VERSION "2021.24.4"

NS_ :

BS_:

BU_: VEH CH Receiver X

BA_DEF_ BO_ "GenMsgSendType" ENUM "Cyclic";
BA_DEF_ BO_ "GenMsgCycleTime" INT 0 10000;

BO_ 1373 VCLEFT_alertLog: 8 Vector__XXX
 SG_ VCLEFT_a058_faultReason m58 : 63|1@1+ (1,0) [0|0] "" Vector__XXX
 SG_ VCLEFT_a150_treatedInGear m150 : 63|1@1+ (1,0) [0|0] "" Vector__XXX
 SG_ VCLEFT_a151_treatedInGear m151 : 63|1@1+ (1,0) [0|0] "" Vector__XXX
 SG_ VCLEFT_a381_earlyReport m381 : 63|1@1+ (1,0) [0|0] "" Vector__XXX
 SG_ VCLEFT_a173_btnTimeMsAutoDownRR m173 : 60|4@1+ (50,0) [0|0] "" Vector__XXX
 SG_ VCLEFT_a351_shadowAlert m351 : 60|1@1+ (1,0) [0|0] "" Vector__XXX
 SG_ VCLEFT_a381_alertVersion m381 : 60|3@1+ (1,0) [0|0] "" Vector__XXX
 SG_ VCLEFT_a383_motorType m383 : 60|2@1+ (1,0) [0|0] "" Vector__XXX
 SG_ VCLEFT_a384_motorType m384 : 60|2@1+ (1,0) [0|0] "" Vector__XXX
 SG_ VCLEFT_a385_motorType m385 : 60|2@1+ (1,0) [0|0] "" Vector__XXX
 SG_ VCLEFT_a386_motorType m386 : 60|2@1+ (1,0) [0|0] "" Vector__XXX
 SG_ VCLEFT_a387_motorType m387 : 60|2@1+ (1,0) [0|0] "" Vector__XXX
 SG_ VCLEFT_a388_motorType m388 : 60|2@1+ (1,0) [0|0] "" Vector__XXX
 SG_ VCLEFT_a389_motorType m389 : 60|2@1+ (1,0) [0|0] "" Vector__XXX
 SG_ VCLEFT_a390_motorType m390 : 60|2@1+ (1,0) [0|0] "" Vector__XXX
 SG_ VCLEFT_a166_SHORT_RISE_FAILED_EN m166 : 59|1@1+ (1,0) [0|0] "" Vector__XXX
 SG_ VCLEFT_a481_currentSenseFailure m481 : 59|1@1+ (1,0) [0|0] "" Vector__XXX
 SG_ VCLEFT_a166_ENC_LOSS_SHORT_DROP m166 : 58|1@1+ (1,0) [0|0] "" Vector__XXX
 SG_ VCLEFT_a192_motorType m192 : 58|2@1+ (1,0) [0|0] "" Vector__XXX
 SG_ VCLEFT_a381_tireFitment m381 : 58|2@1+ (1,0) [0|0] "" Vector__XXX
 SG_ VCLEFT_a382_massEstimate m382 : 58|6@1+ (25,1900) [0|0] "" Vector__XXX
 SG_ VCLEFT_a481_currentSenseFinished m481 : 58|1@1+ (1,0) [0|0] "" Vector__XXX
 SG_ VCLEFT_a499_cdpUncommanedActuati m499 : 58|1@1+ (1,0) [0|0] "" Vector__XXX
 SG_ VCLEFT_a066_shortPeriodLength3 m66 : 57|7@1+ (10,0) [0|0] "" Vector__XXX
 SG_ VCLEFT_a150_speedExpScore m150 : 57|6@1- (0.0006451612903225806,-0.009677419354838708) [0|0] "" Vector__XXX
 SG_ VCLEFT_a151_speedExpScore m151 : 57|6@1- (0.0006451612903225806,-0.009677419354838708) [0|0] "" Vector__XXX
 SG_ VCLEFT_a166_AUTO_DOWN_HELD m166 : 57|1@1+ (1,0) [0|0] "" Vector__XXX
 SG_ VCLEFT_a192_motorNotIdentified m192 : 57|1@1+ (1,0) [0|0] "" Vector__XXX
 SG_ VCLEFT_a499_cdpEpbDynamicFault m499 : 57|1@1+ (1,0) [0|0] "" Vector__XXX
 SG_ VCLEFT_a022_TaskInitError4 m22 : 56|8@1+ (1,0) [0|0] "" Vector__XXX
 SG_ VCLEFT_a031_uds_bytes_5 m31 : 56|8@1+ (1,0) [0|0] "" Vector__XXX
 SG_ VCLEFT_a041_CPULoadNVMMTask m41 : 56|8@1+ (1,0) [0|0] "" Vector__XXX
 SG_ VCLEFT_a042_UsageNVMMTask m42 : 56|8@1+ (1,0) [0|0] "" Vector__XXX
 SG_ VCLEFT_a166_SOFT_STOP_OVERRIDE m166 : 56|1@1+ (1,0) [0|0] "" Vector__XXX
 SG_ VCLEFT_a173_btnTimeMsDownRR m173 : 56|4@1+ (50,0) [0|0] "" Vector__XXX
 SG_ VCLEFT_a192_payloadBitsNotSet m192 : 56|1@1+ (1,0) [0|0] "" Vector__XXX
 SG_ VCLEFT_a316_ambientTemperatureDe m316 : 56|8@1+ (0.5,-40) [0|0] "" Vector__XXX
 SG_ VCLEFT_a362_alertWhileMoving m362 : 56|1@1+ (1,0) [0|0] "" Vector__XXX
 SG_ VCLEFT_a393_anyClosureOpen m393 : 56|1@1+ (1,0) [0|0] "" Vector__XXX
 SG_ VCLEFT_a499_cdpNoParkButtonTimeo m499 : 56|1@1+ (1,0) [0|0] "" Vector__XXX
 SG_ VCLEFT_a523_control3Byte3 m523 : 56|8@1+ (1,0) [0|0] "" Vector__XXX
 SG_ VCLEFT_a546_ambientTemperature m546 : 56|8@1+ (0.5,-40) [0|0] "" Vector__XXX
 SG_ VCLEFT_a166_CAL_CLEAR_ENC_LOSS m166 : 55|1@1+ (1,0) [0|0] "" Vector__XXX
 SG_ VCLEFT_a393_deltaTrackingValidit m393 : 55|1@1+ (1,0) [0|0] "" Vector__XXX
 SG_ VCLEFT_a499_cdpValidActivationFa m499 : 55|1@1+ (1,0) [0|0] "" Vector__XXX
 SG_ VCLEFT_a166_SHORT_DROP_FAILED m166 : 54|1@1+ (1,0) [0|0] "" Vector__XXX
 SG_ VCLEFT_a360_instantAngle m360 : 54|10@1+ (1e-05,0) [0|0] "" Vector__XXX
 SG_ VCLEFT_a393_fusionValidityOK m393 : 54|1@1+ (1,0) [0|0] "" Vector__XXX
 SG_ VCLEFT_a499_parkButtonPressed m499 : 54|1@1+ (1,0) [0|0] "" Vector__XXX
 SG_ VCLEFT_a113_VEH_hvacDebugControl m113 : 53|1@1+ (1,0) [0|0] "" Vector__XXX
 SG_ VCLEFT_a166_PINCH_TABLE_REJECTED m166 : 53|1@1+ (1,0) [0|0] "" Vector__XXX
 SG_ VCLEFT_a192_lsVdsOvervoltageMask m192 : 53|3@1+ (1,0) [0|0] "" Vector__XXX
 SG_ VCLEFT_a200_phantomTicks m200 : 53|11@1- (1,0) [0|0] "" Vector__XXX
 SG_ VCLEFT_a499_remoteEpbmEpbDynamic m499 : 53|1@1+ (1,0) [0|0] "" Vector__XXX
 SG_ VCLEFT_a113_VEH_weatherDataServi m113 : 52|1@1+ (1,0) [0|0] "" Vector__XXX
 SG_ VCLEFT_a166_INT_SWITCH_IGNORED m166 : 52|1@1+ (1,0) [0|0] "" Vector__XXX
 SG_ VCLEFT_a173_btnTimeMsAutoDownRF m173 : 52|4@1+ (50,0) [0|0] "" Vector__XXX
 SG_ VCLEFT_a180_latchClawStatus m180 : 52|1@1+ (1,0) [0|0] "" Vector__XXX
 SG_ VCLEFT_a181_latchClawStatus m181 : 52|1@1+ (1,0) [0|0] "" Vector__XXX
 SG_ VCLEFT_a192_lsVdsOvervoltage m192 : 52|1@1+ (1,0) [0|0] "" Vector__XXX
 SG_ VCLEFT_a218_motorDutyCycle m218 : 52|10@1+ (0.1,0) [0|0] "" Vector__XXX
 SG_ VCLEFT_a236_lumbarBState m236 : 52|3@1+ (1,0) [0|0] "" Vector__XXX
 SG_ VCLEFT_a237_lumbarBState m237 : 52|3@1+ (1,0) [0|0] "" Vector__XXX
 SG_ VCLEFT_a238_lumbarBState m238 : 52|3@1+ (1,0) [0|0] "" Vector__XXX
 SG_ VCLEFT_a263_seatMotorState m263 : 52|3@1+ (1,0) [0|0] "" Vector__XXX
 SG_ VCLEFT_a264_seatMotorState m264 : 52|3@1+ (1,0) [0|0] "" Vector__XXX
 SG_ VCLEFT_a265_seatMotorState m265 : 52|3@1+ (1,0) [0|0] "" Vector__XXX
 SG_ VCLEFT_a266_seatMotorState m266 : 52|3@1+ (1,0) [0|0] "" Vector__XXX
 SG_ VCLEFT_a267_seatMotorState m267 : 52|3@1+ (1,0) [0|0] "" Vector__XXX
 SG_ VCLEFT_a268_seatMotorState m268 : 52|3@1+ (1,0) [0|0] "" Vector__XXX
 SG_ VCLEFT_a269_seatMotorState m269 : 52|3@1+ (1,0) [0|0] "" Vector__XXX
 SG_ VCLEFT_a270_seatMotorState m270 : 52|3@1+ (1,0) [0|0] "" Vector__XXX
 SG_ VCLEFT_a323_calibrationDown m323 : 52|12@1+ (0.002,0) [0|0] "" Vector__XXX
 SG_ VCLEFT_a351_ambientTemperature m351 : 52|8@1+ (0.5,-40) [0|0] "" Vector__XXX
 SG_ VCLEFT_a426_cabinTmp m426 : 52|12@1- (0.1,0) [0|0] "" Vector__XXX
 SG_ VCLEFT_a427_cabinTmp m427 : 52|12@1- (0.1,0) [0|0] "" Vector__XXX
 SG_ VCLEFT_a428_cabinTmp m428 : 52|12@1- (0.1,0) [0|0] "" Vector__XXX
 SG_ VCLEFT_a429_cabinTmp m429 : 52|12@1- (0.1,0) [0|0] "" Vector__XXX
 SG_ VCLEFT_a499_localEpbmEpbDynamic m499 : 52|1@1+ (1,0) [0|0] "" Vector__XXX
 SG_ VCLEFT_a058_newREstimate m58 : 51|12@1+ (0.00061,0) [0|0] "" Vector__XXX
 SG_ VCLEFT_a113_VEH_frontSeatRequest m113 : 51|1@1+ (1,0) [0|0] "" Vector__XXX
 SG_ VCLEFT_a166_REAR_SWITCH_IGNORED m166 : 51|1@1+ (1,0) [0|0] "" Vector__XXX
 SG_ VCLEFT_a444_enableLow m444 : 51|1@1+ (1,0) [0|0] "" Vector__XXX
 SG_ VCLEFT_a499_espCdpActuating m499 : 51|1@1+ (1,0) [0|0] "" Vector__XXX
 SG_ VCLEFT_a066_shortPeriodLength2 m66 : 50|7@1+ (10,0) [0|0] "" Vector__XXX
 SG_ VCLEFT_a113_VEH_odo m113 : 50|1@1+ (1,0) [0|0] "" Vector__XXX
 SG_ VCLEFT_a228_seatSwitchForward m228 : 50|2@1+ (1,0) [0|0] "" Vector__XXX
 SG_ VCLEFT_a229_seatSwitchForward m229 : 50|2@1+ (1,0) [0|0] "" Vector__XXX
 SG_ VCLEFT_a230_seatSwitchForward m230 : 50|2@1+ (1,0) [0|0] "" Vector__XXX
 SG_ VCLEFT_a231_seatSwitchForward m231 : 50|2@1+ (1,0) [0|0] "" Vector__XXX
 SG_ VCLEFT_a426_seatSwitchForward m426 : 50|2@1+ (1,0) [0|0] "" Vector__XXX
 SG_ VCLEFT_a427_seatSwitchForward m427 : 50|2@1+ (1,0) [0|0] "" Vector__XXX
 SG_ VCLEFT_a428_seatSwitchForward m428 : 50|2@1+ (1,0) [0|0] "" Vector__XXX
 SG_ VCLEFT_a429_seatSwitchForward m429 : 50|2@1+ (1,0) [0|0] "" Vector__XXX
 SG_ VCLEFT_a444_voltageMonitor m444 : 50|1@1+ (1,0) [0|0] "" Vector__XXX
 SG_ VCLEFT_a481_currentSenseVoltageD m481 : 50|8@1+ (1,0) [0|0] "" Vector__XXX
 SG_ VCLEFT_a499_remoteEpbmCdpOkay m499 : 50|1@1+ (1,0) [0|0] "" Vector__XXX
 SG_ VCLEFT_a104_BDY_bodyControls m104 : 49|1@1+ (1,0) [0|0] "" Vector__XXX
 SG_ VCLEFT_a113_CH_vehicleControl2 m113 : 49|1@1+ (1,0) [0|0] "" Vector__XXX
 SG_ VCLEFT_a150_relAccelExceedance m150 : 49|8@1+ (0.09803921568627451,0) [0|0] "" Vector__XXX
 SG_ VCLEFT_a151_relAccelExceedance m151 : 49|8@1+ (0.09803921568627451,0) [0|0] "" Vector__XXX
 SG_ VCLEFT_a192_hsVdsOvervoltageMask m192 : 49|3@1+ (1,0) [0|0] "" Vector__XXX
 SG_ VCLEFT_a236_lumbarAState m236 : 49|3@1+ (1,0) [0|0] "" Vector__XXX
 SG_ VCLEFT_a237_lumbarAState m237 : 49|3@1+ (1,0) [0|0] "" Vector__XXX
 SG_ VCLEFT_a238_lumbarAState m238 : 49|3@1+ (1,0) [0|0] "" Vector__XXX
 SG_ VCLEFT_a381_timeElapsed m381 : 49|9@1+ (1,0) [0|0] "" Vector__XXX
 SG_ VCLEFT_a382_axOffset m382 : 49|9@1- (0.004,0) [0|0] "" Vector__XXX
 SG_ VCLEFT_a444_spiFault m444 : 49|1@1+ (1,0) [0|0] "" Vector__XXX
 SG_ VCLEFT_a481_softShortThresholdRe m481 : 49|1@1+ (1,0) [0|0] "" Vector__XXX
 SG_ VCLEFT_a499_localEpbmCdpOkay m499 : 49|1@1+ (1,0) [0|0] "" Vector__XXX
 SG_ VCLEFT_a000_alertDataW2 m0 : 48|16@1+ (1,0) [0|0] "" Vector__XXX
 SG_ VCLEFT_a003_Data m3 : 48|16@1+ (1,0) [0|0] "" Vector__XXX
 SG_ VCLEFT_a022_TaskInitError3 m22 : 48|8@1+ (1,0) [0|0] "" Vector__XXX
 SG_ VCLEFT_a031_uds_bytes_4 m31 : 48|8@1+ (1,0) [0|0] "" Vector__XXX
 SG_ VCLEFT_a041_CPULoad1000msTask m41 : 48|8@1+ (1,0) [0|0] "" Vector__XXX
 SG_ VCLEFT_a042_UsageUDSTask m42 : 48|8@1+ (1,0) [0|0] "" Vector__XXX
 SG_ VCLEFT_a104_VEH_redundantBraking m104 : 48|1@1+ (1,0) [0|0] "" Vector__XXX
 SG_ VCLEFT_a113_VEH_driverAssistMapD m113 : 48|1@1+ (1,0) [0|0] "" Vector__XXX
 SG_ VCLEFT_a120_BDY_speed m120 : 48|1@1+ (1,0) [0|0] "" Vector__XXX
 SG_ VCLEFT_a164_calibratedVoltage m164 : 48|6@1+ (0.25,0) [0|0] "" Vector__XXX
 SG_ VCLEFT_a167_pinchV3InUse m167 : 48|1@1+ (1,0) [0|0] "" Vector__XXX
 SG_ VCLEFT_a168_pinchV3InUse m168 : 48|1@1+ (1,0) [0|0] "" Vector__XXX
 SG_ VCLEFT_a173_btnTimeMsDownRF m173 : 48|4@1+ (50,0) [0|0] "" Vector__XXX
 SG_ VCLEFT_a180_latchStatus m180 : 48|4@1+ (1,0) [0|0] "" Vector__XXX
 SG_ VCLEFT_a181_latchStatus m181 : 48|4@1+ (1,0) [0|0] "" Vector__XXX
 SG_ VCLEFT_a192_hsVdsOvervoltage m192 : 48|1@1+ (1,0) [0|0] "" Vector__XXX
 SG_ VCLEFT_a202_epbConfig m202 : 48|4@1+ (1,0) [0|0] "" Vector__XXX
 SG_ VCLEFT_a203_epbConfig m203 : 48|4@1+ (1,0) [0|0] "" Vector__XXX
 SG_ VCLEFT_a204_epbConfig m204 : 48|4@1+ (1,0) [0|0] "" Vector__XXX
 SG_ VCLEFT_a205_epbConfig m205 : 48|4@1+ (1,0) [0|0] "" Vector__XXX
 SG_ VCLEFT_a211_epbConfig m211 : 48|4@1+ (1,0) [0|0] "" Vector__XXX
 SG_ VCLEFT_a212_epbConfig m212 : 48|4@1+ (1,0) [0|0] "" Vector__XXX
 SG_ VCLEFT_a213_epbConfig m213 : 48|4@1+ (1,0) [0|0] "" Vector__XXX
 SG_ VCLEFT_a214_epbConfig m214 : 48|4@1+ (1,0) [0|0] "" Vector__XXX
 SG_ VCLEFT_a216_byte3 m216 : 48|8@1+ (1,0) [0|0] "" Vector__XXX
 SG_ VCLEFT_a228_seatSwitchBack m228 : 48|2@1+ (1,0) [0|0] "" Vector__XXX
 SG_ VCLEFT_a229_seatSwitchBack m229 : 48|2@1+ (1,0) [0|0] "" Vector__XXX
 SG_ VCLEFT_a230_seatSwitchBack m230 : 48|2@1+ (1,0) [0|0] "" Vector__XXX
 SG_ VCLEFT_a231_seatSwitchBack m231 : 48|2@1+ (1,0) [0|0] "" Vector__XXX
 SG_ VCLEFT_a236_lumbarDiagStatus m236 : 48|1@1+ (1,0) [0|0] "" Vector__XXX
 SG_ VCLEFT_a237_lumbarDiagStatus m237 : 48|1@1+ (1,0) [0|0] "" Vector__XXX
 SG_ VCLEFT_a238_lumbarDiagStatus m238 : 48|1@1+ (1,0) [0|0] "" Vector__XXX
 SG_ VCLEFT_a321_maxCurrent m321 : 48|7@1+ (0.25,0) [0|0] "" Vector__XXX
 SG_ VCLEFT_a322_maxCurrent m322 : 48|7@1+ (0.25,0) [0|0] "" Vector__XXX
 SG_ VCLEFT_a325_PWMfaultFL m325 : 48|4@1+ (1,0) [0|0] "" Vector__XXX
 SG_ VCLEFT_a326_PWMfaultRL m326 : 48|4@1+ (1,0) [0|0] "" Vector__XXX
 SG_ VCLEFT_a327_PWMfaultFL m327 : 48|4@1+ (1,0) [0|0] "" Vector__XXX
 SG_ VCLEFT_a328_PWMfaultRL m328 : 48|4@1+ (1,0) [0|0] "" Vector__XXX
 SG_ VCLEFT_a345_powerCycleCount m345 : 48|12@1+ (1,0) [0|0] "" Vector__XXX
 SG_ VCLEFT_a351_liftgateLastState m351 : 48|4@1+ (1,0) [0|0] "" Vector__XXX
 SG_ VCLEFT_a352_liftgateClosingFaile m352 : 48|16@1+ (1,0) [0|0] "" Vector__XXX
 SG_ VCLEFT_a356_lastActiveState m356 : 48|3@1+ (1,0) [0|0] "" Vector__XXX
 SG_ VCLEFT_a391_pitchEstimateIMU m391 : 48|7@1- (0.001,0) [0|0] "" Vector__XXX
 SG_ VCLEFT_a393_gpsAccuracyRecent m393 : 48|6@1+ (0.2,0) [0|0] "" Vector__XXX
 SG_ VCLEFT_a426_seatSwitchBack m426 : 48|2@1+ (1,0) [0|0] "" Vector__XXX
 SG_ VCLEFT_a427_seatSwitchBack m427 : 48|2@1+ (1,0) [0|0] "" Vector__XXX
 SG_ VCLEFT_a428_seatSwitchBack m428 : 48|2@1+ (1,0) [0|0] "" Vector__XXX
 SG_ VCLEFT_a429_seatSwitchBack m429 : 48|2@1+ (1,0) [0|0] "" Vector__XXX
 SG_ VCLEFT_a444_spiPeriodicCheck m444 : 48|1@1+ (1,0) [0|0] "" Vector__XXX
 SG_ VCLEFT_a445_actualLSB m445 : 48|8@1+ (1,0) [0|0] "" Vector__XXX
 SG_ VCLEFT_a481_hardShortThresholdRe m481 : 48|1@1+ (1,0) [0|0] "" Vector__XXX
 SG_ VCLEFT_a499_anyCdpRequest m499 : 48|1@1+ (1,0) [0|0] "" Vector__XXX
 SG_ VCLEFT_a523_control3Byte2 m523 : 48|8@1+ (1,0) [0|0] "" Vector__XXX
 SG_ VCLEFT_a551_lastRequestSourceRea m551 : 48|3@1+ (1,0) [0|0] "" Vector__XXX
 SG_ VCLEFT_a104_VEH_control m104 : 47|1@1+ (1,0) [0|0] "" Vector__XXX
 SG_ VCLEFT_a113_VEH_ambientLightingC m113 : 47|1@1+ (1,0) [0|0] "" Vector__XXX
 SG_ VCLEFT_a120_VEH_motorStatus m120 : 47|1@1+ (1,0) [0|0] "" Vector__XXX
 SG_ VCLEFT_a192_busVoltageUnhealthy m192 : 47|1@1+ (1,0) [0|0] "" Vector__XXX
 SG_ VCLEFT_a356_STOPPING_CONDITION_M m356 : 47|1@1+ (1,0) [0|0] "" Vector__XXX
 SG_ VCLEFT_a444_spiInit m444 : 47|1@1+ (1,0) [0|0] "" Vector__XXX
 SG_ VCLEFT_a481_stuckOnFailure m481 : 47|1@1+ (1,0) [0|0] "" Vector__XXX
 SG_ VCLEFT_a499_faultForBootTimeout m499 : 47|1@1+ (1,0) [0|0] "" Vector__XXX
 SG_ VCLEFT_a104_VEH_wirelessCharging m104 : 46|1@1+ (1,0) [0|0] "" Vector__XXX
 SG_ VCLEFT_a113_VEH_autopilotControl m113 : 46|1@1+ (1,0) [0|0] "" Vector__XXX
 SG_ VCLEFT_a120_PARTY_motorStatus m120 : 46|1@1+ (1,0) [0|0] "" Vector__XXX
 SG_ VCLEFT_a192_vddaOvercurrent m192 : 46|1@1+ (1,0) [0|0] "" Vector__XXX
 SG_ VCLEFT_a200_motorPosition m200 : 46|7@1+ (20,0) [0|0] "" Vector__XXX
 SG_ VCLEFT_a356_UNEXPECTED_REQUEST m356 : 46|1@1+ (1,0) [0|0] "" Vector__XXX
 SG_ VCLEFT_a444_lowSide1OverCurent m444 : 46|1@1+ (1,0) [0|0] "" Vector__XXX
 SG_ VCLEFT_a481_stuckOnFinished m481 : 46|1@1+ (1,0) [0|0] "" Vector__XXX
 SG_ VCLEFT_a499_bootTimeExpired m499 : 46|1@1+ (1,0) [0|0] "" Vector__XXX
 SG_ VCLEFT_a104_BDY_autonomyControl m104 : 45|1@1+ (1,0) [0|0] "" Vector__XXX
 SG_ VCLEFT_a113_VEH_status2 m113 : 45|1@1+ (1,0) [0|0] "" Vector__XXX
 SG_ VCLEFT_a120_VEH_vehicleEstimates m120 : 45|1@1+ (1,0) [0|0] "" Vector__XXX
 SG_ VCLEFT_a192_phaseOvercurrent m192 : 45|1@1+ (1,0) [0|0] "" Vector__XXX
 SG_ VCLEFT_a200_encoderEnabled m200 : 45|1@1+ (1,0) [0|0] "" Vector__XXX
 SG_ VCLEFT_a232_seatSwitchForward m232 : 45|2@1+ (1,0) [0|0] "" Vector__XXX
 SG_ VCLEFT_a233_seatSwitchForward m233 : 45|2@1+ (1,0) [0|0] "" Vector__XXX
 SG_ VCLEFT_a234_seatSwitchForward m234 : 45|2@1+ (1,0) [0|0] "" Vector__XXX
 SG_ VCLEFT_a235_seatSwitchForward m235 : 45|2@1+ (1,0) [0|0] "" Vector__XXX
 SG_ VCLEFT_a251_seatSwitchForward m251 : 45|2@1+ (1,0) [0|0] "" Vector__XXX
 SG_ VCLEFT_a252_seatSwitchForward m252 : 45|2@1+ (1,0) [0|0] "" Vector__XXX
 SG_ VCLEFT_a253_seatSwitchForward m253 : 45|2@1+ (1,0) [0|0] "" Vector__XXX
 SG_ VCLEFT_a254_seatSwitchForward m254 : 45|2@1+ (1,0) [0|0] "" Vector__XXX
 SG_ VCLEFT_a356_STATE_TIMEOUT_TEST m356 : 45|1@1+ (1,0) [0|0] "" Vector__XXX
 SG_ VCLEFT_a444_highSide1OverCurent m444 : 45|1@1+ (1,0) [0|0] "" Vector__XXX
 SG_ VCLEFT_a499_okayToRequalifyCdp m499 : 45|1@1+ (1,0) [0|0] "" Vector__XXX
 SG_ VCLEFT_a104_CH_autonomyControl m104 : 44|1@1+ (1,0) [0|0] "" Vector__XXX
 SG_ VCLEFT_a113_VEH_gpsVehicleSpeed m113 : 44|1@1+ (1,0) [0|0] "" Vector__XXX
 SG_ VCLEFT_a118_PARTY_VCFRONT_camera m118 : 44|1@1+ (1,0) [0|0] "" Vector__XXX
 SG_ VCLEFT_a120_VEH_prndControl m120 : 44|1@1+ (1,0) [0|0] "" Vector__XXX
 SG_ VCLEFT_a173_btnTimeMsAutoDownLR m173 : 44|4@1+ (50,0) [0|0] "" Vector__XXX
 SG_ VCLEFT_a192_motorSpeedTooHigh m192 : 44|1@1+ (1,0) [0|0] "" Vector__XXX
 SG_ VCLEFT_a228_seatMotorState m228 : 44|3@1+ (1,0) [0|0] "" Vector__XXX
 SG_ VCLEFT_a229_seatMotorState m229 : 44|3@1+ (1,0) [0|0] "" Vector__XXX
 SG_ VCLEFT_a230_seatMotorState m230 : 44|3@1+ (1,0) [0|0] "" Vector__XXX
 SG_ VCLEFT_a231_seatMotorState m231 : 44|3@1+ (1,0) [0|0] "" Vector__XXX
 SG_ VCLEFT_a316_averageCurrentAmps m316 : 44|12@1+ (0.01,0) [0|0] "" Vector__XXX
 SG_ VCLEFT_a356_STATE_TIMEOUT_PLG m356 : 44|1@1+ (1,0) [0|0] "" Vector__XXX
 SG_ VCLEFT_a360_instantAccel m360 : 44|10@1+ (0.002,0) [0|0] "" Vector__XXX
 SG_ VCLEFT_a383_savedEndstopPosition m383 : 44|16@1- (0.01,0) [0|0] "" Vector__XXX
 SG_ VCLEFT_a384_savedEndstopPosition m384 : 44|16@1- (0.01,0) [0|0] "" Vector__XXX
 SG_ VCLEFT_a385_savedEndstopPosition m385 : 44|16@1- (0.01,0) [0|0] "" Vector__XXX
 SG_ VCLEFT_a386_savedEndstopPosition m386 : 44|16@1- (0.01,0) [0|0] "" Vector__XXX
 SG_ VCLEFT_a387_savedEndstopPosition m387 : 44|16@1- (0.01,0) [0|0] "" Vector__XXX
 SG_ VCLEFT_a388_savedEndstopPosition m388 : 44|16@1- (0.01,0) [0|0] "" Vector__XXX
 SG_ VCLEFT_a389_savedEndstopPosition m389 : 44|16@1- (0.01,0) [0|0] "" Vector__XXX
 SG_ VCLEFT_a390_savedEndstopPosition m390 : 44|16@1- (0.01,0) [0|0] "" Vector__XXX
 SG_ VCLEFT_a426_seatMotorState m426 : 44|3@1+ (1,0) [0|0] "" Vector__XXX
 SG_ VCLEFT_a427_seatMotorState m427 : 44|3@1+ (1,0) [0|0] "" Vector__XXX
 SG_ VCLEFT_a428_seatMotorState m428 : 44|3@1+ (1,0) [0|0] "" Vector__XXX
 SG_ VCLEFT_a429_seatMotorState m429 : 44|3@1+ (1,0) [0|0] "" Vector__XXX
 SG_ VCLEFT_a444_lowSide2OverCurent m444 : 44|1@1+ (1,0) [0|0] "" Vector__XXX
 SG_ VCLEFT_a063_faulted m63 : 43|1@1+ (1,0) [0|0] "" Vector__XXX
 SG_ VCLEFT_a066_shortPeriodLength1 m66 : 43|7@1+ (10,0) [0|0] "" Vector__XXX
 SG_ VCLEFT_a104_VEH_autonomyControl m104 : 43|1@1+ (1,0) [0|0] "" Vector__XXX
 SG_ VCLEFT_a113_VEH_gpsTime m113 : 43|1@1+ (1,0) [0|0] "" Vector__XXX
 SG_ VCLEFT_a118_BDY_AP_vehicleState1 m118 : 43|1@1+ (1,0) [0|0] "" Vector__XXX
 SG_ VCLEFT_a120_VEH_locStatus2 m120 : 43|1@1+ (1,0) [0|0] "" Vector__XXX
 SG_ VCLEFT_a166_sealPos m166 : 43|8@1+ (1,0) [0|0] "" Vector__XXX
 SG_ VCLEFT_a192_chipOvertemp m192 : 43|1@1+ (1,0) [0|0] "" Vector__XXX
 SG_ VCLEFT_a232_seatSwitchBack m232 : 43|2@1+ (1,0) [0|0] "" Vector__XXX
 SG_ VCLEFT_a233_seatSwitchBack m233 : 43|2@1+ (1,0) [0|0] "" Vector__XXX
 SG_ VCLEFT_a234_seatSwitchBack m234 : 43|2@1+ (1,0) [0|0] "" Vector__XXX
 SG_ VCLEFT_a235_seatSwitchBack m235 : 43|2@1+ (1,0) [0|0] "" Vector__XXX
 SG_ VCLEFT_a251_seatSwitchBack m251 : 43|2@1+ (1,0) [0|0] "" Vector__XXX
 SG_ VCLEFT_a252_seatSwitchBack m252 : 43|2@1+ (1,0) [0|0] "" Vector__XXX
 SG_ VCLEFT_a253_seatSwitchBack m253 : 43|2@1+ (1,0) [0|0] "" Vector__XXX
 SG_ VCLEFT_a254_seatSwitchBack m254 : 43|2@1+ (1,0) [0|0] "" Vector__XXX
 SG_ VCLEFT_a356_OBSTACLE_DETECTED m356 : 43|1@1+ (1,0) [0|0] "" Vector__XXX
 SG_ VCLEFT_a376_2RowSeatTrackPositio m376 : 43|2@1+ (1,0) [0|0] "" Vector__XXX
 SG_ VCLEFT_a444_highSide2OverCurent m444 : 43|1@1+ (1,0) [0|0] "" Vector__XXX
 SG_ VCLEFT_a063_stuckActive m63 : 42|1@1+ (1,0) [0|0] "" Vector__XXX
 SG_ VCLEFT_a104_PARTY_autonomyContro m104 : 42|1@1+ (1,0) [0|0] "" Vector__XXX
 SG_ VCLEFT_a113_VEH_locationStatus m113 : 42|1@1+ (1,0) [0|0] "" Vector__XXX
 SG_ VCLEFT_a118_PARTY_AP_vehicleStat m118 : 42|1@1+ (1,0) [0|0] "" Vector__XXX
 SG_ VCLEFT_a120_VEH_locStatus m120 : 42|1@1+ (1,0) [0|0] "" Vector__XXX
 SG_ VCLEFT_a129_VGS_LC m129 : 42|1@1+ (1,0) [0|0] "" Vector__XXX
 SG_ VCLEFT_a192_motorPhaseCurrentIrr m192 : 42|1@1+ (1,0) [0|0] "" Vector__XXX
 SG_ VCLEFT_a218_motorCurrent m218 : 42|10@1- (0.04,0) [0|0] "" Vector__XXX
 SG_ VCLEFT_a350_ensTimedOut m350 : 42|1@1+ (1,0) [0|0] "" Vector__XXX
 SG_ VCLEFT_a356_FAIL_CLOSING m356 : 42|1@1+ (1,0) [0|0] "" Vector__XXX
 SG_ VCLEFT_a444_lowSide1GateDriver m444 : 42|1@1+ (1,0) [0|0] "" Vector__XXX
 SG_ VCLEFT_a063_indeterminate m63 : 41|1@1+ (1,0) [0|0] "" Vector__XXX
 SG_ VCLEFT_a104_BDY_status m104 : 41|1@1+ (1,0) [0|0] "" Vector__XXX
 SG_ VCLEFT_a113_CH_odo m113 : 41|1@1+ (1,0) [0|0] "" Vector__XXX
 SG_ VCLEFT_a118_BDY_vehicleTime m118 : 41|1@1+ (1,0) [0|0] "" Vector__XXX
 SG_ VCLEFT_a120_CH_locStatus2 m120 : 41|1@1+ (1,0) [0|0] "" Vector__XXX
 SG_ VCLEFT_a129_VGS_HC m129 : 41|1@1+ (1,0) [0|0] "" Vector__XXX
 SG_ VCLEFT_a150_absAccelExceedance m150 : 41|8@1+ (0.09803921568627451,0) [0|0] "" Vector__XXX
 SG_ VCLEFT_a151_absAccelExceedance m151 : 41|8@1+ (0.09803921568627451,0) [0|0] "" Vector__XXX
 SG_ VCLEFT_a192_supplyVoltageIrratio m192 : 41|1@1+ (1,0) [0|0] "" Vector__XXX
 SG_ VCLEFT_a241_backrest m241 : 41|1@1+ (1,0) [0|0] "" Vector__XXX
 SG_ VCLEFT_a244_backrest m244 : 41|1@1+ (1,0) [0|0] "" Vector__XXX
 SG_ VCLEFT_a247_backrest m247 : 41|1@1+ (1,0) [0|0] "" Vector__XXX
 SG_ VCLEFT_a250_backrest m250 : 41|1@1+ (1,0) [0|0] "" Vector__XXX
 SG_ VCLEFT_a356_FAIL_OPENING m356 : 41|1@1+ (1,0) [0|0] "" Vector__XXX
 SG_ VCLEFT_a444_highSide1GateDriver m444 : 41|1@1+ (1,0) [0|0] "" Vector__XXX
 SG_ VCLEFT_a546_mirrorFoldTime m546 : 41|9@1+ (10,0) [0|0] "" Vector__XXX
 SG_ VCLEFT_a022_TaskInitError2 m22 : 40|8@1+ (1,0) [0|0] "" Vector__XXX
 SG_ VCLEFT_a031_uds_bytes_3 m31 : 40|8@1+ (1,0) [0|0] "" Vector__XXX
 SG_ VCLEFT_a041_CPULoad100msTask m41 : 40|8@1+ (1,0) [0|0] "" Vector__XXX
 SG_ VCLEFT_a042_Usage1000msTask m42 : 40|8@1+ (1,0) [0|0] "" Vector__XXX
 SG_ VCLEFT_a043_CallTrace1 m43 : 40|24@1+ (1,0) [0|0] "" Vector__XXX
 SG_ VCLEFT_a044_CallTrace1 m44 : 40|24@1+ (1,0) [0|0] "" Vector__XXX
 SG_ VCLEFT_a045_CallTrace1 m45 : 40|24@1+ (1,0) [0|0] "" Vector__XXX
 SG_ VCLEFT_a046_CallTrace1 m46 : 40|24@1+ (1,0) [0|0] "" Vector__XXX
 SG_ VCLEFT_a059_current m59 : 40|12@1+ (0.05,0) [0|0] "" Vector__XXX
 SG_ VCLEFT_a063_disconnected m63 : 40|1@1+ (1,0) [0|0] "" Vector__XXX
 SG_ VCLEFT_a104_BDY_control m104 : 40|1@1+ (1,0) [0|0] "" Vector__XXX
 SG_ VCLEFT_a113_VEH_vehicleControlTh m113 : 40|1@1+ (1,0) [0|0] "" Vector__XXX
 SG_ VCLEFT_a118_BDY_outputPowerStatu m118 : 40|1@1+ (1,0) [0|0] "" Vector__XXX
 SG_ VCLEFT_a120_VEH_chassisCntl m120 : 40|1@1+ (1,0) [0|0] "" Vector__XXX
 SG_ VCLEFT_a129_VGS_LB m129 : 40|1@1+ (1,0) [0|0] "" Vector__XXX
 SG_ VCLEFT_a164_downMovementTimeMs m164 : 40|7@1+ (50,0) [0|0] "" Vector__XXX
 SG_ VCLEFT_a165_lowerEndStopPosition m165 : 40|8@1+ (10,0) [0|0] "" Vector__XXX
 SG_ VCLEFT_a173_btnTimeMsDownLR m173 : 40|4@1+ (50,0) [0|0] "" Vector__XXX
 SG_ VCLEFT_a180_releasePWM m180 : 40|8@1+ (1,0) [0|0] "" Vector__XXX
 SG_ VCLEFT_a181_releasePWM m181 : 40|8@1+ (1,0) [0|0] "" Vector__XXX
 SG_ VCLEFT_a192_motorSpeedIrrational m192 : 40|1@1+ (1,0) [0|0] "" Vector__XXX
 SG_ VCLEFT_a206_unitStatusEPBM m206 : 40|5@1+ (1,0) [0|0] "" Vector__XXX
 SG_ VCLEFT_a207_unitStatusEPBM m207 : 40|5@1+ (1,0) [0|0] "" Vector__XXX
 SG_ VCLEFT_a208_unitStatusEPBM m208 : 40|5@1+ (1,0) [0|0] "" Vector__XXX
 SG_ VCLEFT_a209_unitStatusEPBM m209 : 40|5@1+ (1,0) [0|0] "" Vector__XXX
 SG_ VCLEFT_a210_unitStatusEPBM m210 : 40|5@1+ (1,0) [0|0] "" Vector__XXX
 SG_ VCLEFT_a216_byte2 m216 : 40|8@1+ (1,0) [0|0] "" Vector__XXX
 SG_ VCLEFT_a217_byte7 m217 : 40|8@1+ (1,0) [0|0] "" Vector__XXX
 SG_ VCLEFT_a232_seatMotorState m232 : 40|3@1+ (1,0) [0|0] "" Vector__XXX
 SG_ VCLEFT_a233_seatMotorState m233 : 40|3@1+ (1,0) [0|0] "" Vector__XXX
 SG_ VCLEFT_a234_seatMotorState m234 : 40|3@1+ (1,0) [0|0] "" Vector__XXX
 SG_ VCLEFT_a235_seatMotorState m235 : 40|3@1+ (1,0) [0|0] "" Vector__XXX
 SG_ VCLEFT_a239_seatHeatTmpTarget m239 : 40|8@1- (0.5,0) [0|0] "" Vector__XXX
 SG_ VCLEFT_a241_cushion m241 : 40|1@1+ (1,0) [0|0] "" Vector__XXX
 SG_ VCLEFT_a242_seatHeatTmpTarget m242 : 40|8@1- (0.5,0) [0|0] "" Vector__XXX
 SG_ VCLEFT_a244_cushion m244 : 40|1@1+ (1,0) [0|0] "" Vector__XXX
 SG_ VCLEFT_a245_seatHeatTmpTarget m245 : 40|8@1- (0.5,0) [0|0] "" Vector__XXX
 SG_ VCLEFT_a247_cushion m247 : 40|1@1+ (1,0) [0|0] "" Vector__XXX
 SG_ VCLEFT_a248_seatHeatTmpTarget m248 : 40|8@1- (0.5,0) [0|0] "" Vector__XXX
 SG_ VCLEFT_a250_cushion m250 : 40|1@1+ (1,0) [0|0] "" Vector__XXX
 SG_ VCLEFT_a251_seatMotorState m251 : 40|3@1+ (1,0) [0|0] "" Vector__XXX
 SG_ VCLEFT_a252_seatMotorState m252 : 40|3@1+ (1,0) [0|0] "" Vector__XXX
 SG_ VCLEFT_a253_seatMotorState m253 : 40|3@1+ (1,0) [0|0] "" Vector__XXX
 SG_ VCLEFT_a254_seatMotorState m254 : 40|3@1+ (1,0) [0|0] "" Vector__XXX
 SG_ VCLEFT_a263_seatMotorPosReal m263 : 40|12@1- (1,0) [0|0] "" Vector__XXX
 SG_ VCLEFT_a264_seatMotorPosReal m264 : 40|12@1- (1,0) [0|0] "" Vector__XXX
 SG_ VCLEFT_a265_seatMotorPosReal m265 : 40|12@1- (1,0) [0|0] "" Vector__XXX
 SG_ VCLEFT_a266_seatMotorPosReal m266 : 40|12@1- (1,0) [0|0] "" Vector__XXX
 SG_ VCLEFT_a267_seatMotorPosReal m267 : 40|12@1- (1,0) [0|0] "" Vector__XXX
 SG_ VCLEFT_a268_seatMotorPosReal m268 : 40|12@1- (1,0) [0|0] "" Vector__XXX
 SG_ VCLEFT_a269_seatMotorPosReal m269 : 40|12@1- (1,0) [0|0] "" Vector__XXX
 SG_ VCLEFT_a270_seatMotorPosReal m270 : 40|12@1- (1,0) [0|0] "" Vector__XXX
 SG_ VCLEFT_a284_measurementInterval m284 : 40|8@1+ (1,0) [0|0] "" Vector__XXX
 SG_ VCLEFT_a310_ambientTemperature m310 : 40|8@1+ (0.5,-40) [0|0] "" Vector__XXX
 SG_ VCLEFT_a323_calibrationUp m323 : 40|12@1+ (0.002,0) [0|0] "" Vector__XXX
 SG_ VCLEFT_a351_liftgatePosition m351 : 40|7@1- (1,43) [0|0] "" Vector__XXX
 SG_ VCLEFT_a355_ambientTemperature m355 : 40|8@1+ (0.5,-40) [0|0] "" Vector__XXX
 SG_ VCLEFT_a356_TEST_START_NOT_CLOSE m356 : 40|1@1+ (1,0) [0|0] "" Vector__XXX
 SG_ VCLEFT_a376_2RowSeatEasyEntrySta m376 : 40|3@1+ (1,0) [0|0] "" Vector__XXX
 SG_ VCLEFT_a391_massEstimate m391 : 40|6@1+ (25,1900) [0|0] "" Vector__XXX
 SG_ VCLEFT_a393_gpsAccuracyStart m393 : 40|6@1+ (0.2,0) [0|0] "" Vector__XXX
 SG_ VCLEFT_a444_lowSide2GateDriver m444 : 40|1@1+ (1,0) [0|0] "" Vector__XXX
 SG_ VCLEFT_a445_actualMSB m445 : 40|8@1+ (1,0) [0|0] "" Vector__XXX
 SG_ VCLEFT_a499_localEpbStatus m499 : 40|5@1+ (1,0) [0|0] "" Vector__XXX
 SG_ VCLEFT_a523_control2Byte3 m523 : 40|8@1+ (1,0) [0|0] "" Vector__XXX
 SG_ VCLEFT_a526_tempChangeRate m526 : 40|16@1- (0.125,55) [0|0] "" Vector__XXX
 SG_ VCLEFT_a546_mirrorFoldDirection m546 : 40|1@1+ (1,0) [0|0] "" Vector__XXX
 SG_ VCLEFT_a551_interiorReleaseReqCo m551 : 40|8@1+ (1,0) [0|0] "" Vector__XXX
 SG_ VCLEFT_a058_prevREstimate m58 : 39|12@1+ (0.00061,0) [0|0] "" Vector__XXX
 SG_ VCLEFT_a066_maxConsecutiveShortP m66 : 39|4@1+ (1,0) [0|0] "" Vector__XXX
 SG_ VCLEFT_a104_BDY_gpsAccuracies m104 : 39|1@1+ (1,0) [0|0] "" Vector__XXX
 SG_ VCLEFT_a113_VEH_vehicleControl3 m113 : 39|1@1+ (1,0) [0|0] "" Vector__XXX
 SG_ VCLEFT_a117_PARTY_lightingSecond m117 : 39|1@1+ (1,0) [0|0] "" Vector__XXX
 SG_ VCLEFT_a118_CH_alertMatrix m118 : 39|1@1+ (1,0) [0|0] "" Vector__XXX
 SG_ VCLEFT_a120_PARTY_locStatus2 m120 : 39|1@1+ (1,0) [0|0] "" Vector__XXX
 SG_ VCLEFT_a129_VGS_HB m129 : 39|1@1+ (1,0) [0|0] "" Vector__XXX
 SG_ VCLEFT_a175_relAccelTripped m175 : 39|1@1+ (1,0) [0|0] "" Vector__XXX
 SG_ VCLEFT_a176_relAccelTripped m176 : 39|1@1+ (1,0) [0|0] "" Vector__XXX
 SG_ VCLEFT_a192_dcCurrentIrrational m192 : 39|1@1+ (1,0) [0|0] "" Vector__XXX
 SG_ VCLEFT_a200_encoderVoltage m200 : 39|6@1+ (0.15,0) [0|0] "" Vector__XXX
 SG_ VCLEFT_a381_distanceTraveled m381 : 39|10@1+ (0.5,0) [0|0] "" Vector__XXX
 SG_ VCLEFT_a382_integrationDueToSpee m382 : 39|10@1- (8,0) [0|0] "" Vector__XXX
 SG_ VCLEFT_a444_highSide2GateDriver m444 : 39|1@1+ (1,0) [0|0] "" Vector__XXX
 SG_ VCLEFT_a480_enable m480 : 39|1@1+ (1,0) [0|0] "" Vector__XXX
 SG_ VCLEFT_a104_CH_pscControl m104 : 38|1@1+ (1,0) [0|0] "" Vector__XXX
 SG_ VCLEFT_a113_VEH_tripPlanning m113 : 38|1@1+ (1,0) [0|0] "" Vector__XXX
 SG_ VCLEFT_a117_PARTY_prndStatus m117 : 38|1@1+ (1,0) [0|0] "" Vector__XXX
 SG_ VCLEFT_a118_CH_LVBMS_statusHigh m118 : 38|1@1+ (1,0) [0|0] "" Vector__XXX
 SG_ VCLEFT_a120_PARTY_prndControl m120 : 38|1@1+ (1,0) [0|0] "" Vector__XXX
 SG_ VCLEFT_a129_VGS_LA m129 : 38|1@1+ (1,0) [0|0] "" Vector__XXX
 SG_ VCLEFT_a167_powerDeriv2Accum m167 : 38|10@1+ (1,0) [0|0] "" Vector__XXX
 SG_ VCLEFT_a168_powerDeriv2Accum m168 : 38|10@1+ (1,0) [0|0] "" Vector__XXX
 SG_ VCLEFT_a175_absAccelTripped m175 : 38|1@1+ (1,0) [0|0] "" Vector__XXX
 SG_ VCLEFT_a176_absAccelTripped m176 : 38|1@1+ (1,0) [0|0] "" Vector__XXX
 SG_ VCLEFT_a192_busVoltageIrrational m192 : 38|1@1+ (1,0) [0|0] "" Vector__XXX
 SG_ VCLEFT_a202_current m202 : 38|10@1+ (0.05,0) [0|0] "" Vector__XXX
 SG_ VCLEFT_a203_current m203 : 38|10@1+ (0.05,0) [0|0] "" Vector__XXX
 SG_ VCLEFT_a204_current m204 : 38|10@1+ (0.05,0) [0|0] "" Vector__XXX
 SG_ VCLEFT_a205_current m205 : 38|10@1+ (0.05,0) [0|0] "" Vector__XXX
 SG_ VCLEFT_a211_current m211 : 38|10@1+ (0.05,0) [0|0] "" Vector__XXX
 SG_ VCLEFT_a212_current m212 : 38|10@1+ (0.05,0) [0|0] "" Vector__XXX
 SG_ VCLEFT_a213_current m213 : 38|10@1+ (0.05,0) [0|0] "" Vector__XXX
 SG_ VCLEFT_a214_current m214 : 38|10@1+ (0.05,0) [0|0] "" Vector__XXX
 SG_ VCLEFT_a444_overTempWarning m444 : 38|1@1+ (1,0) [0|0] "" Vector__XXX
 SG_ VCLEFT_a480_hwlo m480 : 38|1@1+ (1,0) [0|0] "" Vector__XXX
 SG_ VCLEFT_a016_NVMMWriteFailed m16 : 37|1@1+ (1,0) [0|0] "" Vector__XXX
 SG_ VCLEFT_a104_VEH_status m104 : 37|1@1+ (1,0) [0|0] "" Vector__XXX
 SG_ VCLEFT_a113_CH_powertrainControl m113 : 37|1@1+ (1,0) [0|0] "" Vector__XXX
 SG_ VCLEFT_a116_BDY_switchStatus m116 : 37|1@1+ (1,0) [0|0] "" Vector__XXX
 SG_ VCLEFT_a117_VEH_status m117 : 37|1@1+ (1,0) [0|0] "" Vector__XXX
 SG_ VCLEFT_a118_CH_12VBatteryStatus m118 : 37|1@1+ (1,0) [0|0] "" Vector__XXX
 SG_ VCLEFT_a120_VEH_estimatedBrakeTe m120 : 37|1@1+ (1,0) [0|0] "" Vector__XXX
 SG_ VCLEFT_a129_VGS_HA m129 : 37|1@1+ (1,0) [0|0] "" Vector__XXX
 SG_ VCLEFT_a192_phaseShorted m192 : 37|1@1+ (1,0) [0|0] "" Vector__XXX
 SG_ VCLEFT_a444_overTempShutdown m444 : 37|1@1+ (1,0) [0|0] "" Vector__XXX
 SG_ VCLEFT_a480_hitAlertRateLimit m480 : 37|1@1+ (1,0) [0|0] "" Vector__XXX
 SG_ VCLEFT_a005_faults1 m5 : 36|12@1+ (1,0) [0|0] "" Vector__XXX
 SG_ VCLEFT_a016_NVMMMemOverflow m16 : 36|1@1+ (1,0) [0|0] "" Vector__XXX
 SG_ VCLEFT_a104_VEH_summonCommand m104 : 36|1@1+ (1,0) [0|0] "" Vector__XXX
 SG_ VCLEFT_a113_CH_chassisControl m113 : 36|1@1+ (1,0) [0|0] "" Vector__XXX
 SG_ VCLEFT_a116_BDY_restraintStatus m116 : 36|1@1+ (1,0) [0|0] "" Vector__XXX
 SG_ VCLEFT_a117_PARTY_doorStatus m117 : 36|1@1+ (1,0) [0|0] "" Vector__XXX
 SG_ VCLEFT_a118_PARTY_vehNm m118 : 36|1@1+ (1,0) [0|0] "" Vector__XXX
 SG_ VCLEFT_a120_CH_speed m120 : 36|1@1+ (1,0) [0|0] "" Vector__XXX
 SG_ VCLEFT_a129_VCPH_OVLO_ABS m129 : 36|1@1+ (1,0) [0|0] "" Vector__XXX
 SG_ VCLEFT_a173_btnTimeMsAutoDownLF m173 : 36|4@1+ (50,0) [0|0] "" Vector__XXX
 SG_ VCLEFT_a192_linFramingError m192 : 36|1@1+ (1,0) [0|0] "" Vector__XXX
 SG_ VCLEFT_a356_testStatus m356 : 36|4@1+ (1,0) [0|0] "" Vector__XXX
 SG_ VCLEFT_a362_angleVar m362 : 36|20@1+ (1e-06,0) [0|0] "" Vector__XXX
 SG_ VCLEFT_a444_cpUndervoltage m444 : 36|1@1+ (1,0) [0|0] "" Vector__XXX
 SG_ VCLEFT_a480_bufferFull m480 : 36|1@1+ (1,0) [0|0] "" Vector__XXX
 SG_ VCLEFT_a481_stuckOnVDS m481 : 36|10@1+ (1,0) [0|0] "" Vector__XXX
 SG_ VCLEFT_a016_NVMMRecordUpgraded m16 : 35|1@1+ (1,0) [0|0] "" Vector__XXX
 SG_ VCLEFT_a104_VEH_matrixHighBeamRe m104 : 35|1@1+ (1,0) [0|0] "" Vector__XXX
 SG_ VCLEFT_a113_VEH_LVControl m113 : 35|1@1+ (1,0) [0|0] "" Vector__XXX
 SG_ VCLEFT_a114_CH_status m114 : 35|1@1+ (1,0) [0|0] "" Vector__XXX
 SG_ VCLEFT_a116_BDY_epbmStatus m116 : 35|1@1+ (1,0) [0|0] "" Vector__XXX
 SG_ VCLEFT_a117_VEH_thermalStatus m117 : 35|1@1+ (1,0) [0|0] "" Vector__XXX
 SG_ VCLEFT_a118_VEH_lightStatus m118 : 35|1@1+ (1,0) [0|0] "" Vector__XXX
 SG_ VCLEFT_a120_PARTY_stalklessInter m120 : 35|1@1+ (1,0) [0|0] "" Vector__XXX
 SG_ VCLEFT_a129_VCPH_UVLO m129 : 35|1@1+ (1,0) [0|0] "" Vector__XXX
 SG_ VCLEFT_a150_lookbackIndex m150 : 35|6@1+ (1,0) [0|0] "" Vector__XXX
 SG_ VCLEFT_a151_lookbackIndex m151 : 35|6@1+ (1,0) [0|0] "" Vector__XXX
 SG_ VCLEFT_a192_linChecksumError m192 : 35|1@1+ (1,0) [0|0] "" Vector__XXX
 SG_ VCLEFT_a444_supplyUndervoltage m444 : 35|1@1+ (1,0) [0|0] "" Vector__XXX
 SG_ VCLEFT_a480_configIncorrect m480 : 35|1@1+ (1,0) [0|0] "" Vector__XXX
 SG_ VCLEFT_a481_VDSFailure m481 : 35|1@1+ (1,0) [0|0] "" Vector__XXX
 SG_ VCLEFT_a551_restrictDoorReleaseS m551 : 35|1@1+ (1,0) [0|0] "" Vector__XXX
 SG_ VCLEFT_a016_NVMMVersionMismatch m16 : 34|1@1+ (1,0) [0|0] "" Vector__XXX
 SG_ VCLEFT_a104_PARTY_matrixBendAngl m104 : 34|1@1+ (1,0) [0|0] "" Vector__XXX
 SG_ VCLEFT_a113_VEH_elevationStatus m113 : 34|1@1+ (1,0) [0|0] "" Vector__XXX
 SG_ VCLEFT_a114_CH_party3 m114 : 34|1@1+ (1,0) [0|0] "" Vector__XXX
 SG_ VCLEFT_a116_PARTY_doorStatus m116 : 34|1@1+ (1,0) [0|0] "" Vector__XXX
 SG_ VCLEFT_a117_PARTY_restraintStatu m117 : 34|1@1+ (1,0) [0|0] "" Vector__XXX
 SG_ VCLEFT_a118_CH_lighting m118 : 34|1@1+ (1,0) [0|0] "" Vector__XXX
 SG_ VCLEFT_a120_PT_systemPower m120 : 34|1@1+ (1,0) [0|0] "" Vector__XXX
 SG_ VCLEFT_a129_VCPH_UVLO2 m129 : 34|1@1+ (1,0) [0|0] "" Vector__XXX
 SG_ VCLEFT_a224_seatSwitchForward m224 : 34|2@1+ (1,0) [0|0] "" Vector__XXX
 SG_ VCLEFT_a225_seatSwitchForward m225 : 34|2@1+ (1,0) [0|0] "" Vector__XXX
 SG_ VCLEFT_a226_seatSwitchForward m226 : 34|2@1+ (1,0) [0|0] "" Vector__XXX
 SG_ VCLEFT_a227_seatSwitchForward m227 : 34|2@1+ (1,0) [0|0] "" Vector__XXX
 SG_ VCLEFT_a302_DRVFault m302 : 34|1@1+ (1,0) [0|0] "" Vector__XXX
 SG_ VCLEFT_a360_angleVar m360 : 34|10@1+ (1e-05,0) [0|0] "" Vector__XXX
 SG_ VCLEFT_a382_gpsAccuracyEnd m382 : 34|5@1+ (0.2,0) [0|0] "" Vector__XXX
 SG_ VCLEFT_a444_overcurrent m444 : 34|1@1+ (1,0) [0|0] "" Vector__XXX
 SG_ VCLEFT_a480_spiNotDone m480 : 34|1@1+ (1,0) [0|0] "" Vector__XXX
 SG_ VCLEFT_a481_VDSFinished m481 : 34|1@1+ (1,0) [0|0] "" Vector__XXX
 SG_ VCLEFT_a016_NVMMCRCMismatch m16 : 33|1@1+ (1,0) [0|0] "" Vector__XXX
 SG_ VCLEFT_a104_PARTY_integratedSafe m104 : 33|1@1+ (1,0) [0|0] "" Vector__XXX
 SG_ VCLEFT_a113_VEH_status m113 : 33|1@1+ (1,0) [0|0] "" Vector__XXX
 SG_ VCLEFT_a114_CH_party1 m114 : 33|1@1+ (1,0) [0|0] "" Vector__XXX
 SG_ VCLEFT_a116_PARTY_restraintStatu m116 : 33|1@1+ (1,0) [0|0] "" Vector__XXX
 SG_ VCLEFT_a117_VEH_seatStatus2 m117 : 33|1@1+ (1,0) [0|0] "" Vector__XXX
 SG_ VCLEFT_a118_VEH_interNodeResista m118 : 33|1@1+ (1,0) [0|0] "" Vector__XXX
 SG_ VCLEFT_a120_VEH_autonomyHealth m120 : 33|1@1+ (1,0) [0|0] "" Vector__XXX
 SG_ VCLEFT_a129_VCP_LSD_UVLO2 m129 : 33|1@1+ (1,0) [0|0] "" Vector__XXX
 SG_ VCLEFT_a302_CBC_UARTReset m302 : 33|1@1+ (1,0) [0|0] "" Vector__XXX
 SG_ VCLEFT_a444_gateDriver m444 : 33|1@1+ (1,0) [0|0] "" Vector__XXX
 SG_ VCLEFT_a480_watchdog m480 : 33|1@1+ (1,0) [0|0] "" Vector__XXX
 SG_ VCLEFT_a000_alertDataW1 m0 : 32|16@1+ (1,0) [0|0] "" Vector__XXX
 SG_ VCLEFT_a003_LineNumber m3 : 32|16@1+ (1,0) [0|0] "" Vector__XXX
 SG_ VCLEFT_a005_busID1 m5 : 32|4@1+ (1,0) [0|0] "" Vector__XXX
 SG_ VCLEFT_a006_messageID m6 : 32|29@1+ (1,0) [0|0] "" Vector__XXX
 SG_ VCLEFT_a016_NVMMRecordNotFound m16 : 32|1@1+ (1,0) [0|0] "" Vector__XXX
 SG_ VCLEFT_a022_TaskInitError1 m22 : 32|8@1+ (1,0) [0|0] "" Vector__XXX
 SG_ VCLEFT_a031_uds_bytes_2 m31 : 32|8@1+ (1,0) [0|0] "" Vector__XXX
 SG_ VCLEFT_a041_CPULoad10msTask m41 : 32|8@1+ (1,0) [0|0] "" Vector__XXX
 SG_ VCLEFT_a042_Usage100msTask m42 : 32|8@1+ (1,0) [0|0] "" Vector__XXX
 SG_ VCLEFT_a063_ADCVoltage m63 : 32|8@1+ (0.025,0) [0|0] "" Vector__XXX
 SG_ VCLEFT_a104_VEH_steeringControl m104 : 32|1@1+ (1,0) [0|0] "" Vector__XXX
 SG_ VCLEFT_a110_PARTY_carConfig m110 : 32|1@1+ (1,0) [0|0] "" Vector__XXX
 SG_ VCLEFT_a113_VEH_debugECU m113 : 32|1@1+ (1,0) [0|0] "" Vector__XXX
 SG_ VCLEFT_a114_BDY_wheelSpeeds m114 : 32|1@1+ (1,0) [0|0] "" Vector__XXX
 SG_ VCLEFT_a116_VEH_windowStatus m116 : 32|1@1+ (1,0) [0|0] "" Vector__XXX
 SG_ VCLEFT_a117_VEH_liftgateStatus m117 : 32|1@1+ (1,0) [0|0] "" Vector__XXX
 SG_ VCLEFT_a118_CH_sensors m118 : 32|1@1+ (1,0) [0|0] "" Vector__XXX
 SG_ VCLEFT_a120_PARTY_autonomyHealth m120 : 32|1@1+ (1,0) [0|0] "" Vector__XXX
 SG_ VCLEFT_a129_AVDD_UVLO m129 : 32|1@1+ (1,0) [0|0] "" Vector__XXX
 SG_ VCLEFT_a150_windowPinchReason m150 : 32|3@1+ (1,0) [0|0] "" Vector__XXX
 SG_ VCLEFT_a151_windowPinchReason m151 : 32|3@1+ (1,0) [0|0] "" Vector__XXX
 SG_ VCLEFT_a164_upMovementTimeMs m164 : 32|7@1+ (50,0) [0|0] "" Vector__XXX
 SG_ VCLEFT_a165_sealZoneStartPos m165 : 32|8@1+ (1,0) [0|0] "" Vector__XXX
 SG_ VCLEFT_a166_powerSealPos m166 : 32|11@1+ (1,0) [0|0] "" Vector__XXX
 SG_ VCLEFT_a167_pinchVoltage m167 : 32|6@1+ (0.25,0) [0|0] "" Vector__XXX
 SG_ VCLEFT_a168_pinchVoltage m168 : 32|6@1+ (0.25,0) [0|0] "" Vector__XXX
 SG_ VCLEFT_a173_btnTimeMsDownLF m173 : 32|4@1+ (50,0) [0|0] "" Vector__XXX
 SG_ VCLEFT_a175_lookbackIndex m175 : 32|6@1+ (1,0) [0|0] "" Vector__XXX
 SG_ VCLEFT_a176_lookbackIndex m176 : 32|6@1+ (1,0) [0|0] "" Vector__XXX
 SG_ VCLEFT_a180_extHandlePulled m180 : 32|1@1+ (1,0) [0|0] "" Vector__XXX
 SG_ VCLEFT_a181_extHandlePulled m181 : 32|1@1+ (1,0) [0|0] "" Vector__XXX
 SG_ VCLEFT_a192_selfTestResult m192 : 32|3@1+ (1,0) [0|0] "" Vector__XXX
 SG_ VCLEFT_a202_desyncCount m202 : 32|6@1+ (1,0) [0|0] "" Vector__XXX
 SG_ VCLEFT_a203_desyncCount m203 : 32|6@1+ (1,0) [0|0] "" Vector__XXX
 SG_ VCLEFT_a204_desyncCount m204 : 32|6@1+ (1,0) [0|0] "" Vector__XXX
 SG_ VCLEFT_a205_desyncCount m205 : 32|6@1+ (1,0) [0|0] "" Vector__XXX
 SG_ VCLEFT_a206_unitStatusEPB m206 : 32|5@1+ (1,0) [0|0] "" Vector__XXX
 SG_ VCLEFT_a207_unitStatusEPB m207 : 32|5@1+ (1,0) [0|0] "" Vector__XXX
 SG_ VCLEFT_a208_unitStatusEPB m208 : 32|5@1+ (1,0) [0|0] "" Vector__XXX
 SG_ VCLEFT_a209_unitStatusEPB m209 : 32|5@1+ (1,0) [0|0] "" Vector__XXX
 SG_ VCLEFT_a210_unitStatusEPB m210 : 32|5@1+ (1,0) [0|0] "" Vector__XXX
 SG_ VCLEFT_a211_desyncCount m211 : 32|6@1+ (1,0) [0|0] "" Vector__XXX
 SG_ VCLEFT_a212_desyncCount m212 : 32|6@1+ (1,0) [0|0] "" Vector__XXX
 SG_ VCLEFT_a213_desyncCount m213 : 32|6@1+ (1,0) [0|0] "" Vector__XXX
 SG_ VCLEFT_a214_desyncCount m214 : 32|6@1+ (1,0) [0|0] "" Vector__XXX
 SG_ VCLEFT_a216_byte1 m216 : 32|8@1+ (1,0) [0|0] "" Vector__XXX
 SG_ VCLEFT_a217_byte6 m217 : 32|8@1+ (1,0) [0|0] "" Vector__XXX
 SG_ VCLEFT_a218_voltage m218 : 32|10@1+ (0.02,0) [0|0] "" Vector__XXX
 SG_ VCLEFT_a219_dropoutCount m219 : 32|12@1+ (1,0) [0|0] "" Vector__XXX
 SG_ VCLEFT_a224_seatSwitchBack m224 : 32|2@1+ (1,0) [0|0] "" Vector__XXX
 SG_ VCLEFT_a225_seatSwitchBack m225 : 32|2@1+ (1,0) [0|0] "" Vector__XXX
 SG_ VCLEFT_a226_seatSwitchBack m226 : 32|2@1+ (1,0) [0|0] "" Vector__XXX
 SG_ VCLEFT_a227_seatSwitchBack m227 : 32|2@1+ (1,0) [0|0] "" Vector__XXX
 SG_ VCLEFT_a228_seatMotorPosReal m228 : 32|12@1- (1,0) [0|0] "" Vector__XXX
 SG_ VCLEFT_a229_seatMotorPosReal m229 : 32|12@1- (1,0) [0|0] "" Vector__XXX
 SG_ VCLEFT_a230_seatMotorPosReal m230 : 32|12@1- (1,0) [0|0] "" Vector__XXX
 SG_ VCLEFT_a231_seatMotorPosReal m231 : 32|12@1- (1,0) [0|0] "" Vector__XXX
 SG_ VCLEFT_a236_lumbarBPressureHpa m236 : 32|16@1+ (1,0) [0|0] "" Vector__XXX
 SG_ VCLEFT_a237_lumbarBPressureHpa m237 : 32|16@1+ (1,0) [0|0] "" Vector__XXX
 SG_ VCLEFT_a238_lumbarBPressureHpa m238 : 32|16@1+ (1,0) [0|0] "" Vector__XXX
 SG_ VCLEFT_a259_temperature m259 : 32|8@1+ (0.5,-40) [0|0] "" Vector__XXX
 SG_ VCLEFT_a260_temperature m260 : 32|8@1+ (0.5,-40) [0|0] "" Vector__XXX
 SG_ VCLEFT_a276_mirrorTiltYPosition m276 : 32|8@1+ (0.02,0) [0|0] "" Vector__XXX
 SG_ VCLEFT_a286_encoderVoltage m286 : 32|6@1+ (0.15,0) [0|0] "" Vector__XXX
 SG_ VCLEFT_a287_encoderVoltage m287 : 32|6@1+ (0.15,0) [0|0] "" Vector__XXX
 SG_ VCLEFT_a290_railVoltage m290 : 32|12@1- (0.01,0) [0|0] "" Vector__XXX
 SG_ VCLEFT_a292_railV m292 : 32|12@1- (0.01,0) [0|0] "" Vector__XXX
 SG_ VCLEFT_a293_railV m293 : 32|12@1- (0.01,0) [0|0] "" Vector__XXX
 SG_ VCLEFT_a294_railV m294 : 32|12@1- (0.01,0) [0|0] "" Vector__XXX
 SG_ VCLEFT_a302_CBC_MIA m302 : 32|1@1+ (1,0) [0|0] "" Vector__XXX
 SG_ VCLEFT_a310_mirrorMaxFoldCurrent m310 : 32|7@1- (0.05,0) [0|0] "" Vector__XXX
 SG_ VCLEFT_a316_maxCurrentAmps m316 : 32|12@1+ (0.01,0) [0|0] "" Vector__XXX
 SG_ VCLEFT_a321_movementStartPositio m321 : 32|16@1- (1,0) [0|0] "" Vector__XXX
 SG_ VCLEFT_a322_movementStartPositio m322 : 32|16@1- (1,0) [0|0] "" Vector__XXX
 SG_ VCLEFT_a325_PWMfrequencyFL m325 : 32|16@1+ (0.025,0) [0|0] "" Vector__XXX
 SG_ VCLEFT_a326_PWMfrequencyRL m326 : 32|16@1+ (0.025,0) [0|0] "" Vector__XXX
 SG_ VCLEFT_a327_PWMfrequencyFL m327 : 32|16@1+ (0.025,0) [0|0] "" Vector__XXX
 SG_ VCLEFT_a328_PWMfrequencyRL m328 : 32|16@1+ (0.025,0) [0|0] "" Vector__XXX
 SG_ VCLEFT_a330_temperature m330 : 32|8@1+ (0.5,-40) [0|0] "" Vector__XXX
 SG_ VCLEFT_a331_temperature m331 : 32|8@1+ (0.5,-40) [0|0] "" Vector__XXX
 SG_ VCLEFT_a350_ensDuty m350 : 32|10@1+ (0.00098,0) [0|0] "" Vector__XXX
 SG_ VCLEFT_a351_liftgateStrutCurrent m351 : 32|8@1- (0.2,0) [0|0] "" Vector__XXX
 SG_ VCLEFT_a352_liftgateClosingCount m352 : 32|16@1+ (1,0) [0|0] "" Vector__XXX
 SG_ VCLEFT_a355_liftgateLatchStatus m355 : 32|4@1+ (1,0) [0|0] "" Vector__XXX
 SG_ VCLEFT_a357_liftgateLatchStatus m357 : 32|4@1+ (1,0) [0|0] "" Vector__XXX
 SG_ VCLEFT_a358_liftgateCurrent_0000 m358 : 32|7@1+ (1,0) [0|0] "" Vector__XXX
 SG_ VCLEFT_a381_pitchFromCycleDelta m381 : 32|7@1- (0.001,0) [0|0] "" Vector__XXX
 SG_ VCLEFT_a383_motorCurrent m383 : 32|12@1- (0.01,0) [0|0] "" Vector__XXX
 SG_ VCLEFT_a384_motorCurrent m384 : 32|12@1- (0.01,0) [0|0] "" Vector__XXX
 SG_ VCLEFT_a385_motorCurrent m385 : 32|12@1- (0.01,0) [0|0] "" Vector__XXX
 SG_ VCLEFT_a386_motorCurrent m386 : 32|12@1- (0.01,0) [0|0] "" Vector__XXX
 SG_ VCLEFT_a387_motorCurrent m387 : 32|12@1- (0.01,0) [0|0] "" Vector__XXX
 SG_ VCLEFT_a388_motorCurrent m388 : 32|12@1- (0.01,0) [0|0] "" Vector__XXX
 SG_ VCLEFT_a389_motorCurrent m389 : 32|12@1- (0.01,0) [0|0] "" Vector__XXX
 SG_ VCLEFT_a390_motorCurrent m390 : 32|12@1- (0.01,0) [0|0] "" Vector__XXX
 SG_ VCLEFT_a391_averagePower m391 : 32|7@1+ (10,-200) [0|0] "" Vector__XXX
 SG_ VCLEFT_a392_distanceTraveled m392 : 32|5@1+ (200,0) [0|0] "" Vector__XXX
 SG_ VCLEFT_a426_seatMotorPosReal m426 : 32|12@1- (1,0) [0|0] "" Vector__XXX
 SG_ VCLEFT_a427_seatMotorPosReal m427 : 32|12@1- (1,0) [0|0] "" Vector__XXX
 SG_ VCLEFT_a428_seatMotorPosReal m428 : 32|12@1- (1,0) [0|0] "" Vector__XXX
 SG_ VCLEFT_a429_seatMotorPosReal m429 : 32|12@1- (1,0) [0|0] "" Vector__XXX
 SG_ VCLEFT_a444_watchdog m444 : 32|1@1+ (1,0) [0|0] "" Vector__XXX
 SG_ VCLEFT_a445_expectedLSB m445 : 32|8@1+ (1,0) [0|0] "" Vector__XXX
 SG_ VCLEFT_a446_trailerAuxVoltage m446 : 32|16@1+ (0.01,0) [0|0] "" Vector__XXX
 SG_ VCLEFT_a447_motorType m447 : 32|2@1+ (1,0) [0|0] "" Vector__XXX
 SG_ VCLEFT_a448_motorType m448 : 32|2@1+ (1,0) [0|0] "" Vector__XXX
 SG_ VCLEFT_a478_ambientTemperature m478 : 32|8@1+ (0.5,-40) [0|0] "" Vector__XXX
 SG_ VCLEFT_a480_chargePumpLow m480 : 32|1@1+ (1,0) [0|0] "" Vector__XXX
 SG_ VCLEFT_a499_remoteEpbmStatus m499 : 32|5@1+ (1,0) [0|0] "" Vector__XXX
 SG_ VCLEFT_a523_control2Byte2 m523 : 32|8@1+ (1,0) [0|0] "" Vector__XXX
 SG_ VCLEFT_a546_mirrorMaxFoldVoltage m546 : 32|8@1+ (0.0784313725490196,0) [0|0] "" Vector__XXX
 SG_ VCLEFT_a550_pcbaTemperature m550 : 32|16@1- (0.125,55) [0|0] "" Vector__XXX
 SG_ VCLEFT_a551_lastRequestSourceFro m551 : 32|3@1+ (1,0) [0|0] "" Vector__XXX
 SG_ VCLEFT_a104_CH_steeringControl m104 : 31|1@1+ (1,0) [0|0] "" Vector__XXX
 SG_ VCLEFT_a109_CH_status m109 : 31|1@1+ (1,0) [0|0] "" Vector__XXX
 SG_ VCLEFT_a110_CH_epochTimeGtw m110 : 31|1@1+ (1,0) [0|0] "" Vector__XXX
 SG_ VCLEFT_a113_VEH_ventCntlReg m113 : 31|1@1+ (1,0) [0|0] "" Vector__XXX
 SG_ VCLEFT_a114_BDY_wheelRotation m114 : 31|1@1+ (1,0) [0|0] "" Vector__XXX
 SG_ VCLEFT_a116_VEH_thermalCommand m116 : 31|1@1+ (1,0) [0|0] "" Vector__XXX
 SG_ VCLEFT_a117_VEH_intrusionSensorS m117 : 31|1@1+ (1,0) [0|0] "" Vector__XXX
 SG_ VCLEFT_a118_PARTY_sensors m118 : 31|1@1+ (1,0) [0|0] "" Vector__XXX
 SG_ VCLEFT_a120_VEH_systemPower m120 : 31|1@1+ (1,0) [0|0] "" Vector__XXX
 SG_ VCLEFT_a129_VREG_UV m129 : 31|1@1+ (1,0) [0|0] "" Vector__XXX
 SG_ VCLEFT_a166_STATE_TIMEOUT m166 : 31|1@1+ (1,0) [0|0] "" Vector__XXX
 SG_ VCLEFT_a302_overCurrentLatch m302 : 31|1@1+ (1,0) [0|0] "" Vector__XXX
 SG_ VCLEFT_a361_angleVar m361 : 31|17@1+ (1e-05,0) [0|0] "" Vector__XXX
 SG_ VCLEFT_a363_liftgateCalibrated m363 : 31|1@1+ (1,0) [0|0] "" Vector__XXX
 SG_ VCLEFT_a480_vgsLow m480 : 31|1@1+ (1,0) [0|0] "" Vector__XXX
 SG_ VCLEFT_a104_PARTY_steeringContro m104 : 30|1@1+ (1,0) [0|0] "" Vector__XXX
 SG_ VCLEFT_a109_CH_inertial2 m109 : 30|1@1+ (1,0) [0|0] "" Vector__XXX
 SG_ VCLEFT_a110_CH_chNm m110 : 30|1@1+ (1,0) [0|0] "" Vector__XXX
 SG_ VCLEFT_a113_VEH_driverProfi_0000 m113 : 30|1@1+ (1,0) [0|0] "" Vector__XXX
 SG_ VCLEFT_a114_BDY_status m114 : 30|1@1+ (1,0) [0|0] "" Vector__XXX
 SG_ VCLEFT_a116_VEH_status m116 : 30|1@1+ (1,0) [0|0] "" Vector__XXX
 SG_ VCLEFT_a117_VEH_switchStatus m117 : 30|1@1+ (1,0) [0|0] "" Vector__XXX
 SG_ VCLEFT_a118_CH_LVPowerState m118 : 30|1@1+ (1,0) [0|0] "" Vector__XXX
 SG_ VCLEFT_a120_PARTY_aggregatedAxle m120 : 30|1@1+ (1,0) [0|0] "" Vector__XXX
 SG_ VCLEFT_a129_OTSD m129 : 30|1@1+ (1,0) [0|0] "" Vector__XXX
 SG_ VCLEFT_a136_ibstRodPositionQF m136 : 30|2@1+ (1,0) [0|0] "" Vector__XXX
 SG_ VCLEFT_a145_ibstRodPositionQF m145 : 30|2@1+ (1,0) [0|0] "" Vector__XXX
 SG_ VCLEFT_a166_PINCH_DEBUG m166 : 30|1@1+ (1,0) [0|0] "" Vector__XXX
 SG_ VCLEFT_a302_DRV_MIA m302 : 30|1@1+ (1,0) [0|0] "" Vector__XXX
 SG_ VCLEFT_a480_ntcOvertemperature m480 : 30|1@1+ (1,0) [0|0] "" Vector__XXX
 SG_ VCLEFT_a098_VEH_motorStatus m98 : 29|1@1+ (1,0) [0|0] "" Vector__XXX
 SG_ VCLEFT_a104_PARTY_status m104 : 29|1@1+ (1,0) [0|0] "" Vector__XXX
 SG_ VCLEFT_a107_VEH_chargeInfo m107 : 29|1@1+ (1,0) [0|0] "" Vector__XXX
 SG_ VCLEFT_a108_CH_torque m108 : 29|1@1+ (1,0) [0|0] "" Vector__XXX
 SG_ VCLEFT_a109_CH_inertial1 m109 : 29|1@1+ (1,0) [0|0] "" Vector__XXX
 SG_ VCLEFT_a110_CH_vin m110 : 29|1@1+ (1,0) [0|0] "" Vector__XXX
 SG_ VCLEFT_a113_VEH_driverProfileRec m113 : 29|1@1+ (1,0) [0|0] "" Vector__XXX
 SG_ VCLEFT_a114_BDY_party3 m114 : 29|1@1+ (1,0) [0|0] "" Vector__XXX
 SG_ VCLEFT_a116_VEH_seatStatus2 m116 : 29|1@1+ (1,0) [0|0] "" Vector__XXX
 SG_ VCLEFT_a117_VEH_windowStatus m117 : 29|1@1+ (1,0) [0|0] "" Vector__XXX
 SG_ VCLEFT_a118_VEH_thermalCommand m118 : 29|1@1+ (1,0) [0|0] "" Vector__XXX
 SG_ VCLEFT_a120_VEH_aggregatedAxleSp m120 : 29|1@1+ (1,0) [0|0] "" Vector__XXX
 SG_ VCLEFT_a129_WD_FAULT m129 : 29|1@1+ (1,0) [0|0] "" Vector__XXX
 SG_ VCLEFT_a130_OTW m130 : 29|1@1+ (1,0) [0|0] "" Vector__XXX
 SG_ VCLEFT_a166_PINCH_V1 m166 : 29|1@1+ (1,0) [0|0] "" Vector__XXX
 SG_ VCLEFT_a192_selfTestFailed m192 : 29|1@1+ (1,0) [0|0] "" Vector__XXX
 SG_ VCLEFT_a224_seatMotorState m224 : 29|3@1+ (1,0) [0|0] "" Vector__XXX
 SG_ VCLEFT_a225_seatMotorState m225 : 29|3@1+ (1,0) [0|0] "" Vector__XXX
 SG_ VCLEFT_a226_seatMotorState m226 : 29|3@1+ (1,0) [0|0] "" Vector__XXX
 SG_ VCLEFT_a227_seatMotorState m227 : 29|3@1+ (1,0) [0|0] "" Vector__XXX
 SG_ VCLEFT_a302_motorDisconnect m302 : 29|1@1+ (1,0) [0|0] "" Vector__XXX
 SG_ VCLEFT_a382_gpsAccuracyStart m382 : 29|5@1+ (0.2,0) [0|0] "" Vector__XXX
 SG_ VCLEFT_a480_deviceOvertemperatur m480 : 29|1@1+ (1,0) [0|0] "" Vector__XXX
 SG_ VCLEFT_a525_frunkOpen m525 : 29|1@1+ (1,0) [0|0] "" Vector__XXX
 SG_ VCLEFT_a599_frunkOpen m599 : 29|1@1+ (1,0) [0|0] "" Vector__XXX
 SG_ VCLEFT_a058_current m58 : 28|11@1+ (0.1,0) [0|0] "" Vector__XXX
 SG_ VCLEFT_a059_resistanceEstimate m59 : 28|12@1+ (0.00244,0) [0|0] "" Vector__XXX
 SG_ VCLEFT_a098_PARTY_motorStatus m98 : 28|1@1+ (1,0) [0|0] "" Vector__XXX
 SG_ VCLEFT_a104_CH_status m104 : 28|1@1+ (1,0) [0|0] "" Vector__XXX
 SG_ VCLEFT_a107_VEH_energyStatus m107 : 28|1@1+ (1,0) [0|0] "" Vector__XXX
 SG_ VCLEFT_a108_VEH_motorStatus m108 : 28|1@1+ (1,0) [0|0] "" Vector__XXX
 SG_ VCLEFT_a109_VEH_inertial2 m109 : 28|1@1+ (1,0) [0|0] "" Vector__XXX
 SG_ VCLEFT_a110_CH_carState m110 : 28|1@1+ (1,0) [0|0] "" Vector__XXX
 SG_ VCLEFT_a113_VEH_vehicleModes m113 : 28|1@1+ (1,0) [0|0] "" Vector__XXX
 SG_ VCLEFT_a114_BDY_offsets m114 : 28|1@1+ (1,0) [0|0] "" Vector__XXX
 SG_ VCLEFT_a115_CH_TPMSDisplay m115 : 28|1@1+ (1,0) [0|0] "" Vector__XXX
 SG_ VCLEFT_a116_VEH_logging1Hz m116 : 28|1@1+ (1,0) [0|0] "" Vector__XXX
 SG_ VCLEFT_a117_VEH_doorStatus2 m117 : 28|1@1+ (1,0) [0|0] "" Vector__XXX
 SG_ VCLEFT_a118_PARTY_vehicleTime m118 : 28|1@1+ (1,0) [0|0] "" Vector__XXX
 SG_ VCLEFT_a120_PARTY_vehicleEstimat m120 : 28|1@1+ (1,0) [0|0] "" Vector__XXX
 SG_ VCLEFT_a129_PVDD_UVLO2 m129 : 28|1@1+ (1,0) [0|0] "" Vector__XXX
 SG_ VCLEFT_a130_TEMP_FLAG3 m130 : 28|1@1+ (1,0) [0|0] "" Vector__XXX
 SG_ VCLEFT_a166_ENCODER_STALL m166 : 28|1@1+ (1,0) [0|0] "" Vector__XXX
 SG_ VCLEFT_a192_motorStalled m192 : 28|1@1+ (1,0) [0|0] "" Vector__XXX
 SG_ VCLEFT_a202_wenchPendingAllowed m202 : 28|1@1+ (1,0) [0|0] "" Vector__XXX
 SG_ VCLEFT_a203_wenchPendingAllowed m203 : 28|1@1+ (1,0) [0|0] "" Vector__XXX
 SG_ VCLEFT_a204_wenchPendingAllowed m204 : 28|1@1+ (1,0) [0|0] "" Vector__XXX
 SG_ VCLEFT_a205_wenchPendingAllowed m205 : 28|1@1+ (1,0) [0|0] "" Vector__XXX
 SG_ VCLEFT_a206_wenchPendingAllowed m206 : 28|1@1+ (1,0) [0|0] "" Vector__XXX
 SG_ VCLEFT_a207_wenchPendingAllowed m207 : 28|1@1+ (1,0) [0|0] "" Vector__XXX
 SG_ VCLEFT_a208_wenchPendingAllowed m208 : 28|1@1+ (1,0) [0|0] "" Vector__XXX
 SG_ VCLEFT_a209_wenchPendingAllowed m209 : 28|1@1+ (1,0) [0|0] "" Vector__XXX
 SG_ VCLEFT_a210_wenchPendingAllowed m210 : 28|1@1+ (1,0) [0|0] "" Vector__XXX
 SG_ VCLEFT_a211_wenchPendingAllowed m211 : 28|1@1+ (1,0) [0|0] "" Vector__XXX
 SG_ VCLEFT_a212_wenchPendingAllowed m212 : 28|1@1+ (1,0) [0|0] "" Vector__XXX
 SG_ VCLEFT_a213_wenchPendingAllowed m213 : 28|1@1+ (1,0) [0|0] "" Vector__XXX
 SG_ VCLEFT_a214_wenchPendingAllowed m214 : 28|1@1+ (1,0) [0|0] "" Vector__XXX
 SG_ VCLEFT_a232_seatMotorPosReal m232 : 28|12@1- (1,0) [0|0] "" Vector__XXX
 SG_ VCLEFT_a233_seatMotorPosReal m233 : 28|12@1- (1,0) [0|0] "" Vector__XXX
 SG_ VCLEFT_a234_seatMotorPosReal m234 : 28|12@1- (1,0) [0|0] "" Vector__XXX
 SG_ VCLEFT_a235_seatMotorPosReal m235 : 28|12@1- (1,0) [0|0] "" Vector__XXX
 SG_ VCLEFT_a239_seatHeatTmp m239 : 28|12@1- (0.05,0) [0|0] "" Vector__XXX
 SG_ VCLEFT_a240_seatHeatTmp m240 : 28|12@1- (0.05,0) [0|0] "" Vector__XXX
 SG_ VCLEFT_a241_seatHeatTmp m241 : 28|12@1- (0.05,0) [0|0] "" Vector__XXX
 SG_ VCLEFT_a242_seatHeatTmp m242 : 28|12@1- (0.05,0) [0|0] "" Vector__XXX
 SG_ VCLEFT_a243_seatHeatTmp m243 : 28|12@1- (0.05,0) [0|0] "" Vector__XXX
 SG_ VCLEFT_a244_seatHeatTmp m244 : 28|12@1- (0.05,0) [0|0] "" Vector__XXX
 SG_ VCLEFT_a245_seatHeatTmp m245 : 28|12@1- (0.05,0) [0|0] "" Vector__XXX
 SG_ VCLEFT_a246_seatHeatTmp m246 : 28|12@1- (0.05,0) [0|0] "" Vector__XXX
 SG_ VCLEFT_a247_seatHeatTmp m247 : 28|12@1- (0.05,0) [0|0] "" Vector__XXX
 SG_ VCLEFT_a248_seatHeatTmp m248 : 28|12@1- (0.05,0) [0|0] "" Vector__XXX
 SG_ VCLEFT_a249_seatHeatTmp m249 : 28|12@1- (0.05,0) [0|0] "" Vector__XXX
 SG_ VCLEFT_a250_seatHeatTmp m250 : 28|12@1- (0.05,0) [0|0] "" Vector__XXX
 SG_ VCLEFT_a251_seatMotorPosReal m251 : 28|12@1- (1,0) [0|0] "" Vector__XXX
 SG_ VCLEFT_a252_seatMotorPosReal m252 : 28|12@1- (1,0) [0|0] "" Vector__XXX
 SG_ VCLEFT_a253_seatMotorPosReal m253 : 28|12@1- (1,0) [0|0] "" Vector__XXX
 SG_ VCLEFT_a254_seatMotorPosReal m254 : 28|12@1- (1,0) [0|0] "" Vector__XXX
 SG_ VCLEFT_a263_seatMotorDCurrent m263 : 28|12@1- (0.01,0) [0|0] "" Vector__XXX
 SG_ VCLEFT_a264_seatMotorDCurrent m264 : 28|12@1- (0.01,0) [0|0] "" Vector__XXX
 SG_ VCLEFT_a265_seatMotorDCurrent m265 : 28|12@1- (0.01,0) [0|0] "" Vector__XXX
 SG_ VCLEFT_a266_seatMotorDCurrent m266 : 28|12@1- (0.01,0) [0|0] "" Vector__XXX
 SG_ VCLEFT_a267_seatMotorDCurrent m267 : 28|12@1- (0.01,0) [0|0] "" Vector__XXX
 SG_ VCLEFT_a268_seatMotorDCurrent m268 : 28|12@1- (0.01,0) [0|0] "" Vector__XXX
 SG_ VCLEFT_a269_seatMotorDCurrent m269 : 28|12@1- (0.01,0) [0|0] "" Vector__XXX
 SG_ VCLEFT_a270_seatMotorDCurrent m270 : 28|12@1- (0.01,0) [0|0] "" Vector__XXX
 SG_ VCLEFT_a291_railVoltage m291 : 28|12@1+ (0.01,0) [0|0] "" Vector__XXX
 SG_ VCLEFT_a295_railV m295 : 28|12@1- (0.01,0) [0|0] "" Vector__XXX
 SG_ VCLEFT_a296_railV m296 : 28|12@1- (0.01,0) [0|0] "" Vector__XXX
 SG_ VCLEFT_a302_fetOvertempShutdown m302 : 28|1@1+ (1,0) [0|0] "" Vector__XXX
 SG_ VCLEFT_a323_calibrationRight m323 : 28|12@1+ (0.002,0) [0|0] "" Vector__XXX
 SG_ VCLEFT_a374_trailerMode m374 : 28|1@1+ (1,0) [0|0] "" Vector__XXX
 SG_ VCLEFT_a376_2RowSeatTrackActuato m376 : 28|12@1- (0.1,0) [0|0] "" Vector__XXX
 SG_ VCLEFT_a480_fuseLatch m480 : 28|1@1+ (1,0) [0|0] "" Vector__XXX
 SG_ VCLEFT_a525_factoryGated m525 : 28|1@1+ (1,0) [0|0] "" Vector__XXX
 SG_ VCLEFT_a570_seatHeatTmp m570 : 28|12@1- (0.05,0) [0|0] "" Vector__XXX
 SG_ VCLEFT_a571_seatHeatTmp m571 : 28|12@1- (0.05,0) [0|0] "" Vector__XXX
 SG_ VCLEFT_a572_seatHeatTmp m572 : 28|12@1- (0.05,0) [0|0] "" Vector__XXX
 SG_ VCLEFT_a573_seatHeatTmp m573 : 28|12@1- (0.05,0) [0|0] "" Vector__XXX
 SG_ VCLEFT_a599_factoryGated m599 : 28|1@1+ (1,0) [0|0] "" Vector__XXX
 SG_ VCLEFT_a021_Task1000msMissed m21 : 27|1@1+ (1,0) [0|0] "" Vector__XXX
 SG_ VCLEFT_a098_PT_temperature m98 : 27|1@1+ (1,0) [0|0] "" Vector__XXX
 SG_ VCLEFT_a104_PARTY_gpsAccuracies m104 : 27|1@1+ (1,0) [0|0] "" Vector__XXX
 SG_ VCLEFT_a107_VEH_packConfig m107 : 27|1@1+ (1,0) [0|0] "" Vector__XXX
 SG_ VCLEFT_a108_PARTY_motorStatus m108 : 27|1@1+ (1,0) [0|0] "" Vector__XXX
 SG_ VCLEFT_a109_VEH_inertial1 m109 : 27|1@1+ (1,0) [0|0] "" Vector__XXX
 SG_ VCLEFT_a110_CH_carConfig m110 : 27|1@1+ (1,0) [0|0] "" Vector__XXX
 SG_ VCLEFT_a111_CH_status m111 : 27|1@1+ (1,0) [0|0] "" Vector__XXX
 SG_ VCLEFT_a113_VEH_powertrainContro m113 : 27|1@1+ (1,0) [0|0] "" Vector__XXX
 SG_ VCLEFT_a114_PARTY_offsets m114 : 27|1@1+ (1,0) [0|0] "" Vector__XXX
 SG_ VCLEFT_a115_UI_corianderVehicleC m115 : 27|1@1+ (1,0) [0|0] "" Vector__XXX
 SG_ VCLEFT_a116_VEH_switchStatus m116 : 27|1@1+ (1,0) [0|0] "" Vector__XXX
 SG_ VCLEFT_a117_VEH_doorStatus m117 : 27|1@1+ (1,0) [0|0] "" Vector__XXX
 SG_ VCLEFT_a118_PARTY_outputPowerSta m118 : 27|1@1+ (1,0) [0|0] "" Vector__XXX
 SG_ VCLEFT_a120_PT_systemStatus m120 : 27|1@1+ (1,0) [0|0] "" Vector__XXX
 SG_ VCLEFT_a129_SNS_A_OCP m129 : 27|1@1+ (1,0) [0|0] "" Vector__XXX
 SG_ VCLEFT_a130_TEMP_FLAG2 m130 : 27|1@1+ (1,0) [0|0] "" Vector__XXX
 SG_ VCLEFT_a166_UNDERCURRENT m166 : 27|1@1+ (1,0) [0|0] "" Vector__XXX
 SG_ VCLEFT_a192_dcOvercurrent m192 : 27|1@1+ (1,0) [0|0] "" Vector__XXX
 SG_ VCLEFT_a202_parkPendingAllowed m202 : 27|1@1+ (1,0) [0|0] "" Vector__XXX
 SG_ VCLEFT_a203_parkPendingAllowed m203 : 27|1@1+ (1,0) [0|0] "" Vector__XXX
 SG_ VCLEFT_a204_parkPendingAllowed m204 : 27|1@1+ (1,0) [0|0] "" Vector__XXX
 SG_ VCLEFT_a205_parkPendingAllowed m205 : 27|1@1+ (1,0) [0|0] "" Vector__XXX
 SG_ VCLEFT_a206_parkPendingAllowed m206 : 27|1@1+ (1,0) [0|0] "" Vector__XXX
 SG_ VCLEFT_a207_parkPendingAllowed m207 : 27|1@1+ (1,0) [0|0] "" Vector__XXX
 SG_ VCLEFT_a208_parkPendingAllowed m208 : 27|1@1+ (1,0) [0|0] "" Vector__XXX
 SG_ VCLEFT_a209_parkPendingAllowed m209 : 27|1@1+ (1,0) [0|0] "" Vector__XXX
 SG_ VCLEFT_a210_parkPendingAllowed m210 : 27|1@1+ (1,0) [0|0] "" Vector__XXX
 SG_ VCLEFT_a211_parkPendingAllowed m211 : 27|1@1+ (1,0) [0|0] "" Vector__XXX
 SG_ VCLEFT_a212_parkPendingAllowed m212 : 27|1@1+ (1,0) [0|0] "" Vector__XXX
 SG_ VCLEFT_a213_parkPendingAllowed m213 : 27|1@1+ (1,0) [0|0] "" Vector__XXX
 SG_ VCLEFT_a214_parkPendingAllowed m214 : 27|1@1+ (1,0) [0|0] "" Vector__XXX
 SG_ VCLEFT_a302_TMS320OverTempShutDw m302 : 27|1@1+ (1,0) [0|0] "" Vector__XXX
 SG_ VCLEFT_a454_rxErrorFR m454 : 27|4@1+ (1,0) [0|0] "" Vector__XXX
 SG_ VCLEFT_a480_bypassSaturation m480 : 27|1@1+ (1,0) [0|0] "" Vector__XXX
 SG_ VCLEFT_a482_underloadDetected m482 : 27|1@1+ (1,0) [0|0] "" Vector__XXX
 SG_ VCLEFT_a525_serviceMode m525 : 27|1@1+ (1,0) [0|0] "" Vector__XXX
 SG_ VCLEFT_a599_serviceMode m599 : 27|1@1+ (1,0) [0|0] "" Vector__XXX
 SG_ VCLEFT_a021_Task1000msStarved m21 : 26|1@1+ (1,0) [0|0] "" Vector__XXX
 SG_ VCLEFT_a098_PT_thermalControl m98 : 26|1@1+ (1,0) [0|0] "" Vector__XXX
 SG_ VCLEFT_a104_PARTY_bodyControls m104 : 26|1@1+ (1,0) [0|0] "" Vector__XXX
 SG_ VCLEFT_a107_VEH_socStatus m107 : 26|1@1+ (1,0) [0|0] "" Vector__XXX
 SG_ VCLEFT_a108_PT_thermalControl m108 : 26|1@1+ (1,0) [0|0] "" Vector__XXX
 SG_ VCLEFT_a109_BDY_status m109 : 26|1@1+ (1,0) [0|0] "" Vector__XXX
 SG_ VCLEFT_a110_CH_airbagCutoffStatu m110 : 26|1@1+ (1,0) [0|0] "" Vector__XXX
 SG_ VCLEFT_a111_PARTY_status m111 : 26|1@1+ (1,0) [0|0] "" Vector__XXX
 SG_ VCLEFT_a112_CH_status m112 : 26|1@1+ (1,0) [0|0] "" Vector__XXX
 SG_ VCLEFT_a113_VEH_trackModeSetting m113 : 26|1@1+ (1,0) [0|0] "" Vector__XXX
 SG_ VCLEFT_a114_PARTY_brakeTorque m114 : 26|1@1+ (1,0) [0|0] "" Vector__XXX
 SG_ VCLEFT_a115_REM_authentication m115 : 26|1@1+ (1,0) [0|0] "" Vector__XXX
 SG_ VCLEFT_a116_VEH_restraintStatus m116 : 26|1@1+ (1,0) [0|0] "" Vector__XXX
 SG_ VCLEFT_a117_BDY_falconSwitchStat m117 : 26|1@1+ (1,0) [0|0] "" Vector__XXX
 SG_ VCLEFT_a118_PARTY_LVPowerState m118 : 26|1@1+ (1,0) [0|0] "" Vector__XXX
 SG_ VCLEFT_a120_PT_speed m120 : 26|1@1+ (1,0) [0|0] "" Vector__XXX
 SG_ VCLEFT_a129_SNS_B_OCP m129 : 26|1@1+ (1,0) [0|0] "" Vector__XXX
 SG_ VCLEFT_a130_TEMP_FLAG1 m130 : 26|1@1+ (1,0) [0|0] "" Vector__XXX
 SG_ VCLEFT_a132_RPMTarget m132 : 26|10@1+ (10,0) [0|0] "" Vector__XXX
 SG_ VCLEFT_a133_RPMTarget m133 : 26|10@1+ (10,0) [0|0] "" Vector__XXX
 SG_ VCLEFT_a166_POWER_AT_SEAL m166 : 26|1@1+ (1,0) [0|0] "" Vector__XXX
 SG_ VCLEFT_a192_motorOvertemp m192 : 26|1@1+ (1,0) [0|0] "" Vector__XXX
 SG_ VCLEFT_a202_releaseAllowed m202 : 26|1@1+ (1,0) [0|0] "" Vector__XXX
 SG_ VCLEFT_a203_releaseAllowed m203 : 26|1@1+ (1,0) [0|0] "" Vector__XXX
 SG_ VCLEFT_a204_releaseAllowed m204 : 26|1@1+ (1,0) [0|0] "" Vector__XXX
 SG_ VCLEFT_a205_releaseAllowed m205 : 26|1@1+ (1,0) [0|0] "" Vector__XXX
 SG_ VCLEFT_a206_releaseAllowed m206 : 26|1@1+ (1,0) [0|0] "" Vector__XXX
 SG_ VCLEFT_a207_releaseAllowed m207 : 26|1@1+ (1,0) [0|0] "" Vector__XXX
 SG_ VCLEFT_a208_releaseAllowed m208 : 26|1@1+ (1,0) [0|0] "" Vector__XXX
 SG_ VCLEFT_a209_releaseAllowed m209 : 26|1@1+ (1,0) [0|0] "" Vector__XXX
 SG_ VCLEFT_a210_releaseAllowed m210 : 26|1@1+ (1,0) [0|0] "" Vector__XXX
 SG_ VCLEFT_a211_releaseAllowed m211 : 26|1@1+ (1,0) [0|0] "" Vector__XXX
 SG_ VCLEFT_a212_releaseAllowed m212 : 26|1@1+ (1,0) [0|0] "" Vector__XXX
 SG_ VCLEFT_a213_releaseAllowed m213 : 26|1@1+ (1,0) [0|0] "" Vector__XXX
 SG_ VCLEFT_a214_releaseAllowed m214 : 26|1@1+ (1,0) [0|0] "" Vector__XXX
 SG_ VCLEFT_a284_RPMTarget m284 : 26|10@1+ (10,0) [0|0] "" Vector__XXX
 SG_ VCLEFT_a302_startupFailed m302 : 26|1@1+ (1,0) [0|0] "" Vector__XXX
 SG_ VCLEFT_a356_liftgatePositio_0000 m356 : 26|10@1- (0.1,42.5) [0|0] "" Vector__XXX
 SG_ VCLEFT_a374_reverse m374 : 26|2@1+ (1,0) [0|0] "" Vector__XXX
 SG_ VCLEFT_a393_timeElapsed m393 : 26|9@1+ (1,0) [0|0] "" Vector__XXX
 SG_ VCLEFT_a480_vdsMax m480 : 26|1@1+ (1,0) [0|0] "" Vector__XXX
 SG_ VCLEFT_a481_VDSDiff m481 : 26|8@1+ (1,0) [0|0] "" Vector__XXX
 SG_ VCLEFT_a482_underOrOverVoltageOr m482 : 26|1@1+ (1,0) [0|0] "" Vector__XXX
 SG_ VCLEFT_a021_Task1000msLate m21 : 25|1@1+ (1,0) [0|0] "" Vector__XXX
 SG_ VCLEFT_a089_VEH_party3 m89 : 25|1@1+ (1,0) [0|0] "" Vector__XXX
 SG_ VCLEFT_a098_PARTY_torque m98 : 25|1@1+ (1,0) [0|0] "" Vector__XXX
 SG_ VCLEFT_a104_PARTY_control m104 : 25|1@1+ (1,0) [0|0] "" Vector__XXX
 SG_ VCLEFT_a107_PT_socStatus m107 : 25|1@1+ (1,0) [0|0] "" Vector__XXX
 SG_ VCLEFT_a108_PT_temperature m108 : 25|1@1+ (1,0) [0|0] "" Vector__XXX
 SG_ VCLEFT_a109_BDY_inertial2 m109 : 25|1@1+ (1,0) [0|0] "" Vector__XXX
 SG_ VCLEFT_a110_VEH_canLogAvailabili m110 : 25|1@1+ (1,0) [0|0] "" Vector__XXX
 SG_ VCLEFT_a111_VEH_seatStatus m111 : 25|1@1+ (1,0) [0|0] "" Vector__XXX
 SG_ VCLEFT_a112_PARTY_status m112 : 25|1@1+ (1,0) [0|0] "" Vector__XXX
 SG_ VCLEFT_a113_VEH_chassisControl m113 : 25|1@1+ (1,0) [0|0] "" Vector__XXX
 SG_ VCLEFT_a114_VEH_wheelRotation m114 : 25|1@1+ (1,0) [0|0] "" Vector__XXX
 SG_ VCLEFT_a115_VEH_requests2 m115 : 25|1@1+ (1,0) [0|0] "" Vector__XXX
 SG_ VCLEFT_a116_VEH_seatHeatStatus m116 : 25|1@1+ (1,0) [0|0] "" Vector__XXX
 SG_ VCLEFT_a117_VEH_seatStatus m117 : 25|1@1+ (1,0) [0|0] "" Vector__XXX
 SG_ VCLEFT_a118_VEH_systemStatus m118 : 25|1@1+ (1,0) [0|0] "" Vector__XXX
 SG_ VCLEFT_a120_PARTY_status m120 : 25|1@1+ (1,0) [0|0] "" Vector__XXX
 SG_ VCLEFT_a129_SNS_C_OCP m129 : 25|1@1+ (1,0) [0|0] "" Vector__XXX
 SG_ VCLEFT_a130_VCPH_UVFL m130 : 25|1@1+ (1,0) [0|0] "" Vector__XXX
 SG_ VCLEFT_a150_movementTimeMs m150 : 25|7@1+ (50,0) [0|0] "" Vector__XXX
 SG_ VCLEFT_a151_movementTimeMs m151 : 25|7@1+ (50,0) [0|0] "" Vector__XXX
 SG_ VCLEFT_a166_JUST_CALIBRATED m166 : 25|1@1+ (1,0) [0|0] "" Vector__XXX
 SG_ VCLEFT_a173_doorOpenTimeMs m173 : 25|7@1+ (500,0) [0|0] "" Vector__XXX
 SG_ VCLEFT_a192_motorSoftOpenPhase m192 : 25|1@1+ (1,0) [0|0] "" Vector__XXX
 SG_ VCLEFT_a202_dynApplyAllowed m202 : 25|1@1+ (1,0) [0|0] "" Vector__XXX
 SG_ VCLEFT_a203_dynApplyAllowed m203 : 25|1@1+ (1,0) [0|0] "" Vector__XXX
 SG_ VCLEFT_a204_dynApplyAllowed m204 : 25|1@1+ (1,0) [0|0] "" Vector__XXX
 SG_ VCLEFT_a205_dynApplyAllowed m205 : 25|1@1+ (1,0) [0|0] "" Vector__XXX
 SG_ VCLEFT_a206_dynApplyAllowed m206 : 25|1@1+ (1,0) [0|0] "" Vector__XXX
 SG_ VCLEFT_a207_dynApplyAllowed m207 : 25|1@1+ (1,0) [0|0] "" Vector__XXX
 SG_ VCLEFT_a208_dynApplyAllowed m208 : 25|1@1+ (1,0) [0|0] "" Vector__XXX
 SG_ VCLEFT_a209_dynApplyAllowed m209 : 25|1@1+ (1,0) [0|0] "" Vector__XXX
 SG_ VCLEFT_a210_dynApplyAllowed m210 : 25|1@1+ (1,0) [0|0] "" Vector__XXX
 SG_ VCLEFT_a211_dynApplyAllowed m211 : 25|1@1+ (1,0) [0|0] "" Vector__XXX
 SG_ VCLEFT_a212_dynApplyAllowed m212 : 25|1@1+ (1,0) [0|0] "" Vector__XXX
 SG_ VCLEFT_a213_dynApplyAllowed m213 : 25|1@1+ (1,0) [0|0] "" Vector__XXX
 SG_ VCLEFT_a214_dynApplyAllowed m214 : 25|1@1+ (1,0) [0|0] "" Vector__XXX
 SG_ VCLEFT_a286_voltage m286 : 25|7@1+ (0.15,0) [0|0] "" Vector__XXX
 SG_ VCLEFT_a287_voltage m287 : 25|7@1+ (0.15,0) [0|0] "" Vector__XXX
 SG_ VCLEFT_a302_overspeedFault m302 : 25|1@1+ (1,0) [0|0] "" Vector__XXX
 SG_ VCLEFT_a310_foldingDirection m310 : 25|1@1+ (1,0) [0|0] "" Vector__XXX
 SG_ VCLEFT_a480_hardShort m480 : 25|1@1+ (1,0) [0|0] "" Vector__XXX
 SG_ VCLEFT_a481_outputOn m481 : 25|1@1+ (1,0) [0|0] "" Vector__XXX
 SG_ VCLEFT_a482_thermalWarning m482 : 25|1@1+ (1,0) [0|0] "" Vector__XXX
 SG_ VCLEFT_a006_mailboxID m6 : 24|8@1+ (1,0) [0|0] "" Vector__XXX
 SG_ VCLEFT_a021_Task100msMissed m21 : 24|1@1+ (1,0) [0|0] "" Vector__XXX
 SG_ VCLEFT_a022_TaskInitError0 m22 : 24|8@1+ (1,0) [0|0] "" Vector__XXX
 SG_ VCLEFT_a031_uds_bytes_1 m31 : 24|8@1+ (1,0) [0|0] "" Vector__XXX
 SG_ VCLEFT_a041_CPULoad1msTask m41 : 24|8@1+ (1,0) [0|0] "" Vector__XXX
 SG_ VCLEFT_a042_Usage10msTask m42 : 24|8@1+ (1,0) [0|0] "" Vector__XXX
 SG_ VCLEFT_a063_switchType m63 : 24|8@1+ (1,0) [0|0] "" Vector__XXX
 SG_ VCLEFT_a086_VEH_vehNm m86 : 24|1@1+ (1,0) [0|0] "" Vector__XXX
 SG_ VCLEFT_a087_VEH_motorStatus m87 : 24|1@1+ (1,0) [0|0] "" Vector__XXX
 SG_ VCLEFT_a088_VEH_motorStatus m88 : 24|1@1+ (1,0) [0|0] "" Vector__XXX
 SG_ VCLEFT_a089_VEH_party1 m89 : 24|1@1+ (1,0) [0|0] "" Vector__XXX
 SG_ VCLEFT_a098_PARTY_thermalControl m98 : 24|1@1+ (1,0) [0|0] "" Vector__XXX
 SG_ VCLEFT_a104_CH_control m104 : 24|1@1+ (1,0) [0|0] "" Vector__XXX
 SG_ VCLEFT_a107_PT_thermalStatus m107 : 24|1@1+ (1,0) [0|0] "" Vector__XXX
 SG_ VCLEFT_a108_PARTY_thermalControl m108 : 24|1@1+ (1,0) [0|0] "" Vector__XXX
 SG_ VCLEFT_a109_BDY_inertial1 m109 : 24|1@1+ (1,0) [0|0] "" Vector__XXX
 SG_ VCLEFT_a110_VEH_gearControl m110 : 24|1@1+ (1,0) [0|0] "" Vector__XXX
 SG_ VCLEFT_a111_VEH_LVPowerState m111 : 24|1@1+ (1,0) [0|0] "" Vector__XXX
 SG_ VCLEFT_a112_VEH_LVPowerState m112 : 24|1@1+ (1,0) [0|0] "" Vector__XXX
 SG_ VCLEFT_a113_VEH_ventCntlReq m113 : 24|1@1+ (1,0) [0|0] "" Vector__XXX
 SG_ VCLEFT_a114_CH_wheelRotation m114 : 24|1@1+ (1,0) [0|0] "" Vector__XXX
 SG_ VCLEFT_a115_VEH_requests m115 : 24|1@1+ (1,0) [0|0] "" Vector__XXX
 SG_ VCLEFT_a116_VEH_doorStatus m116 : 24|1@1+ (1,0) [0|0] "" Vector__XXX
 SG_ VCLEFT_a117_VEH_lightStatus m117 : 24|1@1+ (1,0) [0|0] "" Vector__XXX
 SG_ VCLEFT_a118_VEH_12VBatteryStatus m118 : 24|1@1+ (1,0) [0|0] "" Vector__XXX
 SG_ VCLEFT_a120_VEH_speed m120 : 24|1@1+ (1,0) [0|0] "" Vector__XXX
 SG_ VCLEFT_a129_VDS_LC m129 : 24|1@1+ (1,0) [0|0] "" Vector__XXX
 SG_ VCLEFT_a130_VDS_STATUS m130 : 24|1@1+ (1,0) [0|0] "" Vector__XXX
 SG_ VCLEFT_a164_stopReason m164 : 24|3@1+ (1,0) [0|0] "" Vector__XXX
 SG_ VCLEFT_a165_maxClosingPower m165 : 24|8@1+ (1,0) [0|0] "" Vector__XXX
 SG_ VCLEFT_a166_CAL_CLEAR_PARTIAL m166 : 24|1@1+ (1,0) [0|0] "" Vector__XXX
 SG_ VCLEFT_a167_movementTimeMs m167 : 24|7@1+ (50,0) [0|0] "" Vector__XXX
 SG_ VCLEFT_a168_movementTimeMs m168 : 24|7@1+ (50,0) [0|0] "" Vector__XXX
 SG_ VCLEFT_a169_currentPeakPosition m169 : 24|8@1+ (10,0) [0|0] "" Vector__XXX
 SG_ VCLEFT_a170_currentPeakPosition m170 : 24|8@1+ (10,0) [0|0] "" Vector__XXX
 SG_ VCLEFT_a173_isRHD m173 : 24|1@1+ (1,0) [0|0] "" Vector__XXX
 SG_ VCLEFT_a180_extHandlePWM m180 : 24|8@1+ (1,0) [0|0] "" Vector__XXX
 SG_ VCLEFT_a181_extHandlePWM m181 : 24|8@1+ (1,0) [0|0] "" Vector__XXX
 SG_ VCLEFT_a183_stopReason m183 : 24|4@1+ (1,0) [0|0] "" Vector__XXX
 SG_ VCLEFT_a186_temperature m186 : 24|8@1+ (0.5,-40) [0|0] "" Vector__XXX
 SG_ VCLEFT_a187_temperature m187 : 24|8@1+ (0.5,-40) [0|0] "" Vector__XXX
 SG_ VCLEFT_a188_temperature m188 : 24|8@1+ (0.5,-40) [0|0] "" Vector__XXX
 SG_ VCLEFT_a189_temperature m189 : 24|8@1+ (0.5,-40) [0|0] "" Vector__XXX
 SG_ VCLEFT_a192_motorOpenPhase m192 : 24|1@1+ (1,0) [0|0] "" Vector__XXX
 SG_ VCLEFT_a201_motorChannels m201 : 24|16@1+ (1,0) [0|0] "" Vector__XXX
 SG_ VCLEFT_a202_parkingAllowed m202 : 24|1@1+ (1,0) [0|0] "" Vector__XXX
 SG_ VCLEFT_a203_parkingAllowed m203 : 24|1@1+ (1,0) [0|0] "" Vector__XXX
 SG_ VCLEFT_a204_parkingAllowed m204 : 24|1@1+ (1,0) [0|0] "" Vector__XXX
 SG_ VCLEFT_a205_parkingAllowed m205 : 24|1@1+ (1,0) [0|0] "" Vector__XXX
 SG_ VCLEFT_a206_parkingAllowed m206 : 24|1@1+ (1,0) [0|0] "" Vector__XXX
 SG_ VCLEFT_a207_parkingAllowed m207 : 24|1@1+ (1,0) [0|0] "" Vector__XXX
 SG_ VCLEFT_a208_parkingAllowed m208 : 24|1@1+ (1,0) [0|0] "" Vector__XXX
 SG_ VCLEFT_a209_parkingAllowed m209 : 24|1@1+ (1,0) [0|0] "" Vector__XXX
 SG_ VCLEFT_a210_parkingAllowed m210 : 24|1@1+ (1,0) [0|0] "" Vector__XXX
 SG_ VCLEFT_a211_parkingAllowed m211 : 24|1@1+ (1,0) [0|0] "" Vector__XXX
 SG_ VCLEFT_a212_parkingAllowed m212 : 24|1@1+ (1,0) [0|0] "" Vector__XXX
 SG_ VCLEFT_a213_parkingAllowed m213 : 24|1@1+ (1,0) [0|0] "" Vector__XXX
 SG_ VCLEFT_a214_parkingAllowed m214 : 24|1@1+ (1,0) [0|0] "" Vector__XXX
 SG_ VCLEFT_a216_byte0 m216 : 24|8@1+ (1,0) [0|0] "" Vector__XXX
 SG_ VCLEFT_a217_byte5 m217 : 24|8@1+ (1,0) [0|0] "" Vector__XXX
 SG_ VCLEFT_a259_voltage m259 : 24|7@1+ (0.15,0) [0|0] "" Vector__XXX
 SG_ VCLEFT_a260_voltage m260 : 24|7@1+ (0.15,0) [0|0] "" Vector__XXX
 SG_ VCLEFT_a273_temperature m273 : 24|8@1+ (0.5,-40) [0|0] "" Vector__XXX
 SG_ VCLEFT_a274_temperature m274 : 24|8@1+ (0.5,-40) [0|0] "" Vector__XXX
 SG_ VCLEFT_a276_mirrorTiltXPosition m276 : 24|8@1+ (0.02,0) [0|0] "" Vector__XXX
 SG_ VCLEFT_a282_temperature m282 : 24|8@1+ (0.5,-40) [0|0] "" Vector__XXX
 SG_ VCLEFT_a283_temperature m283 : 24|8@1+ (0.5,-40) [0|0] "" Vector__XXX
 SG_ VCLEFT_a286_windowDirectionUp m286 : 24|1@1+ (1,0) [0|0] "" Vector__XXX
 SG_ VCLEFT_a287_windowDirectionUp m287 : 24|1@1+ (1,0) [0|0] "" Vector__XXX
 SG_ VCLEFT_a288_temperature m288 : 24|8@1+ (0.5,-40) [0|0] "" Vector__XXX
 SG_ VCLEFT_a289_temperature m289 : 24|8@1+ (0.5,-40) [0|0] "" Vector__XXX
 SG_ VCLEFT_a302_currentUnbalance m302 : 24|1@1+ (1,0) [0|0] "" Vector__XXX
 SG_ VCLEFT_a318_hardwareIdActual m318 : 24|8@1+ (1,0) [0|0] "" Vector__XXX
 SG_ VCLEFT_a330_maxCurrent m330 : 24|7@1+ (0.25,0) [0|0] "" Vector__XXX
 SG_ VCLEFT_a331_maxCurrent m331 : 24|7@1+ (0.25,0) [0|0] "" Vector__XXX
 SG_ VCLEFT_a352_liftgateVelocityNear m352 : 24|7@1- (0.5,-17) [0|0] "" Vector__XXX
 SG_ VCLEFT_a355_liftgatePosition m355 : 24|7@1- (1,43) [0|0] "" Vector__XXX
 SG_ VCLEFT_a357_liftgatePosition m357 : 24|7@1- (1,43) [0|0] "" Vector__XXX
 SG_ VCLEFT_a360_accelVar m360 : 24|10@1+ (0.0002,0) [0|0] "" Vector__XXX
 SG_ VCLEFT_a363_prevOpenSetpoint m363 : 24|7@1- (1,50) [0|0] "" Vector__XXX
 SG_ VCLEFT_a374_fog m374 : 24|2@1+ (1,0) [0|0] "" Vector__XXX
 SG_ VCLEFT_a381_pitchEstimateRHS m381 : 24|7@1- (0.001,0) [0|0] "" Vector__XXX
 SG_ VCLEFT_a391_averageGrade m391 : 24|7@1- (0.01,0) [0|0] "" Vector__XXX
 SG_ VCLEFT_a392_newLocationAccuracy m392 : 24|6@1+ (0.2,0) [0|0] "" Vector__XXX
 SG_ VCLEFT_a444_channel m444 : 24|8@1+ (1,0) [0|0] "" Vector__XXX
 SG_ VCLEFT_a445_expectedMSB m445 : 24|8@1+ (1,0) [0|0] "" Vector__XXX
 SG_ VCLEFT_a454_txErrorFR m454 : 24|3@1+ (1,0) [0|0] "" Vector__XXX
 SG_ VCLEFT_a480_vsUndervoltage m480 : 24|1@1+ (1,0) [0|0] "" Vector__XXX
 SG_ VCLEFT_a481_timeout m481 : 24|1@1+ (1,0) [0|0] "" Vector__XXX
 SG_ VCLEFT_a482_overTempShutdown m482 : 24|1@1+ (1,0) [0|0] "" Vector__XXX
 SG_ VCLEFT_a499_localEpbmStatus m499 : 24|5@1+ (1,0) [0|0] "" Vector__XXX
 SG_ VCLEFT_a500_mismatchedState m500 : 24|3@1+ (1,0) [0|0] "" Vector__XXX
 SG_ VCLEFT_a523_control2Byte1 m523 : 24|8@1+ (1,0) [0|0] "" Vector__XXX
 SG_ VCLEFT_a525_initialLVBatteryType m525 : 24|3@1+ (1,0) [0|0] "" Vector__XXX
 SG_ VCLEFT_a526_pcbaTemperature m526 : 24|16@1- (0.125,55) [0|0] "" Vector__XXX
 SG_ VCLEFT_a545_frunkOpen m545 : 24|1@1+ (1,0) [0|0] "" Vector__XXX
 SG_ VCLEFT_a546_mirrorMaxFoldCurrent m546 : 24|7@1- (0.05,0) [0|0] "" Vector__XXX
 SG_ VCLEFT_a551_interiorRelease_0000 m551 : 24|8@1+ (1,0) [0|0] "" Vector__XXX
 SG_ VCLEFT_a599_initialLVBatteryType m599 : 24|3@1+ (1,0) [0|0] "" Vector__XXX
 SG_ VCLEFT_a021_Task100msStarved m21 : 23|1@1+ (1,0) [0|0] "" Vector__XXX
 SG_ VCLEFT_a066_totalShortPeriods m66 : 23|16@1+ (10,0) [0|0] "" Vector__XXX
 SG_ VCLEFT_a086_VEH_thermalStatus m86 : 23|1@1+ (1,0) [0|0] "" Vector__XXX
 SG_ VCLEFT_a087_PARTY_thermalControl m87 : 23|1@1+ (1,0) [0|0] "" Vector__XXX
 SG_ VCLEFT_a088_PARTY_thermalControl m88 : 23|1@1+ (1,0) [0|0] "" Vector__XXX
 SG_ VCLEFT_a089_CH_party3 m89 : 23|1@1+ (1,0) [0|0] "" Vector__XXX
 SG_ VCLEFT_a098_PARTY_temperature m98 : 23|1@1+ (1,0) [0|0] "" Vector__XXX
 SG_ VCLEFT_a104_VEH_thermalStatus m104 : 23|1@1+ (1,0) [0|0] "" Vector__XXX
 SG_ VCLEFT_a107_PT_status m107 : 23|1@1+ (1,0) [0|0] "" Vector__XXX
 SG_ VCLEFT_a108_PARTY_temperature m108 : 23|1@1+ (1,0) [0|0] "" Vector__XXX
 SG_ VCLEFT_a109_BDY_imuOffsets m109 : 23|1@1+ (1,0) [0|0] "" Vector__XXX
 SG_ VCLEFT_a110_VEH_bmpDebug m110 : 23|1@1+ (1,0) [0|0] "" Vector__XXX
 SG_ VCLEFT_a111_RIPC_switchStatus m111 : 23|1@1+ (1,0) [0|0] "" Vector__XXX
 SG_ VCLEFT_a112_LIPC_switchStatus m112 : 23|1@1+ (1,0) [0|0] "" Vector__XXX
 SG_ VCLEFT_a113_VEH_solarData m113 : 23|1@1+ (1,0) [0|0] "" Vector__XXX
 SG_ VCLEFT_a114_PARTY_wheelRotation m114 : 23|1@1+ (1,0) [0|0] "" Vector__XXX
 SG_ VCLEFT_a115_VEH_BLEResetRequest m115 : 23|1@1+ (1,0) [0|0] "" Vector__XXX
 SG_ VCLEFT_a116_VEH_thsStatus m116 : 23|1@1+ (1,0) [0|0] "" Vector__XXX
 SG_ VCLEFT_a117_VEH_restraintStatus m117 : 23|1@1+ (1,0) [0|0] "" Vector__XXX
 SG_ VCLEFT_a118_VEH_vehicleStatus m118 : 23|1@1+ (1,0) [0|0] "" Vector__XXX
 SG_ VCLEFT_a120_PARTY_speed m120 : 23|1@1+ (1,0) [0|0] "" Vector__XXX
 SG_ VCLEFT_a129_VDS_HC m129 : 23|1@1+ (1,0) [0|0] "" Vector__XXX
 SG_ VCLEFT_a130_PVDD_OVFL m130 : 23|1@1+ (1,0) [0|0] "" Vector__XXX
 SG_ VCLEFT_a166_CAL_CLEAR_POS m166 : 23|1@1+ (1,0) [0|0] "" Vector__XXX
 SG_ VCLEFT_a173_btnSwPackAutoDownRR m173 : 23|1@1+ (1,0) [0|0] "" Vector__XXX
 SG_ VCLEFT_a192_hardwareOvercurrent m192 : 23|1@1+ (1,0) [0|0] "" Vector__XXX
 SG_ VCLEFT_a200_motorChannels m200 : 23|16@1+ (1,0) [0|0] "" Vector__XXX
 SG_ VCLEFT_a202_winchReleaseAllowed m202 : 23|1@1+ (1,0) [0|0] "" Vector__XXX
 SG_ VCLEFT_a203_winchReleaseAllowed m203 : 23|1@1+ (1,0) [0|0] "" Vector__XXX
 SG_ VCLEFT_a204_winchReleaseAllowed m204 : 23|1@1+ (1,0) [0|0] "" Vector__XXX
 SG_ VCLEFT_a205_winchReleaseAllowed m205 : 23|1@1+ (1,0) [0|0] "" Vector__XXX
 SG_ VCLEFT_a206_winchReleaseAllowed m206 : 23|1@1+ (1,0) [0|0] "" Vector__XXX
 SG_ VCLEFT_a207_winchReleaseAllowed m207 : 23|1@1+ (1,0) [0|0] "" Vector__XXX
 SG_ VCLEFT_a208_winchReleaseAllowed m208 : 23|1@1+ (1,0) [0|0] "" Vector__XXX
 SG_ VCLEFT_a209_winchReleaseAllowed m209 : 23|1@1+ (1,0) [0|0] "" Vector__XXX
 SG_ VCLEFT_a210_winchReleaseAllowed m210 : 23|1@1+ (1,0) [0|0] "" Vector__XXX
 SG_ VCLEFT_a211_winchReleaseAllowed m211 : 23|1@1+ (1,0) [0|0] "" Vector__XXX
 SG_ VCLEFT_a212_winchReleaseAllowed m212 : 23|1@1+ (1,0) [0|0] "" Vector__XXX
 SG_ VCLEFT_a213_winchReleaseAllowed m213 : 23|1@1+ (1,0) [0|0] "" Vector__XXX
 SG_ VCLEFT_a214_winchReleaseAllowed m214 : 23|1@1+ (1,0) [0|0] "" Vector__XXX
 SG_ VCLEFT_a302_motorLostPhase m302 : 23|1@1+ (1,0) [0|0] "" Vector__XXX
 SG_ VCLEFT_a480_disableOutputFault m480 : 23|1@1+ (1,0) [0|0] "" Vector__XXX
 SG_ VCLEFT_a482_resetBar m482 : 23|1@1+ (1,0) [0|0] "" Vector__XXX
 SG_ VCLEFT_a545_factoryGated m545 : 23|1@1+ (1,0) [0|0] "" Vector__XXX
 SG_ VCLEFT_a021_Task100msLate m21 : 22|1@1+ (1,0) [0|0] "" Vector__XXX
 SG_ VCLEFT_a086_VEH_systemStatus m86 : 22|1@1+ (1,0) [0|0] "" Vector__XXX
 SG_ VCLEFT_a087_PARTY_temperature m87 : 22|1@1+ (1,0) [0|0] "" Vector__XXX
 SG_ VCLEFT_a088_PARTY_temperature m88 : 22|1@1+ (1,0) [0|0] "" Vector__XXX
 SG_ VCLEFT_a089_CH_party1 m89 : 22|1@1+ (1,0) [0|0] "" Vector__XXX
 SG_ VCLEFT_a098_PARTY_status m98 : 22|1@1+ (1,0) [0|0] "" Vector__XXX
 SG_ VCLEFT_a104_BDY_bodyControls3 m104 : 22|1@1+ (1,0) [0|0] "" Vector__XXX
 SG_ VCLEFT_a107_PT_ptNm m107 : 22|1@1+ (1,0) [0|0] "" Vector__XXX
 SG_ VCLEFT_a108_PARTY_status m108 : 22|1@1+ (1,0) [0|0] "" Vector__XXX
 SG_ VCLEFT_a109_PARTY_inertial1 m109 : 22|1@1+ (1,0) [0|0] "" Vector__XXX
 SG_ VCLEFT_a110_VEH_vin m110 : 22|1@1+ (1,0) [0|0] "" Vector__XXX
 SG_ VCLEFT_a111_RIPC_remoteADC m111 : 22|1@1+ (1,0) [0|0] "" Vector__XXX
 SG_ VCLEFT_a112_LIPC_remoteADC m112 : 22|1@1+ (1,0) [0|0] "" Vector__XXX
 SG_ VCLEFT_a113_VEH_corianderVehicle m113 : 22|1@1+ (1,0) [0|0] "" Vector__XXX
 SG_ VCLEFT_a114_VEH_status m114 : 22|1@1+ (1,0) [0|0] "" Vector__XXX
 SG_ VCLEFT_a115_VEH_authentication m115 : 22|1@1+ (1,0) [0|0] "" Vector__XXX
 SG_ VCLEFT_a116_VEH_seatStatus m116 : 22|1@1+ (1,0) [0|0] "" Vector__XXX
 SG_ VCLEFT_a117_VEH_LVPowerState m117 : 22|1@1+ (1,0) [0|0] "" Vector__XXX
 SG_ VCLEFT_a118_VEH_coolant m118 : 22|1@1+ (1,0) [0|0] "" Vector__XXX
 SG_ VCLEFT_a120_PARTY_locStatus m120 : 22|1@1+ (1,0) [0|0] "" Vector__XXX
 SG_ VCLEFT_a129_VDS_LB m129 : 22|1@1+ (1,0) [0|0] "" Vector__XXX
 SG_ VCLEFT_a130_PVDD_UVFL m130 : 22|1@1+ (1,0) [0|0] "" Vector__XXX
 SG_ VCLEFT_a166_CAL_CLEAR_SWITCH m166 : 22|1@1+ (1,0) [0|0] "" Vector__XXX
 SG_ VCLEFT_a173_btnSwPackDownRR m173 : 22|1@1+ (1,0) [0|0] "" Vector__XXX
 SG_ VCLEFT_a192_overVoltage m192 : 22|1@1+ (1,0) [0|0] "" Vector__XXX
 SG_ VCLEFT_a202_winchAllowed m202 : 22|1@1+ (1,0) [0|0] "" Vector__XXX
 SG_ VCLEFT_a203_winchAllowed m203 : 22|1@1+ (1,0) [0|0] "" Vector__XXX
 SG_ VCLEFT_a204_winchAllowed m204 : 22|1@1+ (1,0) [0|0] "" Vector__XXX
 SG_ VCLEFT_a205_winchAllowed m205 : 22|1@1+ (1,0) [0|0] "" Vector__XXX
 SG_ VCLEFT_a206_winchAllowed m206 : 22|1@1+ (1,0) [0|0] "" Vector__XXX
 SG_ VCLEFT_a207_winchAllowed m207 : 22|1@1+ (1,0) [0|0] "" Vector__XXX
 SG_ VCLEFT_a208_winchAllowed m208 : 22|1@1+ (1,0) [0|0] "" Vector__XXX
 SG_ VCLEFT_a209_winchAllowed m209 : 22|1@1+ (1,0) [0|0] "" Vector__XXX
 SG_ VCLEFT_a210_winchAllowed m210 : 22|1@1+ (1,0) [0|0] "" Vector__XXX
 SG_ VCLEFT_a211_winchAllowed m211 : 22|1@1+ (1,0) [0|0] "" Vector__XXX
 SG_ VCLEFT_a212_winchAllowed m212 : 22|1@1+ (1,0) [0|0] "" Vector__XXX
 SG_ VCLEFT_a213_winchAllowed m213 : 22|1@1+ (1,0) [0|0] "" Vector__XXX
 SG_ VCLEFT_a214_winchAllowed m214 : 22|1@1+ (1,0) [0|0] "" Vector__XXX
 SG_ VCLEFT_a276_mirrorDip m276 : 22|1@1+ (1,0) [0|0] "" Vector__XXX
 SG_ VCLEFT_a302_overloadFault m302 : 22|1@1+ (1,0) [0|0] "" Vector__XXX
 SG_ VCLEFT_a374_brake m374 : 22|2@1+ (1,0) [0|0] "" Vector__XXX
 SG_ VCLEFT_a480_unexpectedLock m480 : 22|1@1+ (1,0) [0|0] "" Vector__XXX
 SG_ VCLEFT_a482_spiFault m482 : 22|1@1+ (1,0) [0|0] "" Vector__XXX
 SG_ VCLEFT_a545_serviceMode m545 : 22|1@1+ (1,0) [0|0] "" Vector__XXX
 SG_ VCLEFT_a012_ExternalReset m12 : 21|1@1+ (1,0) [0|0] "" Vector__XXX
 SG_ VCLEFT_a021_Task10msMissed m21 : 21|1@1+ (1,0) [0|0] "" Vector__XXX
 SG_ VCLEFT_a086_VEH_lightStatus m86 : 21|1@1+ (1,0) [0|0] "" Vector__XXX
 SG_ VCLEFT_a087_PARTY_status m87 : 21|1@1+ (1,0) [0|0] "" Vector__XXX
 SG_ VCLEFT_a088_PARTY_status m88 : 21|1@1+ (1,0) [0|0] "" Vector__XXX
 SG_ VCLEFT_a089_CH_status m89 : 21|1@1+ (1,0) [0|0] "" Vector__XXX
 SG_ VCLEFT_a098_VEH_torque m98 : 21|1@1+ (1,0) [0|0] "" Vector__XXX
 SG_ VCLEFT_a103_VEH_evseStatus m103 : 21|1@1+ (1,0) [0|0] "" Vector__XXX
 SG_ VCLEFT_a104_VEH_bodyControls3 m104 : 21|1@1+ (1,0) [0|0] "" Vector__XXX
 SG_ VCLEFT_a107_VEH_powerAvailable m107 : 21|1@1+ (1,0) [0|0] "" Vector__XXX
 SG_ VCLEFT_a108_PARTY_torque m108 : 21|1@1+ (1,0) [0|0] "" Vector__XXX
 SG_ VCLEFT_a109_VEH_imuOffsets m109 : 21|1@1+ (1,0) [0|0] "" Vector__XXX
 SG_ VCLEFT_a110_VEH_mismatchFault m110 : 21|1@1+ (1,0) [0|0] "" Vector__XXX
 SG_ VCLEFT_a111_RIPC_railStatus m111 : 21|1@1+ (1,0) [0|0] "" Vector__XXX
 SG_ VCLEFT_a112_LIPC_railStatus m112 : 21|1@1+ (1,0) [0|0] "" Vector__XXX
 SG_ VCLEFT_a113_VEH_peripheralPowerR m113 : 21|1@1+ (1,0) [0|0] "" Vector__XXX
 SG_ VCLEFT_a114_VEH_party3 m114 : 21|1@1+ (1,0) [0|0] "" Vector__XXX
 SG_ VCLEFT_a115_VEH_vehNm m115 : 21|1@1+ (1,0) [0|0] "" Vector__XXX
 SG_ VCLEFT_a116_VEH_lightStatus m116 : 21|1@1+ (1,0) [0|0] "" Vector__XXX
 SG_ VCLEFT_a117_VEH_hvacBlowerFdb m117 : 21|1@1+ (1,0) [0|0] "" Vector__XXX
 SG_ VCLEFT_a118_VEH_LVPowerState m118 : 21|1@1+ (1,0) [0|0] "" Vector__XXX
 SG_ VCLEFT_a119_PARTY_steerAngle m119 : 21|1@1+ (1,0) [0|0] "" Vector__XXX
 SG_ VCLEFT_a120_VEH_torque m120 : 21|1@1+ (1,0) [0|0] "" Vector__XXX
 SG_ VCLEFT_a129_VDS_HB m129 : 21|1@1+ (1,0) [0|0] "" Vector__XXX
 SG_ VCLEFT_a130_TEMP_FLAG4 m130 : 21|1@1+ (1,0) [0|0] "" Vector__XXX
 SG_ VCLEFT_a166_THERMAL_BLOCKED m166 : 21|1@1+ (1,0) [0|0] "" Vector__XXX
 SG_ VCLEFT_a173_btnSwPackAutoDownRF m173 : 21|1@1+ (1,0) [0|0] "" Vector__XXX
 SG_ VCLEFT_a192_underVoltage m192 : 21|1@1+ (1,0) [0|0] "" Vector__XXX
 SG_ VCLEFT_a202_serviceAllowed m202 : 21|1@1+ (1,0) [0|0] "" Vector__XXX
 SG_ VCLEFT_a203_serviceAllowed m203 : 21|1@1+ (1,0) [0|0] "" Vector__XXX
 SG_ VCLEFT_a204_serviceAllowed m204 : 21|1@1+ (1,0) [0|0] "" Vector__XXX
 SG_ VCLEFT_a205_serviceAllowed m205 : 21|1@1+ (1,0) [0|0] "" Vector__XXX
 SG_ VCLEFT_a206_serviceAllowed m206 : 21|1@1+ (1,0) [0|0] "" Vector__XXX
 SG_ VCLEFT_a207_serviceAllowed m207 : 21|1@1+ (1,0) [0|0] "" Vector__XXX
 SG_ VCLEFT_a208_serviceAllowed m208 : 21|1@1+ (1,0) [0|0] "" Vector__XXX
 SG_ VCLEFT_a209_serviceAllowed m209 : 21|1@1+ (1,0) [0|0] "" Vector__XXX
 SG_ VCLEFT_a210_serviceAllowed m210 : 21|1@1+ (1,0) [0|0] "" Vector__XXX
 SG_ VCLEFT_a211_serviceAllowed m211 : 21|1@1+ (1,0) [0|0] "" Vector__XXX
 SG_ VCLEFT_a212_serviceAllowed m212 : 21|1@1+ (1,0) [0|0] "" Vector__XXX
 SG_ VCLEFT_a213_serviceAllowed m213 : 21|1@1+ (1,0) [0|0] "" Vector__XXX
 SG_ VCLEFT_a214_serviceAllowed m214 : 21|1@1+ (1,0) [0|0] "" Vector__XXX
 SG_ VCLEFT_a275_overTemperature m275 : 21|1@1+ (1,0) [0|0] "" Vector__XXX
 SG_ VCLEFT_a302_motorStall m302 : 21|1@1+ (1,0) [0|0] "" Vector__XXX
 SG_ VCLEFT_a311_overTemperature m311 : 21|1@1+ (1,0) [0|0] "" Vector__XXX
 SG_ VCLEFT_a312_overTemperature m312 : 21|1@1+ (1,0) [0|0] "" Vector__XXX
 SG_ VCLEFT_a313_overTemperature m313 : 21|1@1+ (1,0) [0|0] "" Vector__XXX
 SG_ VCLEFT_a314_overTemperature m314 : 21|1@1+ (1,0) [0|0] "" Vector__XXX
 SG_ VCLEFT_a315_overTemperature m315 : 21|1@1+ (1,0) [0|0] "" Vector__XXX
 SG_ VCLEFT_a341_reverse m341 : 21|1@1+ (1,0) [0|0] "" Vector__XXX
 SG_ VCLEFT_a480_overcurrent m480 : 21|1@1+ (1,0) [0|0] "" Vector__XXX
 SG_ VCLEFT_a005_faults0 m5 : 20|12@1+ (1,0) [0|0] "" Vector__XXX
 SG_ VCLEFT_a006_fault m6 : 20|4@1+ (1,0) [0|0] "" Vector__XXX
 SG_ VCLEFT_a012_DebugReset m12 : 20|1@1+ (1,0) [0|0] "" Vector__XXX
 SG_ VCLEFT_a021_Task10msStarved m21 : 20|1@1+ (1,0) [0|0] "" Vector__XXX
 SG_ VCLEFT_a086_VEH_LVPowerState m86 : 20|1@1+ (1,0) [0|0] "" Vector__XXX
 SG_ VCLEFT_a087_PARTY_torque m87 : 20|1@1+ (1,0) [0|0] "" Vector__XXX
 SG_ VCLEFT_a088_PARTY_torque m88 : 20|1@1+ (1,0) [0|0] "" Vector__XXX
 SG_ VCLEFT_a089_BDY_status m89 : 20|1@1+ (1,0) [0|0] "" Vector__XXX
 SG_ VCLEFT_a098_VEH_temperature m98 : 20|1@1+ (1,0) [0|0] "" Vector__XXX
 SG_ VCLEFT_a100_OBD m100 : 20|1@1+ (1,0) [0|0] "" Vector__XXX
 SG_ VCLEFT_a101_BDY_locState m101 : 20|1@1+ (1,0) [0|0] "" Vector__XXX
 SG_ VCLEFT_a103_PT_status m103 : 20|1@1+ (1,0) [0|0] "" Vector__XXX
 SG_ VCLEFT_a104_VEH_bodyControls m104 : 20|1@1+ (1,0) [0|0] "" Vector__XXX
 SG_ VCLEFT_a106_CH_alertMatrix m106 : 20|1@1+ (1,0) [0|0] "" Vector__XXX
 SG_ VCLEFT_a107_VEH_bmbMinMax m107 : 20|1@1+ (1,0) [0|0] "" Vector__XXX
 SG_ VCLEFT_a108_VEH_status m108 : 20|1@1+ (1,0) [0|0] "" Vector__XXX
 SG_ VCLEFT_a109_VEH_status m109 : 20|1@1+ (1,0) [0|0] "" Vector__XXX
 SG_ VCLEFT_a110_VEH_vehNm m110 : 20|1@1+ (1,0) [0|0] "" Vector__XXX
 SG_ VCLEFT_a111_RIPC_epbPrivateState m111 : 20|1@1+ (1,0) [0|0] "" Vector__XXX
 SG_ VCLEFT_a112_LIPC_epbPrivateState m112 : 20|1@1+ (1,0) [0|0] "" Vector__XXX
 SG_ VCLEFT_a113_VEH_vehicleControl2 m113 : 20|1@1+ (1,0) [0|0] "" Vector__XXX
 SG_ VCLEFT_a114_PARTY_party3 m114 : 20|1@1+ (1,0) [0|0] "" Vector__XXX
 SG_ VCLEFT_a115_BDY_ChildSeatStatus m115 : 20|1@1+ (1,0) [0|0] "" Vector__XXX
 SG_ VCLEFT_a116_VEH_LVPowerState m116 : 20|1@1+ (1,0) [0|0] "" Vector__XXX
 SG_ VCLEFT_a117_VEH_vehNm m117 : 20|1@1+ (1,0) [0|0] "" Vector__XXX
 SG_ VCLEFT_a118_VEH_okToUseHighPwr m118 : 20|1@1+ (1,0) [0|0] "" Vector__XXX
 SG_ VCLEFT_a119_CH_steerAngle m119 : 20|1@1+ (1,0) [0|0] "" Vector__XXX
 SG_ VCLEFT_a120_PARTY_torque m120 : 20|1@1+ (1,0) [0|0] "" Vector__XXX
 SG_ VCLEFT_a129_VDS_LA m129 : 20|1@1+ (1,0) [0|0] "" Vector__XXX
 SG_ VCLEFT_a130_vccUnderVoltage m130 : 20|1@1+ (1,0) [0|0] "" Vector__XXX
 SG_ VCLEFT_a131_thOverTemperature m131 : 20|1@1+ (1,0) [0|0] "" Vector__XXX
 SG_ VCLEFT_a152_causedByBackoffs m152 : 20|1@1+ (1,0) [0|0] "" Vector__XXX
 SG_ VCLEFT_a153_causedByBackoffs m153 : 20|1@1+ (1,0) [0|0] "" Vector__XXX
 SG_ VCLEFT_a166_THERMAL m166 : 20|1@1+ (1,0) [0|0] "" Vector__XXX
 SG_ VCLEFT_a173_btnSwPackDownRF m173 : 20|1@1+ (1,0) [0|0] "" Vector__XXX
 SG_ VCLEFT_a192_motorControlError m192 : 20|1@1+ (1,0) [0|0] "" Vector__XXX
 SG_ VCLEFT_a202_startAllowed m202 : 20|1@1+ (1,0) [0|0] "" Vector__XXX
 SG_ VCLEFT_a203_startAllowed m203 : 20|1@1+ (1,0) [0|0] "" Vector__XXX
 SG_ VCLEFT_a204_startAllowed m204 : 20|1@1+ (1,0) [0|0] "" Vector__XXX
 SG_ VCLEFT_a205_startAllowed m205 : 20|1@1+ (1,0) [0|0] "" Vector__XXX
 SG_ VCLEFT_a206_startAllowed m206 : 20|1@1+ (1,0) [0|0] "" Vector__XXX
 SG_ VCLEFT_a207_startAllowed m207 : 20|1@1+ (1,0) [0|0] "" Vector__XXX
 SG_ VCLEFT_a208_startAllowed m208 : 20|1@1+ (1,0) [0|0] "" Vector__XXX
 SG_ VCLEFT_a209_startAllowed m209 : 20|1@1+ (1,0) [0|0] "" Vector__XXX
 SG_ VCLEFT_a210_startAllowed m210 : 20|1@1+ (1,0) [0|0] "" Vector__XXX
 SG_ VCLEFT_a211_startAllowed m211 : 20|1@1+ (1,0) [0|0] "" Vector__XXX
 SG_ VCLEFT_a212_startAllowed m212 : 20|1@1+ (1,0) [0|0] "" Vector__XXX
 SG_ VCLEFT_a213_startAllowed m213 : 20|1@1+ (1,0) [0|0] "" Vector__XXX
 SG_ VCLEFT_a214_startAllowed m214 : 20|1@1+ (1,0) [0|0] "" Vector__XXX
 SG_ VCLEFT_a275_overCurrent m275 : 20|1@1+ (1,0) [0|0] "" Vector__XXX
 SG_ VCLEFT_a285_watchdogTimeout m285 : 20|1@1+ (1,0) [0|0] "" Vector__XXX
 SG_ VCLEFT_a302_overRMSCurrent m302 : 20|1@1+ (1,0) [0|0] "" Vector__XXX
 SG_ VCLEFT_a311_overCurrent m311 : 20|1@1+ (1,0) [0|0] "" Vector__XXX
 SG_ VCLEFT_a312_overCurrent m312 : 20|1@1+ (1,0) [0|0] "" Vector__XXX
 SG_ VCLEFT_a313_overCurrent m313 : 20|1@1+ (1,0) [0|0] "" Vector__XXX
 SG_ VCLEFT_a314_overCurrent m314 : 20|1@1+ (1,0) [0|0] "" Vector__XXX
 SG_ VCLEFT_a315_overCurrent m315 : 20|1@1+ (1,0) [0|0] "" Vector__XXX
 SG_ VCLEFT_a335_SelfTestStatus m335 : 20|1@1+ (1,0) [0|0] "" Vector__XXX
 SG_ VCLEFT_a341_fog m341 : 20|1@1+ (1,0) [0|0] "" Vector__XXX
 SG_ VCLEFT_a355_liftgateLastState m355 : 20|4@1+ (1,0) [0|0] "" Vector__XXX
 SG_ VCLEFT_a374_tail m374 : 20|2@1+ (1,0) [0|0] "" Vector__XXX
 SG_ VCLEFT_a480_deviceError m480 : 20|1@1+ (1,0) [0|0] "" Vector__XXX
 SG_ VCLEFT_a520_gtwEpbConfig m520 : 20|4@1+ (1,0) [0|0] "" Vector__XXX
 SG_ VCLEFT_a617_VEH_defogInfoMessage m617 : 20|1@1+ (1,0) [0|0] "" Vector__XXX
 SG_ VCLEFT_a012_CheckstopReset m12 : 19|1@1+ (1,0) [0|0] "" Vector__XXX
 SG_ VCLEFT_a021_Task10msLate m21 : 19|1@1+ (1,0) [0|0] "" Vector__XXX
 SG_ VCLEFT_a082_RIPC_remoteMux m82 : 19|1@1+ (1,0) [0|0] "" Vector__XXX
 SG_ VCLEFT_a083_LIPC_HSDFaults m83 : 19|1@1+ (1,0) [0|0] "" Vector__XXX
 SG_ VCLEFT_a086_VEH_12VBatteryStatus m86 : 19|1@1+ (1,0) [0|0] "" Vector__XXX
 SG_ VCLEFT_a087_VEH_status m87 : 19|1@1+ (1,0) [0|0] "" Vector__XXX
 SG_ VCLEFT_a088_VEH_status m88 : 19|1@1+ (1,0) [0|0] "" Vector__XXX
 SG_ VCLEFT_a089_BDY_party1 m89 : 19|1@1+ (1,0) [0|0] "" Vector__XXX
 SG_ VCLEFT_a090_CH_eacMonitor m90 : 19|1@1+ (1,0) [0|0] "" Vector__XXX
 SG_ VCLEFT_a092_VEH_vehNm m92 : 19|1@1+ (1,0) [0|0] "" Vector__XXX
 SG_ VCLEFT_a093_VEH_vehNm m93 : 19|1@1+ (1,0) [0|0] "" Vector__XXX
 SG_ VCLEFT_a098_VEH_thermalControl m98 : 19|1@1+ (1,0) [0|0] "" Vector__XXX
 SG_ VCLEFT_a100_CH m100 : 19|1@1+ (1,0) [0|0] "" Vector__XXX
 SG_ VCLEFT_a101_VEH_locState m101 : 19|1@1+ (1,0) [0|0] "" Vector__XXX
 SG_ VCLEFT_a102_VEH_rods m102 : 19|1@1+ (1,0) [0|0] "" Vector__XXX
 SG_ VCLEFT_a103_PT_ptNm m103 : 19|1@1+ (1,0) [0|0] "" Vector__XXX
 SG_ VCLEFT_a104_VEH_chNm m104 : 19|1@1+ (1,0) [0|0] "" Vector__XXX
 SG_ VCLEFT_a106_CH_dcdcRailStatus m106 : 19|1@1+ (1,0) [0|0] "" Vector__XXX
 SG_ VCLEFT_a107_VEH_thermalStatus m107 : 19|1@1+ (1,0) [0|0] "" Vector__XXX
 SG_ VCLEFT_a108_VEH_torque m108 : 19|1@1+ (1,0) [0|0] "" Vector__XXX
 SG_ VCLEFT_a109_PARTY_collision m109 : 19|1@1+ (1,0) [0|0] "" Vector__XXX
 SG_ VCLEFT_a110_VEH_updateStatus m110 : 19|1@1+ (1,0) [0|0] "" Vector__XXX
 SG_ VCLEFT_a111_RIPC_LVPowerState m111 : 19|1@1+ (1,0) [0|0] "" Vector__XXX
 SG_ VCLEFT_a112_LIPC_LVPowerState m112 : 19|1@1+ (1,0) [0|0] "" Vector__XXX
 SG_ VCLEFT_a113_VEH_vehicleControl m113 : 19|1@1+ (1,0) [0|0] "" Vector__XXX
 SG_ VCLEFT_a114_CH_wheelSpeeds m114 : 19|1@1+ (1,0) [0|0] "" Vector__XXX
 SG_ VCLEFT_a115_VEH_ChildSeatStatus m115 : 19|1@1+ (1,0) [0|0] "" Vector__XXX
 SG_ VCLEFT_a116_VEH_hvacStatus m116 : 19|1@1+ (1,0) [0|0] "" Vector__XXX
 SG_ VCLEFT_a117_PARTY_epbmStatus m117 : 19|1@1+ (1,0) [0|0] "" Vector__XXX
 SG_ VCLEFT_a118_VEH_status m118 : 19|1@1+ (1,0) [0|0] "" Vector__XXX
 SG_ VCLEFT_a119_PARTY_rightStalk m119 : 19|1@1+ (1,0) [0|0] "" Vector__XXX
 SG_ VCLEFT_a120_PARTY_systemStatus m120 : 19|1@1+ (1,0) [0|0] "" Vector__XXX
 SG_ VCLEFT_a122_VEH_occupancy2 m122 : 19|1@1+ (1,0) [0|0] "" Vector__XXX
 SG_ VCLEFT_a129_VDS_HA m129 : 19|1@1+ (1,0) [0|0] "" Vector__XXX
 SG_ VCLEFT_a130_lossOfSpeedLock m130 : 19|1@1+ (1,0) [0|0] "" Vector__XXX
 SG_ VCLEFT_a131_vglUnderVoltage m131 : 19|1@1+ (1,0) [0|0] "" Vector__XXX
 SG_ VCLEFT_a164_lastState m164 : 19|4@1+ (1,0) [0|0] "" Vector__XXX
 SG_ VCLEFT_a166_PINCH_OVERRIDE m166 : 19|1@1+ (1,0) [0|0] "" Vector__XXX
 SG_ VCLEFT_a173_btnSwPackAutoDownLR m173 : 19|1@1+ (1,0) [0|0] "" Vector__XXX
 SG_ VCLEFT_a183_lastState m183 : 19|3@1+ (1,0) [0|0] "" Vector__XXX
 SG_ VCLEFT_a192_fetTempIrrational m192 : 19|1@1+ (1,0) [0|0] "" Vector__XXX
 SG_ VCLEFT_a202_parkAllowed m202 : 19|1@1+ (1,0) [0|0] "" Vector__XXX
 SG_ VCLEFT_a203_parkAllowed m203 : 19|1@1+ (1,0) [0|0] "" Vector__XXX
 SG_ VCLEFT_a204_parkAllowed m204 : 19|1@1+ (1,0) [0|0] "" Vector__XXX
 SG_ VCLEFT_a205_parkAllowed m205 : 19|1@1+ (1,0) [0|0] "" Vector__XXX
 SG_ VCLEFT_a206_parkAllowed m206 : 19|1@1+ (1,0) [0|0] "" Vector__XXX
 SG_ VCLEFT_a207_parkAllowed m207 : 19|1@1+ (1,0) [0|0] "" Vector__XXX
 SG_ VCLEFT_a208_parkAllowed m208 : 19|1@1+ (1,0) [0|0] "" Vector__XXX
 SG_ VCLEFT_a209_parkAllowed m209 : 19|1@1+ (1,0) [0|0] "" Vector__XXX
 SG_ VCLEFT_a210_parkAllowed m210 : 19|1@1+ (1,0) [0|0] "" Vector__XXX
 SG_ VCLEFT_a211_parkAllowed m211 : 19|1@1+ (1,0) [0|0] "" Vector__XXX
 SG_ VCLEFT_a212_parkAllowed m212 : 19|1@1+ (1,0) [0|0] "" Vector__XXX
 SG_ VCLEFT_a213_parkAllowed m213 : 19|1@1+ (1,0) [0|0] "" Vector__XXX
 SG_ VCLEFT_a214_parkAllowed m214 : 19|1@1+ (1,0) [0|0] "" Vector__XXX
 SG_ VCLEFT_a216_monitor_MIA m216 : 19|1@1+ (1,0) [0|0] "" Vector__XXX
 SG_ VCLEFT_a275_underCurrent m275 : 19|1@1+ (1,0) [0|0] "" Vector__XXX
 SG_ VCLEFT_a276_mirrorState m276 : 19|3@1+ (1,0) [0|0] "" Vector__XXX
 SG_ VCLEFT_a285_pwmOutputFault m285 : 19|1@1+ (1,0) [0|0] "" Vector__XXX
 SG_ VCLEFT_a302_moduleOverCurrent m302 : 19|1@1+ (1,0) [0|0] "" Vector__XXX
 SG_ VCLEFT_a311_underCurrent m311 : 19|1@1+ (1,0) [0|0] "" Vector__XXX
 SG_ VCLEFT_a312_underCurrent m312 : 19|1@1+ (1,0) [0|0] "" Vector__XXX
 SG_ VCLEFT_a313_underCurrent m313 : 19|1@1+ (1,0) [0|0] "" Vector__XXX
 SG_ VCLEFT_a314_underCurrent m314 : 19|1@1+ (1,0) [0|0] "" Vector__XXX
 SG_ VCLEFT_a315_underCurrent m315 : 19|1@1+ (1,0) [0|0] "" Vector__XXX
 SG_ VCLEFT_a316_actuationDurationMs m316 : 19|10@1+ (10,0) [0|0] "" Vector__XXX
 SG_ VCLEFT_a335_SystemError m335 : 19|1@1+ (1,0) [0|0] "" Vector__XXX
 SG_ VCLEFT_a341_stop m341 : 19|1@1+ (1,0) [0|0] "" Vector__XXX
 SG_ VCLEFT_a342_OverTemperature m342 : 19|1@1+ (1,0) [0|0] "" Vector__XXX
 SG_ VCLEFT_a358_liftgateCurrentDropo m358 : 19|10@1+ (1,0) [0|0] "" Vector__XXX
 SG_ VCLEFT_a454_rxErrorFL m454 : 19|4@1+ (1,0) [0|0] "" Vector__XXX
 SG_ VCLEFT_a480_diagnosticBit m480 : 19|1@1+ (1,0) [0|0] "" Vector__XXX
 SG_ VCLEFT_a525_newLVBatteryType m525 : 19|3@1+ (1,0) [0|0] "" Vector__XXX
 SG_ VCLEFT_a545_newLVBatteryType m545 : 19|3@1+ (1,0) [0|0] "" Vector__XXX
 SG_ VCLEFT_a599_newLVBatteryType m599 : 19|3@1+ (1,0) [0|0] "" Vector__XXX
 SG_ VCLEFT_a617_VEH_APP_VC_infoMessa m617 : 19|1@1+ (1,0) [0|0] "" Vector__XXX
 SG_ VCLEFT_a012_SoftwareReset m12 : 18|1@1+ (1,0) [0|0] "" Vector__XXX
 SG_ VCLEFT_a015_NVMMRecordIDError m15 : 18|1@1+ (1,0) [0|0] "" Vector__XXX
 SG_ VCLEFT_a021_Task1msMissed m21 : 18|1@1+ (1,0) [0|0] "" Vector__XXX
 SG_ VCLEFT_a065_index m65 : 18|5@1+ (1,0) [0|0] "" Vector__XXX
 SG_ VCLEFT_a066_index m66 : 18|5@1+ (1,0) [0|0] "" Vector__XXX
 SG_ VCLEFT_a082_RIPC_railStatus m82 : 18|1@1+ (1,0) [0|0] "" Vector__XXX
 SG_ VCLEFT_a083_LIPC_railStatus m83 : 18|1@1+ (1,0) [0|0] "" Vector__XXX
 SG_ VCLEFT_a086_VEH_status m86 : 18|1@1+ (1,0) [0|0] "" Vector__XXX
 SG_ VCLEFT_a087_VEH_torque m87 : 18|1@1+ (1,0) [0|0] "" Vector__XXX
 SG_ VCLEFT_a088_VEH_torque m88 : 18|1@1+ (1,0) [0|0] "" Vector__XXX
 SG_ VCLEFT_a089_VEH_status m89 : 18|1@1+ (1,0) [0|0] "" Vector__XXX
 SG_ VCLEFT_a090_PARTY_eacMonitor m90 : 18|1@1+ (1,0) [0|0] "" Vector__XXX
 SG_ VCLEFT_a091_VEH_state m91 : 18|1@1+ (1,0) [0|0] "" Vector__XXX
 SG_ VCLEFT_a092_VEH_seatStatus2 m92 : 18|1@1+ (1,0) [0|0] "" Vector__XXX
 SG_ VCLEFT_a093_VEH_seatStatus2 m93 : 18|1@1+ (1,0) [0|0] "" Vector__XXX
 SG_ VCLEFT_a098_VEH_status m98 : 18|1@1+ (1,0) [0|0] "" Vector__XXX
 SG_ VCLEFT_a100_PT m100 : 18|1@1+ (1,0) [0|0] "" Vector__XXX
 SG_ VCLEFT_a101_LIPC_externalWatchdo m101 : 18|1@1+ (1,0) [0|0] "" Vector__XXX
 SG_ VCLEFT_a102_VEH_sensorStatus m102 : 18|1@1+ (1,0) [0|0] "" Vector__XXX
 SG_ VCLEFT_a103_VEH_status m103 : 18|1@1+ (1,0) [0|0] "" Vector__XXX
 SG_ VCLEFT_a104_VEH_bodyControls2 m104 : 18|1@1+ (1,0) [0|0] "" Vector__XXX
 SG_ VCLEFT_a105_VEH_dampingStates m105 : 18|1@1+ (1,0) [0|0] "" Vector__XXX
 SG_ VCLEFT_a106_VEH_dcdcRailStatus m106 : 18|1@1+ (1,0) [0|0] "" Vector__XXX
 SG_ VCLEFT_a107_VEH_status m107 : 18|1@1+ (1,0) [0|0] "" Vector__XXX
 SG_ VCLEFT_a108_VEH_thermalControl m108 : 18|1@1+ (1,0) [0|0] "" Vector__XXX
 SG_ VCLEFT_a109_PARTY_nearDeploy m109 : 18|1@1+ (1,0) [0|0] "" Vector__XXX
 SG_ VCLEFT_a110_VEH_time m110 : 18|1@1+ (1,0) [0|0] "" Vector__XXX
 SG_ VCLEFT_a111_VEH_vehNm m111 : 18|1@1+ (1,0) [0|0] "" Vector__XXX
 SG_ VCLEFT_a112_VEH_vehNm m112 : 18|1@1+ (1,0) [0|0] "" Vector__XXX
 SG_ VCLEFT_a113_VEH_chargeRequest m113 : 18|1@1+ (1,0) [0|0] "" Vector__XXX
 SG_ VCLEFT_a114_VEH_wheelSpeeds m114 : 18|1@1+ (1,0) [0|0] "" Vector__XXX
 SG_ VCLEFT_a115_VEH_endpointTemp m115 : 18|1@1+ (1,0) [0|0] "" Vector__XXX
 SG_ VCLEFT_a116_VEH_hvacRequest m116 : 18|1@1+ (1,0) [0|0] "" Vector__XXX
 SG_ VCLEFT_a117_VEH_prndStatus m117 : 18|1@1+ (1,0) [0|0] "" Vector__XXX
 SG_ VCLEFT_a118_VEH_sensors m118 : 18|1@1+ (1,0) [0|0] "" Vector__XXX
 SG_ VCLEFT_a119_VEH_rightStalk m119 : 18|1@1+ (1,0) [0|0] "" Vector__XXX
 SG_ VCLEFT_a120_CH_chassisCntl m120 : 18|1@1+ (1,0) [0|0] "" Vector__XXX
 SG_ VCLEFT_a122_VEH_occupancy m122 : 18|1@1+ (1,0) [0|0] "" Vector__XXX
 SG_ VCLEFT_a129_lockedRotor m129 : 18|1@1+ (1,0) [0|0] "" Vector__XXX
 SG_ VCLEFT_a130_startUpOperation m130 : 18|1@1+ (1,0) [0|0] "" Vector__XXX
 SG_ VCLEFT_a131_chpUnderVoltage m131 : 18|1@1+ (1,0) [0|0] "" Vector__XXX
 SG_ VCLEFT_a136_ibstRodPosition m136 : 18|12@1+ (0.015625,-5) [0|0] "" Vector__XXX
 SG_ VCLEFT_a145_ibstRodPosition m145 : 18|12@1+ (0.015625,-5) [0|0] "" Vector__XXX
 SG_ VCLEFT_a152_speedTableStatus m152 : 18|2@1+ (1,0) [0|0] "" Vector__XXX
 SG_ VCLEFT_a153_speedTableStatus m153 : 18|2@1+ (1,0) [0|0] "" Vector__XXX
 SG_ VCLEFT_a154_lightShowActive m154 : 18|1@1+ (1,0) [0|0] "" Vector__XXX
 SG_ VCLEFT_a155_lightShowActive m155 : 18|1@1+ (1,0) [0|0] "" Vector__XXX
 SG_ VCLEFT_a164_windowRear m164 : 18|1@1+ (1,0) [0|0] "" Vector__XXX
 SG_ VCLEFT_a165_windowRear m165 : 18|1@1+ (1,0) [0|0] "" Vector__XXX
 SG_ VCLEFT_a166_PINCH_V2C m166 : 18|1@1+ (1,0) [0|0] "" Vector__XXX
 SG_ VCLEFT_a173_btnSwPackDownLR m173 : 18|1@1+ (1,0) [0|0] "" Vector__XXX
 SG_ VCLEFT_a183_doorRear m183 : 18|1@1+ (1,0) [0|0] "" Vector__XXX
 SG_ VCLEFT_a192_ecuReset m192 : 18|1@1+ (1,0) [0|0] "" Vector__XXX
 SG_ VCLEFT_a196_lockoutState m196 : 18|1@1+ (1,0) [0|0] "" Vector__XXX
 SG_ VCLEFT_a197_lockoutState m197 : 18|1@1+ (1,0) [0|0] "" Vector__XXX
 SG_ VCLEFT_a202_dynamicAllowed m202 : 18|1@1+ (1,0) [0|0] "" Vector__XXX
 SG_ VCLEFT_a203_dynamicAllowed m203 : 18|1@1+ (1,0) [0|0] "" Vector__XXX
 SG_ VCLEFT_a204_dynamicAllowed m204 : 18|1@1+ (1,0) [0|0] "" Vector__XXX
 SG_ VCLEFT_a205_dynamicAllowed m205 : 18|1@1+ (1,0) [0|0] "" Vector__XXX
 SG_ VCLEFT_a206_dynamicAllowed m206 : 18|1@1+ (1,0) [0|0] "" Vector__XXX
 SG_ VCLEFT_a207_dynamicAllowed m207 : 18|1@1+ (1,0) [0|0] "" Vector__XXX
 SG_ VCLEFT_a208_dynamicAllowed m208 : 18|1@1+ (1,0) [0|0] "" Vector__XXX
 SG_ VCLEFT_a209_dynamicAllowed m209 : 18|1@1+ (1,0) [0|0] "" Vector__XXX
 SG_ VCLEFT_a210_dynamicAllowed m210 : 18|1@1+ (1,0) [0|0] "" Vector__XXX
 SG_ VCLEFT_a211_dynamicAllowed m211 : 18|1@1+ (1,0) [0|0] "" Vector__XXX
 SG_ VCLEFT_a212_dynamicAllowed m212 : 18|1@1+ (1,0) [0|0] "" Vector__XXX
 SG_ VCLEFT_a213_dynamicAllowed m213 : 18|1@1+ (1,0) [0|0] "" Vector__XXX
 SG_ VCLEFT_a214_dynamicAllowed m214 : 18|1@1+ (1,0) [0|0] "" Vector__XXX
 SG_ VCLEFT_a216_CRC_error m216 : 18|1@1+ (1,0) [0|0] "" Vector__XXX
 SG_ VCLEFT_a272_actualState m272 : 18|2@1+ (1,0) [0|0] "" Vector__XXX
 SG_ VCLEFT_a275_tempSenseFaulted m275 : 18|1@1+ (1,0) [0|0] "" Vector__XXX
 SG_ VCLEFT_a285_spiDiagError m285 : 18|1@1+ (1,0) [0|0] "" Vector__XXX
 SG_ VCLEFT_a302_motorOverTemperature m302 : 18|1@1+ (1,0) [0|0] "" Vector__XXX
 SG_ VCLEFT_a311_tempSenseFaulted m311 : 18|1@1+ (1,0) [0|0] "" Vector__XXX
 SG_ VCLEFT_a312_tempSenseFaulted m312 : 18|1@1+ (1,0) [0|0] "" Vector__XXX
 SG_ VCLEFT_a313_tempSenseFaulted m313 : 18|1@1+ (1,0) [0|0] "" Vector__XXX
 SG_ VCLEFT_a314_tempSenseFaulted m314 : 18|1@1+ (1,0) [0|0] "" Vector__XXX
 SG_ VCLEFT_a315_tempSenseFaulted m315 : 18|1@1+ (1,0) [0|0] "" Vector__XXX
 SG_ VCLEFT_a335_LMSelfTestResult m335 : 18|1@1+ (1,0) [0|0] "" Vector__XXX
 SG_ VCLEFT_a341_tail m341 : 18|1@1+ (1,0) [0|0] "" Vector__XXX
 SG_ VCLEFT_a342_5VRailStatus m342 : 18|1@1+ (1,0) [0|0] "" Vector__XXX
 SG_ VCLEFT_a374_rightTurn m374 : 18|2@1+ (1,0) [0|0] "" Vector__XXX
 SG_ VCLEFT_a445_SPIFaultCount m445 : 18|2@1+ (1,0) [0|0] "" Vector__XXX
 SG_ VCLEFT_a480_autoOn m480 : 18|1@1+ (1,0) [0|0] "" Vector__XXX
 SG_ VCLEFT_a499_remoteCdpState m499 : 18|2@1+ (1,0) [0|0] "" Vector__XXX
 SG_ VCLEFT_a526_fastTemperatureRise m526 : 18|1@1+ (1,0) [0|0] "" Vector__XXX
 SG_ VCLEFT_a536_trunkFoldFlatLeftSwi m536 : 18|10@1+ (0.004887585532746823,0) [0|0] "" Vector__XXX
 SG_ VCLEFT_a546_mirrorFoldTypePrevio m546 : 18|2@1+ (1,0) [0|0] "" Vector__XXX
 SG_ VCLEFT_a617_VEH_thermalStatus m617 : 18|1@1+ (1,0) [0|0] "" Vector__XXX
 SG_ VCLEFT_a002_PowerOnReset m2 : 17|1@1+ (1,0) [0|0] "" Vector__XXX
 SG_ VCLEFT_a010_UnderVoltageTimeout m10 : 17|1@1+ (1,0) [0|0] "" Vector__XXX
 SG_ VCLEFT_a012_FlashError m12 : 17|1@1+ (1,0) [0|0] "" Vector__XXX
 SG_ VCLEFT_a013_ClearQueueFull m13 : 17|1@1+ (1,0) [0|0] "" Vector__XXX
 SG_ VCLEFT_a015_NVMMFilesystemError m15 : 17|1@1+ (1,0) [0|0] "" Vector__XXX
 SG_ VCLEFT_a021_Task1msStarved m21 : 17|1@1+ (1,0) [0|0] "" Vector__XXX
 SG_ VCLEFT_a060_resetUnlocked m60 : 17|1@1+ (1,0) [0|0] "" Vector__XXX
 SG_ VCLEFT_a082_RIPC_remoteHSD m82 : 17|1@1+ (1,0) [0|0] "" Vector__XXX
 SG_ VCLEFT_a083_LIPC_remoteHSD m83 : 17|1@1+ (1,0) [0|0] "" Vector__XXX
 SG_ VCLEFT_a086_VEH_LVBMS_statusLow m86 : 17|1@1+ (1,0) [0|0] "" Vector__XXX
 SG_ VCLEFT_a087_VEH_thermalControl m87 : 17|1@1+ (1,0) [0|0] "" Vector__XXX
 SG_ VCLEFT_a088_VEH_thermalControl m88 : 17|1@1+ (1,0) [0|0] "" Vector__XXX
 SG_ VCLEFT_a089_PARTY_status m89 : 17|1@1+ (1,0) [0|0] "" Vector__XXX
 SG_ VCLEFT_a090_VEH_state m90 : 17|1@1+ (1,0) [0|0] "" Vector__XXX
 SG_ VCLEFT_a091_VEH_info m91 : 17|1@1+ (1,0) [0|0] "" Vector__XXX
 SG_ VCLEFT_a092_VEH_switchStatus m92 : 17|1@1+ (1,0) [0|0] "" Vector__XXX
 SG_ VCLEFT_a093_VEH_switchStatus m93 : 17|1@1+ (1,0) [0|0] "" Vector__XXX
 SG_ VCLEFT_a094_PARTY_sysStatus m94 : 17|1@1+ (1,0) [0|0] "" Vector__XXX
 SG_ VCLEFT_a095_PT_status m95 : 17|1@1+ (1,0) [0|0] "" Vector__XXX
 SG_ VCLEFT_a096_CH_status m96 : 17|1@1+ (1,0) [0|0] "" Vector__XXX
 SG_ VCLEFT_a097_VEH_state m97 : 17|1@1+ (1,0) [0|0] "" Vector__XXX
 SG_ VCLEFT_a098_VEH_hvStatus m98 : 17|1@1+ (1,0) [0|0] "" Vector__XXX
 SG_ VCLEFT_a100_PARTY m100 : 17|1@1+ (1,0) [0|0] "" Vector__XXX
 SG_ VCLEFT_a101_PARTY_locState m101 : 17|1@1+ (1,0) [0|0] "" Vector__XXX
 SG_ VCLEFT_a102_VEH_feedbackStatus m102 : 17|1@1+ (1,0) [0|0] "" Vector__XXX
 SG_ VCLEFT_a103_VEH_vehNm m103 : 17|1@1+ (1,0) [0|0] "" Vector__XXX
 SG_ VCLEFT_a104_BDY_redundantBraking m104 : 17|1@1+ (1,0) [0|0] "" Vector__XXX
 SG_ VCLEFT_a105_VEH_chNm m105 : 17|1@1+ (1,0) [0|0] "" Vector__XXX
 SG_ VCLEFT_a106_VEH_thermalControl m106 : 17|1@1+ (1,0) [0|0] "" Vector__XXX
 SG_ VCLEFT_a107_VEH_vehNm m107 : 17|1@1+ (1,0) [0|0] "" Vector__XXX
 SG_ VCLEFT_a108_VEH_temperature m108 : 17|1@1+ (1,0) [0|0] "" Vector__XXX
 SG_ VCLEFT_a109_PARTY_inertial2 m109 : 17|1@1+ (1,0) [0|0] "" Vector__XXX
 SG_ VCLEFT_a110_VEH_carConfig m110 : 17|1@1+ (1,0) [0|0] "" Vector__XXX
 SG_ VCLEFT_a111_VEH_status m111 : 17|1@1+ (1,0) [0|0] "" Vector__XXX
 SG_ VCLEFT_a112_VEH_status m112 : 17|1@1+ (1,0) [0|0] "" Vector__XXX
 SG_ VCLEFT_a113_VEH_hvacRequest m113 : 17|1@1+ (1,0) [0|0] "" Vector__XXX
 SG_ VCLEFT_a114_PARTY_wheelSpeeds m114 : 17|1@1+ (1,0) [0|0] "" Vector__XXX
 SG_ VCLEFT_a115_VEH_authenticationWi m115 : 17|1@1+ (1,0) [0|0] "" Vector__XXX
 SG_ VCLEFT_a116_VEH_vehNm m116 : 17|1@1+ (1,0) [0|0] "" Vector__XXX
 SG_ VCLEFT_a117_BDY_restraintStatus m117 : 17|1@1+ (1,0) [0|0] "" Vector__XXX
 SG_ VCLEFT_a118_VEH_lighting m118 : 17|1@1+ (1,0) [0|0] "" Vector__XXX
 SG_ VCLEFT_a119_VEH_leftStalk m119 : 17|1@1+ (1,0) [0|0] "" Vector__XXX
 SG_ VCLEFT_a120_VEH_systemStatus m120 : 17|1@1+ (1,0) [0|0] "" Vector__XXX
 SG_ VCLEFT_a122_VEH_nonLocalizedOccu m122 : 17|1@1+ (1,0) [0|0] "" Vector__XXX
 SG_ VCLEFT_a129_fetShortCircuit m129 : 17|1@1+ (1,0) [0|0] "" Vector__XXX
 SG_ VCLEFT_a130_junctionOverTemp m130 : 17|1@1+ (1,0) [0|0] "" Vector__XXX
 SG_ VCLEFT_a131_vsOverVoltage m131 : 17|1@1+ (1,0) [0|0] "" Vector__XXX
 SG_ VCLEFT_a152_endStopTrusted m152 : 17|1@1+ (1,0) [0|0] "" Vector__XXX
 SG_ VCLEFT_a153_endStopTrusted m153 : 17|1@1+ (1,0) [0|0] "" Vector__XXX
 SG_ VCLEFT_a164_windowFront m164 : 17|1@1+ (1,0) [0|0] "" Vector__XXX
 SG_ VCLEFT_a165_windowFront m165 : 17|1@1+ (1,0) [0|0] "" Vector__XXX
 SG_ VCLEFT_a166_windowRear m166 : 17|1@1+ (1,0) [0|0] "" Vector__XXX
 SG_ VCLEFT_a173_btnSwPackAutoDownLF m173 : 17|1@1+ (1,0) [0|0] "" Vector__XXX
 SG_ VCLEFT_a183_doorFront m183 : 17|1@1+ (1,0) [0|0] "" Vector__XXX
 SG_ VCLEFT_a192_motorLocked m192 : 17|1@1+ (1,0) [0|0] "" Vector__XXX
 SG_ VCLEFT_a196_NVRAMState m196 : 17|1@1+ (1,0) [0|0] "" Vector__XXX
 SG_ VCLEFT_a197_NVRAMState m197 : 17|1@1+ (1,0) [0|0] "" Vector__XXX
 SG_ VCLEFT_a202_openAllowed m202 : 17|1@1+ (1,0) [0|0] "" Vector__XXX
 SG_ VCLEFT_a203_openAllowed m203 : 17|1@1+ (1,0) [0|0] "" Vector__XXX
 SG_ VCLEFT_a204_openAllowed m204 : 17|1@1+ (1,0) [0|0] "" Vector__XXX
 SG_ VCLEFT_a205_openAllowed m205 : 17|1@1+ (1,0) [0|0] "" Vector__XXX
 SG_ VCLEFT_a206_openAllowed m206 : 17|1@1+ (1,0) [0|0] "" Vector__XXX
 SG_ VCLEFT_a207_openAllowed m207 : 17|1@1+ (1,0) [0|0] "" Vector__XXX
 SG_ VCLEFT_a208_openAllowed m208 : 17|1@1+ (1,0) [0|0] "" Vector__XXX
 SG_ VCLEFT_a209_openAllowed m209 : 17|1@1+ (1,0) [0|0] "" Vector__XXX
 SG_ VCLEFT_a210_openAllowed m210 : 17|1@1+ (1,0) [0|0] "" Vector__XXX
 SG_ VCLEFT_a211_openAllowed m211 : 17|1@1+ (1,0) [0|0] "" Vector__XXX
 SG_ VCLEFT_a212_openAllowed m212 : 17|1@1+ (1,0) [0|0] "" Vector__XXX
 SG_ VCLEFT_a213_openAllowed m213 : 17|1@1+ (1,0) [0|0] "" Vector__XXX
 SG_ VCLEFT_a214_openAllowed m214 : 17|1@1+ (1,0) [0|0] "" Vector__XXX
 SG_ VCLEFT_a216_spiFault m216 : 17|1@1+ (1,0) [0|0] "" Vector__XXX
 SG_ VCLEFT_a224_seatMotorCurrent m224 : 17|12@1- (0.01,0) [0|0] "" Vector__XXX
 SG_ VCLEFT_a225_seatMotorCurrent m225 : 17|12@1- (0.01,0) [0|0] "" Vector__XXX
 SG_ VCLEFT_a226_seatMotorCurrent m226 : 17|12@1- (0.01,0) [0|0] "" Vector__XXX
 SG_ VCLEFT_a227_seatMotorCurrent m227 : 17|12@1- (0.01,0) [0|0] "" Vector__XXX
 SG_ VCLEFT_a228_seatMotorCurrent m228 : 17|12@1- (0.01,0) [0|0] "" Vector__XXX
 SG_ VCLEFT_a229_seatMotorCurrent m229 : 17|12@1- (0.01,0) [0|0] "" Vector__XXX
 SG_ VCLEFT_a230_seatMotorCurrent m230 : 17|12@1- (0.01,0) [0|0] "" Vector__XXX
 SG_ VCLEFT_a231_seatMotorCurrent m231 : 17|12@1- (0.01,0) [0|0] "" Vector__XXX
 SG_ VCLEFT_a275_currentSenseFaulted m275 : 17|1@1+ (1,0) [0|0] "" Vector__XXX
 SG_ VCLEFT_a285_spiRegisterMismatch m285 : 17|1@1+ (1,0) [0|0] "" Vector__XXX
 SG_ VCLEFT_a290_occupancySensorV m290 : 17|12@1- (0.01,0) [0|0] "" Vector__XXX
 SG_ VCLEFT_a292_occupancySensorV m292 : 17|12@1- (0.01,0) [0|0] "" Vector__XXX
 SG_ VCLEFT_a293_occupancySensorV m293 : 17|12@1- (0.01,0) [0|0] "" Vector__XXX
 SG_ VCLEFT_a294_occupancySensorV m294 : 17|12@1- (0.01,0) [0|0] "" Vector__XXX
 SG_ VCLEFT_a302_underVoltage m302 : 17|1@1+ (1,0) [0|0] "" Vector__XXX
 SG_ VCLEFT_a311_currentSenseFaulted m311 : 17|1@1+ (1,0) [0|0] "" Vector__XXX
 SG_ VCLEFT_a312_currentSenseFaulted m312 : 17|1@1+ (1,0) [0|0] "" Vector__XXX
 SG_ VCLEFT_a313_currentSenseFaulted m313 : 17|1@1+ (1,0) [0|0] "" Vector__XXX
 SG_ VCLEFT_a314_currentSenseFaulted m314 : 17|1@1+ (1,0) [0|0] "" Vector__XXX
 SG_ VCLEFT_a315_currentSenseFaulted m315 : 17|1@1+ (1,0) [0|0] "" Vector__XXX
 SG_ VCLEFT_a335_EEPROMSelfTestResult m335 : 17|1@1+ (1,0) [0|0] "" Vector__XXX
 SG_ VCLEFT_a341_rightTurn m341 : 17|1@1+ (1,0) [0|0] "" Vector__XXX
 SG_ VCLEFT_a342_UnderVoltage m342 : 17|1@1+ (1,0) [0|0] "" Vector__XXX
 SG_ VCLEFT_a380_upDownAxis m380 : 17|1@1+ (1,0) [0|0] "" Vector__XXX
 SG_ VCLEFT_a381_pitchEstimateIMU m381 : 17|7@1- (0.001,0) [0|0] "" Vector__XXX
 SG_ VCLEFT_a426_seatMotorCurrent m426 : 17|12@1- (0.01,0) [0|0] "" Vector__XXX
 SG_ VCLEFT_a427_seatMotorCurrent m427 : 17|12@1- (0.01,0) [0|0] "" Vector__XXX
 SG_ VCLEFT_a428_seatMotorCurrent m428 : 17|12@1- (0.01,0) [0|0] "" Vector__XXX
 SG_ VCLEFT_a429_seatMotorCurrent m429 : 17|12@1- (0.01,0) [0|0] "" Vector__XXX
 SG_ VCLEFT_a478_faultCurrent m478 : 17|10@1+ (0.01,0) [0|0] "" Vector__XXX
 SG_ VCLEFT_a480_spiError m480 : 17|1@1+ (1,0) [0|0] "" Vector__XXX
 SG_ VCLEFT_a526_slowTemperatureRise m526 : 17|1@1+ (1,0) [0|0] "" Vector__XXX
 SG_ VCLEFT_a617_BDY_defogInfoMessage m617 : 17|1@1+ (1,0) [0|0] "" Vector__XXX
 SG_ VCLEFT_a000_alertDataW0 m0 : 16|16@1+ (1,0) [0|0] "" Vector__XXX
 SG_ VCLEFT_a001_InternalWatchdog m1 : 16|1@1+ (1,0) [0|0] "" Vector__XXX
 SG_ VCLEFT_a002_CPUUndervoltage m2 : 16|1@1+ (1,0) [0|0] "" Vector__XXX
 SG_ VCLEFT_a003_AssertID m3 : 16|16@1+ (1,0) [0|0] "" Vector__XXX
 SG_ VCLEFT_a005_busID0 m5 : 16|4@1+ (1,0) [0|0] "" Vector__XXX
 SG_ VCLEFT_a006_busID m6 : 16|4@1+ (1,0) [0|0] "" Vector__XXX
 SG_ VCLEFT_a010_UnderVoltageDetected m10 : 16|1@1+ (1,0) [0|0] "" Vector__XXX
 SG_ VCLEFT_a012_ClockError m12 : 16|1@1+ (1,0) [0|0] "" Vector__XXX
 SG_ VCLEFT_a013_LogQueueFull m13 : 16|1@1+ (1,0) [0|0] "" Vector__XXX
 SG_ VCLEFT_a015_NVMMMemOverflow m15 : 16|1@1+ (1,0) [0|0] "" Vector__XXX
 SG_ VCLEFT_a016_NVMMRecordID m16 : 16|16@1+ (1,0) [0|0] "" Vector__XXX
 SG_ VCLEFT_a017_NVMMLifetimeEraseCyc m17 : 16|32@1+ (1,0) [0|0] "" Vector__XXX
 SG_ VCLEFT_a021_Task1msLate m21 : 16|1@1+ (1,0) [0|0] "" Vector__XXX
 SG_ VCLEFT_a022_TaskInitErrorCount m22 : 16|8@1+ (1,0) [0|0] "" Vector__XXX
 SG_ VCLEFT_a030_logId m30 : 16|4@1+ (1,0) [0|0] "" Vector__XXX
 SG_ VCLEFT_a031_uds_bytes_0 m31 : 16|8@1+ (1,0) [0|0] "" Vector__XXX
 SG_ VCLEFT_a041_CPULoadTotal m41 : 16|8@1+ (1,0) [0|0] "" Vector__XXX
 SG_ VCLEFT_a042_Usage1msTask m42 : 16|8@1+ (1,0) [0|0] "" Vector__XXX
 SG_ VCLEFT_a043_CallTrace0 m43 : 16|24@1+ (1,0) [0|0] "" Vector__XXX
 SG_ VCLEFT_a044_CallTrace0 m44 : 16|24@1+ (1,0) [0|0] "" Vector__XXX
 SG_ VCLEFT_a045_CallTrace0 m45 : 16|24@1+ (1,0) [0|0] "" Vector__XXX
 SG_ VCLEFT_a046_CallTrace0 m46 : 16|24@1+ (1,0) [0|0] "" Vector__XXX
 SG_ VCLEFT_a057_VEH_cpControl m57 : 16|1@1+ (1,0) [0|0] "" Vector__XXX
 SG_ VCLEFT_a058_voltageDrop m58 : 16|12@1+ (0.005443676098,0) [0|0] "" Vector__XXX
 SG_ VCLEFT_a059_voltageDrop m59 : 16|12@1+ (0.005443676098,0) [0|0] "" Vector__XXX
 SG_ VCLEFT_a060_lockoutDisabled m60 : 16|1@1+ (1,0) [0|0] "" Vector__XXX
 SG_ VCLEFT_a063_switchChannel m63 : 16|8@1+ (1,0) [0|0] "" Vector__XXX
 SG_ VCLEFT_a064_busBitField m64 : 16|8@1+ (1,0) [0|0] "" Vector__XXX
 SG_ VCLEFT_a065_bank m65 : 16|2@1+ (1,0) [0|0] "" Vector__XXX
 SG_ VCLEFT_a066_bank m66 : 16|2@1+ (1,0) [0|0] "" Vector__XXX
 SG_ VCLEFT_a082_RIPC_epbPrivateState m82 : 16|1@1+ (1,0) [0|0] "" Vector__XXX
 SG_ VCLEFT_a083_LIPC_epbPrivateState m83 : 16|1@1+ (1,0) [0|0] "" Vector__XXX
 SG_ VCLEFT_a084_CH_StatusC m84 : 16|1@1+ (1,0) [0|0] "" Vector__XXX
 SG_ VCLEFT_a085_PARTY_buttonStatus m85 : 16|1@1+ (1,0) [0|0] "" Vector__XXX
 SG_ VCLEFT_a086_VEH_LVBMS_statusHigh m86 : 16|1@1+ (1,0) [0|0] "" Vector__XXX
 SG_ VCLEFT_a087_VEH_temperature m87 : 16|1@1+ (1,0) [0|0] "" Vector__XXX
 SG_ VCLEFT_a088_VEH_temperature m88 : 16|1@1+ (1,0) [0|0] "" Vector__XXX
 SG_ VCLEFT_a089_PARTY_party1 m89 : 16|1@1+ (1,0) [0|0] "" Vector__XXX
 SG_ VCLEFT_a090_VEH_chNm m90 : 16|1@1+ (1,0) [0|0] "" Vector__XXX
 SG_ VCLEFT_a091_VEH_faultsAndExtras m91 : 16|1@1+ (1,0) [0|0] "" Vector__XXX
 SG_ VCLEFT_a092_VEH_restraintStatus m92 : 16|1@1+ (1,0) [0|0] "" Vector__XXX
 SG_ VCLEFT_a093_VEH_restraintStatus m93 : 16|1@1+ (1,0) [0|0] "" Vector__XXX
 SG_ VCLEFT_a094_VEH_sysStatus m94 : 16|1@1+ (1,0) [0|0] "" Vector__XXX
 SG_ VCLEFT_a095_PT_ptNm m95 : 16|1@1+ (1,0) [0|0] "" Vector__XXX
 SG_ VCLEFT_a096_VEH_status m96 : 16|1@1+ (1,0) [0|0] "" Vector__XXX
 SG_ VCLEFT_a097_VEH_HVStatus m97 : 16|1@1+ (1,0) [0|0] "" Vector__XXX
 SG_ VCLEFT_a098_CH_torque m98 : 16|1@1+ (1,0) [0|0] "" Vector__XXX
 SG_ VCLEFT_a099_VEH_oocStatus m99 : 16|1@1+ (1,0) [0|0] "" Vector__XXX
 SG_ VCLEFT_a100_VEH m100 : 16|1@1+ (1,0) [0|0] "" Vector__XXX
 SG_ VCLEFT_a101_VEH_state m101 : 16|1@1+ (1,0) [0|0] "" Vector__XXX
 SG_ VCLEFT_a102_VEH_faultsAndExtras m102 : 16|1@1+ (1,0) [0|0] "" Vector__XXX
 SG_ VCLEFT_a103_VEH_hvsNm m103 : 16|1@1+ (1,0) [0|0] "" Vector__XXX
 SG_ VCLEFT_a104_PARTY_redundantBraki m104 : 16|1@1+ (1,0) [0|0] "" Vector__XXX
 SG_ VCLEFT_a105_VEH_states m105 : 16|1@1+ (1,0) [0|0] "" Vector__XXX
 SG_ VCLEFT_a106_VEH_dcdcStatus m106 : 16|1@1+ (1,0) [0|0] "" Vector__XXX
 SG_ VCLEFT_a107_VEH_hvsNm m107 : 16|1@1+ (1,0) [0|0] "" Vector__XXX
 SG_ VCLEFT_a108_VEH_hvStatus m108 : 16|1@1+ (1,0) [0|0] "" Vector__XXX
 SG_ VCLEFT_a109_PARTY_status m109 : 16|1@1+ (1,0) [0|0] "" Vector__XXX
 SG_ VCLEFT_a110_VEH_carState m110 : 16|1@1+ (1,0) [0|0] "" Vector__XXX
 SG_ VCLEFT_a111_VEH_internalStatus m111 : 16|1@1+ (1,0) [0|0] "" Vector__XXX
 SG_ VCLEFT_a112_VEH_internalStatus m112 : 16|1@1+ (1,0) [0|0] "" Vector__XXX
 SG_ VCLEFT_a113_VEH_ethNm m113 : 16|1@1+ (1,0) [0|0] "" Vector__XXX
 SG_ VCLEFT_a114_PARTY_status m114 : 16|1@1+ (1,0) [0|0] "" Vector__XXX
 SG_ VCLEFT_a115_VEH_RSSI m115 : 16|1@1+ (1,0) [0|0] "" Vector__XXX
 SG_ VCLEFT_a116_PARTY_epbmStatus m116 : 16|1@1+ (1,0) [0|0] "" Vector__XXX
 SG_ VCLEFT_a117_BDY_epbmStatus m117 : 16|1@1+ (1,0) [0|0] "" Vector__XXX
 SG_ VCLEFT_a118_VEH_vehNm m118 : 16|1@1+ (1,0) [0|0] "" Vector__XXX
 SG_ VCLEFT_a119_VEH_steerAngle m119 : 16|1@1+ (1,0) [0|0] "" Vector__XXX
 SG_ VCLEFT_a120_PARTY_chassisCntl m120 : 16|1@1+ (1,0) [0|0] "" Vector__XXX
 SG_ VCLEFT_a122_VEH_status m122 : 16|1@1+ (1,0) [0|0] "" Vector__XXX
 SG_ VCLEFT_a123_OBD_alcoholInterlock m123 : 16|1@1+ (1,0) [0|0] "" Vector__XXX
 SG_ VCLEFT_a129_overCurrentError m129 : 16|1@1+ (1,0) [0|0] "" Vector__XXX
 SG_ VCLEFT_a130_junctionTempWarning m130 : 16|1@1+ (1,0) [0|0] "" Vector__XXX
 SG_ VCLEFT_a131_vsUnderVoltage m131 : 16|1@1+ (1,0) [0|0] "" Vector__XXX
 SG_ VCLEFT_a132_RPMActual m132 : 16|10@1+ (10,0) [0|0] "" Vector__XXX
 SG_ VCLEFT_a133_RPMActual m133 : 16|10@1+ (10,0) [0|0] "" Vector__XXX
 SG_ VCLEFT_a136_brakeSwitch m136 : 16|2@1+ (1,0) [0|0] "" Vector__XXX
 SG_ VCLEFT_a137_VCSECPowerCyclesLeft m137 : 16|8@1+ (1,0) [0|0] "" Vector__XXX
 SG_ VCLEFT_a141_outputCurrent m141 : 16|16@1+ (0.1,0) [0|0] "" Vector__XXX
 SG_ VCLEFT_a145_brakeSwitch m145 : 16|2@1+ (1,0) [0|0] "" Vector__XXX
 SG_ VCLEFT_a150_windowPosition m150 : 16|9@1- (1.4313725490196079,197.52941176470588) [0|0] "" Vector__XXX
 SG_ VCLEFT_a151_windowPosition m151 : 16|9@1- (1.4313725490196079,197.52941176470588) [0|0] "" Vector__XXX
 SG_ VCLEFT_a152_zeroed m152 : 16|1@1+ (1,0) [0|0] "" Vector__XXX
 SG_ VCLEFT_a153_zeroed m153 : 16|1@1+ (1,0) [0|0] "" Vector__XXX
 SG_ VCLEFT_a154_windowThermalMode m154 : 16|2@1+ (1,0) [0|0] "" Vector__XXX
 SG_ VCLEFT_a155_windowThermalMode m155 : 16|2@1+ (1,0) [0|0] "" Vector__XXX
 SG_ VCLEFT_a156_windowThermalMode m156 : 16|2@1+ (1,0) [0|0] "" Vector__XXX
 SG_ VCLEFT_a157_windowThermalMode m157 : 16|2@1+ (1,0) [0|0] "" Vector__XXX
 SG_ VCLEFT_a164_testPassed m164 : 16|1@1+ (1,0) [0|0] "" Vector__XXX
 SG_ VCLEFT_a165_testPassed m165 : 16|1@1+ (1,0) [0|0] "" Vector__XXX
 SG_ VCLEFT_a166_windowFront m166 : 16|1@1+ (1,0) [0|0] "" Vector__XXX
 SG_ VCLEFT_a167_windowPosition m167 : 16|8@1+ (10,0) [0|0] "" Vector__XXX
 SG_ VCLEFT_a168_windowPosition m168 : 16|8@1+ (10,0) [0|0] "" Vector__XXX
 SG_ VCLEFT_a169_currentPeakCurrent m169 : 16|6@1+ (0.1,0) [0|0] "" Vector__XXX
 SG_ VCLEFT_a170_currentPeakCurrent m170 : 16|6@1+ (0.1,0) [0|0] "" Vector__XXX
 SG_ VCLEFT_a173_btnSwPackDownLF m173 : 16|1@1+ (1,0) [0|0] "" Vector__XXX
 SG_ VCLEFT_a175_positionAtPinch m175 : 16|11@1- (0.25,230) [0|0] "" Vector__XXX
 SG_ VCLEFT_a176_positionAtPinch m176 : 16|11@1- (0.25,230) [0|0] "" Vector__XXX
 SG_ VCLEFT_a180_intButtonPressed m180 : 16|1@1+ (1,0) [0|0] "" Vector__XXX
 SG_ VCLEFT_a181_intButtonPressed m181 : 16|1@1+ (1,0) [0|0] "" Vector__XXX
 SG_ VCLEFT_a183_testPassed m183 : 16|1@1+ (1,0) [0|0] "" Vector__XXX
 SG_ VCLEFT_a185_summonFaultReason m185 : 16|5@1+ (1,0) [0|0] "" Vector__XXX
 SG_ VCLEFT_a186_voltage m186 : 16|7@1+ (0.15,0) [0|0] "" Vector__XXX
 SG_ VCLEFT_a187_voltage m187 : 16|7@1+ (0.15,0) [0|0] "" Vector__XXX
 SG_ VCLEFT_a188_voltage m188 : 16|7@1+ (0.15,0) [0|0] "" Vector__XXX
 SG_ VCLEFT_a189_voltage m189 : 16|7@1+ (0.15,0) [0|0] "" Vector__XXX
 SG_ VCLEFT_a190_eFuseTripCount m190 : 16|8@1+ (1,0) [0|0] "" Vector__XXX
 SG_ VCLEFT_a192_motorFaulted m192 : 16|1@1+ (1,0) [0|0] "" Vector__XXX
 SG_ VCLEFT_a196_outputState m196 : 16|1@1+ (1,0) [0|0] "" Vector__XXX
 SG_ VCLEFT_a197_outputState m197 : 16|1@1+ (1,0) [0|0] "" Vector__XXX
 SG_ VCLEFT_a200_voltage m200 : 16|7@1+ (0.15,0) [0|0] "" Vector__XXX
 SG_ VCLEFT_a201_voltage m201 : 16|7@1+ (0.15,0) [0|0] "" Vector__XXX
 SG_ VCLEFT_a202_unknownAllowed m202 : 16|1@1+ (1,0) [0|0] "" Vector__XXX
 SG_ VCLEFT_a203_unknownAllowed m203 : 16|1@1+ (1,0) [0|0] "" Vector__XXX
 SG_ VCLEFT_a204_unknownAllowed m204 : 16|1@1+ (1,0) [0|0] "" Vector__XXX
 SG_ VCLEFT_a205_unknownAllowed m205 : 16|1@1+ (1,0) [0|0] "" Vector__XXX
 SG_ VCLEFT_a206_unknownAllowed m206 : 16|1@1+ (1,0) [0|0] "" Vector__XXX
 SG_ VCLEFT_a207_unknownAllowed m207 : 16|1@1+ (1,0) [0|0] "" Vector__XXX
 SG_ VCLEFT_a208_unknownAllowed m208 : 16|1@1+ (1,0) [0|0] "" Vector__XXX
 SG_ VCLEFT_a209_unknownAllowed m209 : 16|1@1+ (1,0) [0|0] "" Vector__XXX
 SG_ VCLEFT_a210_unknownAllowed m210 : 16|1@1+ (1,0) [0|0] "" Vector__XXX
 SG_ VCLEFT_a211_unknownAllowed m211 : 16|1@1+ (1,0) [0|0] "" Vector__XXX
 SG_ VCLEFT_a212_unknownAllowed m212 : 16|1@1+ (1,0) [0|0] "" Vector__XXX
 SG_ VCLEFT_a213_unknownAllowed m213 : 16|1@1+ (1,0) [0|0] "" Vector__XXX
 SG_ VCLEFT_a214_unknownAllowed m214 : 16|1@1+ (1,0) [0|0] "" Vector__XXX
 SG_ VCLEFT_a215_desyncCount m215 : 16|8@1+ (1,0) [0|0] "" Vector__XXX
 SG_ VCLEFT_a216_noData m216 : 16|1@1+ (1,0) [0|0] "" Vector__XXX
 SG_ VCLEFT_a217_byte4 m217 : 16|8@1+ (1,0) [0|0] "" Vector__XXX
 SG_ VCLEFT_a218_motorChannels m218 : 16|16@1+ (1,0) [0|0] "" Vector__XXX
 SG_ VCLEFT_a219_motorChannels m219 : 16|16@1+ (1,0) [0|0] "" Vector__XXX
 SG_ VCLEFT_a224_seatMotorCalibrated m224 : 16|1@1+ (1,0) [0|0] "" Vector__XXX
 SG_ VCLEFT_a225_seatMotorCalibrated m225 : 16|1@1+ (1,0) [0|0] "" Vector__XXX
 SG_ VCLEFT_a226_seatMotorCalibrated m226 : 16|1@1+ (1,0) [0|0] "" Vector__XXX
 SG_ VCLEFT_a227_seatMotorCalibrated m227 : 16|1@1+ (1,0) [0|0] "" Vector__XXX
 SG_ VCLEFT_a228_seatMotorCalibrated m228 : 16|1@1+ (1,0) [0|0] "" Vector__XXX
 SG_ VCLEFT_a229_seatMotorCalibrated m229 : 16|1@1+ (1,0) [0|0] "" Vector__XXX
 SG_ VCLEFT_a230_seatMotorCalibrated m230 : 16|1@1+ (1,0) [0|0] "" Vector__XXX
 SG_ VCLEFT_a231_seatMotorCalibrated m231 : 16|1@1+ (1,0) [0|0] "" Vector__XXX
 SG_ VCLEFT_a232_seatMotorCurrent m232 : 16|12@1- (0.01,0) [0|0] "" Vector__XXX
 SG_ VCLEFT_a233_seatMotorCurrent m233 : 16|12@1- (0.01,0) [0|0] "" Vector__XXX
 SG_ VCLEFT_a234_seatMotorCurrent m234 : 16|12@1- (0.01,0) [0|0] "" Vector__XXX
 SG_ VCLEFT_a235_seatMotorCurrent m235 : 16|12@1- (0.01,0) [0|0] "" Vector__XXX
 SG_ VCLEFT_a236_lumbarAPressureHpa m236 : 16|16@1+ (1,0) [0|0] "" Vector__XXX
 SG_ VCLEFT_a237_lumbarAPressureHpa m237 : 16|16@1+ (1,0) [0|0] "" Vector__XXX
 SG_ VCLEFT_a238_lumbarAPressureHpa m238 : 16|16@1+ (1,0) [0|0] "" Vector__XXX
 SG_ VCLEFT_a239_seatHeatCurrent m239 : 16|12@1+ (0.01,0) [0|0] "" Vector__XXX
 SG_ VCLEFT_a240_seatHeatCurrent m240 : 16|12@1+ (0.01,0) [0|0] "" Vector__XXX
 SG_ VCLEFT_a241_seatHeatCurrent m241 : 16|12@1+ (0.01,0) [0|0] "" Vector__XXX
 SG_ VCLEFT_a242_seatHeatCurrent m242 : 16|12@1+ (0.01,0) [0|0] "" Vector__XXX
 SG_ VCLEFT_a243_seatHeatCurrent m243 : 16|12@1+ (0.01,0) [0|0] "" Vector__XXX
 SG_ VCLEFT_a244_seatHeatCurrent m244 : 16|12@1+ (0.01,0) [0|0] "" Vector__XXX
 SG_ VCLEFT_a245_seatHeatCurrent m245 : 16|12@1+ (0.01,0) [0|0] "" Vector__XXX
 SG_ VCLEFT_a246_seatHeatCurrent m246 : 16|12@1+ (0.01,0) [0|0] "" Vector__XXX
 SG_ VCLEFT_a247_seatHeatCurrent m247 : 16|12@1+ (0.01,0) [0|0] "" Vector__XXX
 SG_ VCLEFT_a248_seatHeatCurrent m248 : 16|12@1+ (0.01,0) [0|0] "" Vector__XXX
 SG_ VCLEFT_a249_seatHeatCurrent m249 : 16|12@1+ (0.01,0) [0|0] "" Vector__XXX
 SG_ VCLEFT_a250_seatHeatCurrent m250 : 16|12@1+ (0.01,0) [0|0] "" Vector__XXX
 SG_ VCLEFT_a251_seatMotorCurrent m251 : 16|12@1- (0.01,0) [0|0] "" Vector__XXX
 SG_ VCLEFT_a252_seatMotorCurrent m252 : 16|12@1- (0.01,0) [0|0] "" Vector__XXX
 SG_ VCLEFT_a253_seatMotorCurrent m253 : 16|12@1- (0.01,0) [0|0] "" Vector__XXX
 SG_ VCLEFT_a254_seatMotorCurrent m254 : 16|12@1- (0.01,0) [0|0] "" Vector__XXX
 SG_ VCLEFT_a259_disarmDelay m259 : 16|7@1+ (10,0) [0|0] "" Vector__XXX
 SG_ VCLEFT_a260_disarmDelay m260 : 16|7@1+ (10,0) [0|0] "" Vector__XXX
 SG_ VCLEFT_a263_seatMotorCurrent m263 : 16|12@1- (0.01,0) [0|0] "" Vector__XXX
 SG_ VCLEFT_a264_seatMotorCurrent m264 : 16|12@1- (0.01,0) [0|0] "" Vector__XXX
 SG_ VCLEFT_a265_seatMotorCurrent m265 : 16|12@1- (0.01,0) [0|0] "" Vector__XXX
 SG_ VCLEFT_a266_seatMotorCurrent m266 : 16|12@1- (0.01,0) [0|0] "" Vector__XXX
 SG_ VCLEFT_a267_seatMotorCurrent m267 : 16|12@1- (0.01,0) [0|0] "" Vector__XXX
 SG_ VCLEFT_a268_seatMotorCurrent m268 : 16|12@1- (0.01,0) [0|0] "" Vector__XXX
 SG_ VCLEFT_a269_seatMotorCurrent m269 : 16|12@1- (0.01,0) [0|0] "" Vector__XXX
 SG_ VCLEFT_a270_seatMotorCurrent m270 : 16|12@1- (0.01,0) [0|0] "" Vector__XXX
 SG_ VCLEFT_a272_expectedState m272 : 16|2@1+ (1,0) [0|0] "" Vector__XXX
 SG_ VCLEFT_a273_handlePWM m273 : 16|7@1+ (1,0) [0|0] "" Vector__XXX
 SG_ VCLEFT_a274_handlePWM m274 : 16|7@1+ (1,0) [0|0] "" Vector__XXX
 SG_ VCLEFT_a275_outputFaulted m275 : 16|1@1+ (1,0) [0|0] "" Vector__XXX
 SG_ VCLEFT_a276_mirrorDebugType m276 : 16|3@1+ (1,0) [0|0] "" Vector__XXX
 SG_ VCLEFT_a277_voltageInmV m277 : 16|16@1+ (1,0) [0|0] "" Vector__XXX
 SG_ VCLEFT_a278_voltageInmV m278 : 16|16@1+ (1,0) [0|0] "" Vector__XXX
 SG_ VCLEFT_a279_voltage m279 : 16|12@1- (0.01,0) [0|0] "" Vector__XXX
 SG_ VCLEFT_a282_voltage m282 : 16|7@1+ (0.15,0) [0|0] "" Vector__XXX
 SG_ VCLEFT_a283_voltage m283 : 16|7@1+ (0.15,0) [0|0] "" Vector__XXX
 SG_ VCLEFT_a284_RPMActual m284 : 16|10@1+ (10,0) [0|0] "" Vector__XXX
 SG_ VCLEFT_a285_spiErrorCount m285 : 16|1@1+ (1,0) [0|0] "" Vector__XXX
 SG_ VCLEFT_a286_windowSpeed m286 : 16|8@1- (100,0) [0|0] "" Vector__XXX
 SG_ VCLEFT_a287_windowSpeed m287 : 16|8@1- (100,0) [0|0] "" Vector__XXX
 SG_ VCLEFT_a288_period m288 : 16|8@1+ (0.05,0) [0|0] "" Vector__XXX
 SG_ VCLEFT_a289_period m289 : 16|8@1+ (0.05,0) [0|0] "" Vector__XXX
 SG_ VCLEFT_a290_isNetworkSwitch m290 : 16|1@1+ (1,0) [0|0] "" Vector__XXX
 SG_ VCLEFT_a291_buckleSensorVoltage m291 : 16|12@1+ (0.01,0) [0|0] "" Vector__XXX
 SG_ VCLEFT_a292_isNetworkSwitch m292 : 16|1@1+ (1,0) [0|0] "" Vector__XXX
 SG_ VCLEFT_a293_isNetworkSwitch m293 : 16|1@1+ (1,0) [0|0] "" Vector__XXX
 SG_ VCLEFT_a294_isNetworkSwitch m294 : 16|1@1+ (1,0) [0|0] "" Vector__XXX
 SG_ VCLEFT_a295_buckleSensorVoltage m295 : 16|12@1- (0.01,0) [0|0] "" Vector__XXX
 SG_ VCLEFT_a296_buckleSensorVoltage m296 : 16|12@1- (0.01,0) [0|0] "" Vector__XXX
 SG_ VCLEFT_a297_cabinTmp m297 : 16|12@1- (0.1,0) [0|0] "" Vector__XXX
 SG_ VCLEFT_a302_overVoltage m302 : 16|1@1+ (1,0) [0|0] "" Vector__XXX
 SG_ VCLEFT_a303_eFuseTripCount m303 : 16|8@1+ (1,0) [0|0] "" Vector__XXX
 SG_ VCLEFT_a304_handleADCmV m304 : 16|8@1+ (20,0) [0|0] "" Vector__XXX
 SG_ VCLEFT_a305_handleADCmV m305 : 16|8@1+ (20,0) [0|0] "" Vector__XXX
 SG_ VCLEFT_a306_disconnectedTime m306 : 16|10@1+ (1,0) [0|0] "" Vector__XXX
 SG_ VCLEFT_a307_disconnectedTime m307 : 16|10@1+ (1,0) [0|0] "" Vector__XXX
 SG_ VCLEFT_a308_tamperDetected m308 : 16|1@1+ (1,0) [0|0] "" Vector__XXX
 SG_ VCLEFT_a309_5VMainVoltage m309 : 16|12@1- (0.01,0) [0|0] "" Vector__XXX
 SG_ VCLEFT_a310_mirrorFoldTime m310 : 16|9@1+ (10,0) [0|0] "" Vector__XXX
 SG_ VCLEFT_a311_outputFaulted m311 : 16|1@1+ (1,0) [0|0] "" Vector__XXX
 SG_ VCLEFT_a312_outputFaulted m312 : 16|1@1+ (1,0) [0|0] "" Vector__XXX
 SG_ VCLEFT_a313_outputFaulted m313 : 16|1@1+ (1,0) [0|0] "" Vector__XXX
 SG_ VCLEFT_a314_outputFaulted m314 : 16|1@1+ (1,0) [0|0] "" Vector__XXX
 SG_ VCLEFT_a315_outputFaulted m315 : 16|1@1+ (1,0) [0|0] "" Vector__XXX
 SG_ VCLEFT_a316_foldState m316 : 16|3@1+ (1,0) [0|0] "" Vector__XXX
 SG_ VCLEFT_a318_configExpected m318 : 16|2@1+ (1,0) [0|0] "" Vector__XXX
 SG_ VCLEFT_a321_deltaPrevZero m321 : 16|16@1- (1,0) [0|0] "" Vector__XXX
 SG_ VCLEFT_a322_deltaPrevZero m322 : 16|16@1- (1,0) [0|0] "" Vector__XXX
 SG_ VCLEFT_a323_calibrationLeft m323 : 16|12@1+ (0.002,0) [0|0] "" Vector__XXX
 SG_ VCLEFT_a324_mirrorHeatCurrent m324 : 16|10@1+ (0.01,0) [0|0] "" Vector__XXX
 SG_ VCLEFT_a325_PWMdutyCycleFL m325 : 16|16@1+ (0.0025,0) [0|0] "" Vector__XXX
 SG_ VCLEFT_a326_PWMdutyCycleRL m326 : 16|16@1+ (0.0025,0) [0|0] "" Vector__XXX
 SG_ VCLEFT_a327_PWMdutyCycleFL m327 : 16|16@1+ (0.0025,0) [0|0] "" Vector__XXX
 SG_ VCLEFT_a328_PWMdutyCycleRL m328 : 16|16@1+ (0.0025,0) [0|0] "" Vector__XXX
 SG_ VCLEFT_a330_voltage m330 : 16|7@1+ (0.15,0) [0|0] "" Vector__XXX
 SG_ VCLEFT_a331_voltage m331 : 16|7@1+ (0.15,0) [0|0] "" Vector__XXX
 SG_ VCLEFT_a334_OHCDiagnosticMask m334 : 16|32@1+ (1,0) [0|0] "" Vector__XXX
 SG_ VCLEFT_a335_USSSelfTestResult m335 : 16|1@1+ (1,0) [0|0] "" Vector__XXX
 SG_ VCLEFT_a341_leftTurn m341 : 16|1@1+ (1,0) [0|0] "" Vector__XXX
 SG_ VCLEFT_a342_OverVoltage m342 : 16|1@1+ (1,0) [0|0] "" Vector__XXX
 SG_ VCLEFT_a345_secondsSinceWakeUp m345 : 16|32@1+ (0.001,0) [0|0] "" Vector__XXX
 SG_ VCLEFT_a346_eFuseTripCount m346 : 16|8@1+ (1,0) [0|0] "" Vector__XXX
 SG_ VCLEFT_a348_current m348 : 16|16@1+ (0.001,0) [0|0] "" Vector__XXX
 SG_ VCLEFT_a349_voltage m349 : 16|16@1+ (0.1,0) [0|0] "" Vector__XXX
 SG_ VCLEFT_a350_ensPeriod m350 : 16|16@1+ (0.0001,0) [0|0] "" Vector__XXX
 SG_ VCLEFT_a351_liftgateStrutCu_0000 m351 : 16|10@1- (0.3913894324853229,0) [0|0] "" Vector__XXX
 SG_ VCLEFT_a352_liftgatePosition m352 : 16|7@1- (1,43) [0|0] "" Vector__XXX
 SG_ VCLEFT_a353_eFuseTripCount m353 : 16|8@1+ (1,0) [0|0] "" Vector__XXX
 SG_ VCLEFT_a354_eFuseTripCount m354 : 16|8@1+ (1,0) [0|0] "" Vector__XXX
 SG_ VCLEFT_a355_liftgateStoppingCond m355 : 16|4@1+ (1,0) [0|0] "" Vector__XXX
 SG_ VCLEFT_a356_liftgatePositionMaxO m356 : 16|10@1- (0.1,42.5) [0|0] "" Vector__XXX
 SG_ VCLEFT_a357_liftgateState m357 : 16|4@1+ (1,0) [0|0] "" Vector__XXX
 SG_ VCLEFT_a358_liftgateSimpleState m358 : 16|3@1+ (1,0) [0|0] "" Vector__XXX
 SG_ VCLEFT_a360_vehicleSpeed m360 : 16|8@1- (1,80) [0|0] "" Vector__XXX
 SG_ VCLEFT_a361_accelVar m361 : 16|15@1+ (0.0001,0) [0|0] "" Vector__XXX
 SG_ VCLEFT_a362_accelVar m362 : 16|20@1+ (1e-06,0) [0|0] "" Vector__XXX
 SG_ VCLEFT_a363_newOpenSetpoint m363 : 16|7@1- (1,50) [0|0] "" Vector__XXX
 SG_ VCLEFT_a373_windowChannel m373 : 16|2@1+ (1,0) [0|0] "" Vector__XXX
 SG_ VCLEFT_a374_leftTurn m374 : 16|2@1+ (1,0) [0|0] "" Vector__XXX
 SG_ VCLEFT_a375_windowFront m375 : 16|1@1+ (1,0) [0|0] "" Vector__XXX
 SG_ VCLEFT_a376_2RowSeatTrackAc_0000 m376 : 16|12@1- (0.01,0) [0|0] "" Vector__XXX
 SG_ VCLEFT_a380_inOutAxis m380 : 16|1@1+ (1,0) [0|0] "" Vector__XXX
 SG_ VCLEFT_a381_rideHeightSensorInst m381 : 16|1@1+ (1,0) [0|0] "" Vector__XXX
 SG_ VCLEFT_a382_elevationDelta m382 : 16|13@1- (1,0) [0|0] "" Vector__XXX
 SG_ VCLEFT_a383_currentPositionMM m383 : 16|16@1- (0.01,0) [0|0] "" Vector__XXX
 SG_ VCLEFT_a384_currentPositionMM m384 : 16|16@1- (0.01,0) [0|0] "" Vector__XXX
 SG_ VCLEFT_a385_currentPositionMM m385 : 16|16@1- (0.01,0) [0|0] "" Vector__XXX
 SG_ VCLEFT_a386_currentPositionMM m386 : 16|16@1- (0.01,0) [0|0] "" Vector__XXX
 SG_ VCLEFT_a387_currentPositionMM m387 : 16|16@1- (0.01,0) [0|0] "" Vector__XXX
 SG_ VCLEFT_a388_currentPositionMM m388 : 16|16@1- (0.01,0) [0|0] "" Vector__XXX
 SG_ VCLEFT_a389_currentPositionMM m389 : 16|16@1- (0.01,0) [0|0] "" Vector__XXX
 SG_ VCLEFT_a390_currentPositionMM m390 : 16|16@1- (0.01,0) [0|0] "" Vector__XXX
 SG_ VCLEFT_a391_averageSpeed m391 : 16|6@1+ (10,-100) [0|0] "" Vector__XXX
 SG_ VCLEFT_a392_startingLocationAccu m392 : 16|6@1+ (0.2,0) [0|0] "" Vector__XXX
 SG_ VCLEFT_a393_distanceTraveled m393 : 16|10@1+ (0.5,0) [0|0] "" Vector__XXX
 SG_ VCLEFT_a426_seatMotorCalibrated m426 : 16|1@1+ (1,0) [0|0] "" Vector__XXX
 SG_ VCLEFT_a427_seatMotorCalibrated m427 : 16|1@1+ (1,0) [0|0] "" Vector__XXX
 SG_ VCLEFT_a428_seatMotorCalibrated m428 : 16|1@1+ (1,0) [0|0] "" Vector__XXX
 SG_ VCLEFT_a429_seatMotorCalibrated m429 : 16|1@1+ (1,0) [0|0] "" Vector__XXX
 SG_ VCLEFT_a444_retriesAvailable m444 : 16|8@1+ (1,0) [0|0] "" Vector__XXX
 SG_ VCLEFT_a445_checksFailedCount m445 : 16|2@1+ (1,0) [0|0] "" Vector__XXX
 SG_ VCLEFT_a446_vbatProt m446 : 16|16@1+ (0.01,0) [0|0] "" Vector__XXX
 SG_ VCLEFT_a447_endstopPositionMM m447 : 16|16@1- (0.01,0) [0|0] "" Vector__XXX
 SG_ VCLEFT_a448_endstopPositionMM m448 : 16|16@1- (0.01,0) [0|0] "" Vector__XXX
 SG_ VCLEFT_a453_liftgatePosition m453 : 16|7@1- (1,43) [0|0] "" Vector__XXX
 SG_ VCLEFT_a454_txErrorFL m454 : 16|3@1+ (1,0) [0|0] "" Vector__XXX
 SG_ VCLEFT_a455_liftgateState m455 : 16|4@1+ (1,0) [0|0] "" Vector__XXX
 SG_ VCLEFT_a478_faultType m478 : 16|1@1+ (1,0) [0|0] "" Vector__XXX
 SG_ VCLEFT_a480_reset m480 : 16|1@1+ (1,0) [0|0] "" Vector__XXX
 SG_ VCLEFT_a481_channel m481 : 16|8@1+ (1,0) [0|0] "" Vector__XXX
 SG_ VCLEFT_a482_channel m482 : 16|6@1+ (1,0) [0|0] "" Vector__XXX
 SG_ VCLEFT_a493_12vSocketFrontEFuseC m493 : 16|9@1+ (0.1,0) [0|0] "" Vector__XXX
 SG_ VCLEFT_a494_12vSocketRearEFuseCu m494 : 16|9@1+ (0.1,0) [0|0] "" Vector__XXX
 SG_ VCLEFT_a499_localCdpState m499 : 16|2@1+ (1,0) [0|0] "" Vector__XXX
 SG_ VCLEFT_a500_channel m500 : 16|8@1+ (1,0) [0|0] "" Vector__XXX
 SG_ VCLEFT_a501_channel m501 : 16|8@1+ (1,0) [0|0] "" Vector__XXX
 SG_ VCLEFT_a520_epbConfig m520 : 16|4@1+ (1,0) [0|0] "" Vector__XXX
 SG_ VCLEFT_a521_voltage m521 : 16|8@1+ (0.1,0) [0|0] "" Vector__XXX
 SG_ VCLEFT_a522_voltage m522 : 16|8@1+ (0.1,0) [0|0] "" Vector__XXX
 SG_ VCLEFT_a523_channel m523 : 16|8@1+ (1,0) [0|0] "" Vector__XXX
 SG_ VCLEFT_a525_GTW_twelveVBatteryTy m525 : 16|3@1+ (1,0) [0|0] "" Vector__XXX
 SG_ VCLEFT_a526_aboveAbsMaxTemp m526 : 16|1@1+ (1,0) [0|0] "" Vector__XXX
 SG_ VCLEFT_a527_voltage m527 : 16|8@1+ (0.1,0) [0|0] "" Vector__XXX
 SG_ VCLEFT_a536_trunkFoldFlatSwitchS m536 : 16|2@1+ (1,0) [0|0] "" Vector__XXX
 SG_ VCLEFT_a545_GTW_twelveVBatteryTy m545 : 16|3@1+ (1,0) [0|0] "" Vector__XXX
 SG_ VCLEFT_a546_mirrorFoldTypePresen m546 : 16|2@1+ (1,0) [0|0] "" Vector__XXX
 SG_ VCLEFT_a550_ambientTemperature m550 : 16|16@1- (0.125,55) [0|0] "" Vector__XXX
 SG_ VCLEFT_a551_restrictDoorRel_0000 m551 : 16|1@1+ (1,0) [0|0] "" Vector__XXX
 SG_ VCLEFT_a570_seatHeatCurrent m570 : 16|12@1+ (0.01,0) [0|0] "" Vector__XXX
 SG_ VCLEFT_a571_seatHeatCurrent m571 : 16|12@1+ (0.01,0) [0|0] "" Vector__XXX
 SG_ VCLEFT_a572_seatHeatCurrent m572 : 16|12@1+ (0.01,0) [0|0] "" Vector__XXX
 SG_ VCLEFT_a573_seatHeatCurrent m573 : 16|12@1+ (0.01,0) [0|0] "" Vector__XXX
 SG_ VCLEFT_a583_ambientTemp m583 : 16|8@1+ (0.5,-40) [0|0] "" Vector__XXX
 SG_ VCLEFT_a584_ambientTemp m584 : 16|8@1+ (0.5,-40) [0|0] "" Vector__XXX
 SG_ VCLEFT_a585_ambientTemp m585 : 16|8@1+ (0.5,-40) [0|0] "" Vector__XXX
 SG_ VCLEFT_a586_ambientTemp m586 : 16|8@1+ (0.5,-40) [0|0] "" Vector__XXX
 SG_ VCLEFT_a599_GTW_twelveVBatteryTy m599 : 16|3@1+ (1,0) [0|0] "" Vector__XXX
 SG_ VCLEFT_a617_VEH_VC_infoMessage m617 : 16|1@1+ (1,0) [0|0] "" Vector__XXX
 SG_ VCLEFT_alertState : 15|1@1+ (1,0) [0|0] "" Vector__XXX
 SG_ VCLEFT_alertID M : 0|10@1+ (1,0) [0|0] "" Vector__XXX

BO_ 1377 VCBATT_bootID: 12 Vector__XXX
 SG_ VCBATT_bootFirmwareType : 63|8@0+ (1,0) [0|0] "" Vector__XXX
 SG_ VCBATT_bootUsageId : 39|16@0+ (1,0) [0|0] "" Vector__XXX
 SG_ VCBATT_bootAssemblyId : 31|8@0+ (1,0) [0|0] "" Vector__XXX
 SG_ VCBATT_bootPcbaId : 23|8@0+ (1,0) [0|0] "" Vector__XXX
 SG_ VCBATT_bootComponentId : 7|16@0+ (1,0) [0|0] "" Vector__XXX

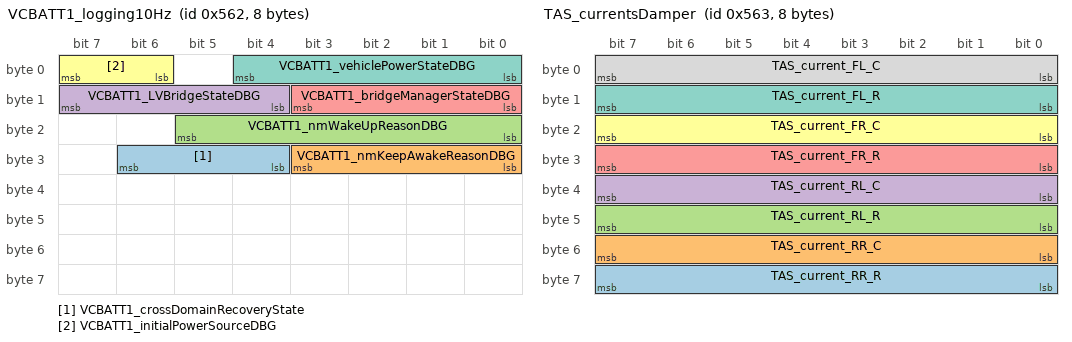
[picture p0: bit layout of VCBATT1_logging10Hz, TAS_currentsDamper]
BO_ 1378 VCBATT1_logging10Hz: 8 Vector__XXX
 SG_ VCBATT1_crossDomainRecoveryState : 28|3@1+ (1,0) [0|0] "" Vector__XXX
 SG_ VCBATT1_nmKeepAwakeReasonDBG : 24|4@1+ (1,0) [0|0] "" Vector__XXX
 SG_ VCBATT1_nmWakeUpReasonDBG : 16|6@1+ (1,0) [0|0] "" Vector__XXX
 SG_ VCBATT1_LVBridgeStateDBG : 12|4@1+ (1,0) [0|0] "" Vector__XXX
 SG_ VCBATT1_bridgeManagerStateDBG : 8|4@1+ (1,0) [0|0] "" Vector__XXX
 SG_ VCBATT1_initialPowerSourceDBG : 6|2@1+ (1,0) [0|0] "" Vector__XXX
 SG_ VCBATT1_vehiclePowerStateDBG : 0|5@1+ (1,0) [0|0] "" Vector__XXX

BO_ 1379 TAS_currentsDamper: 8 Vector__XXX
 SG_ TAS_current_RR_R : 56|8@1+ (0.01,0) [0|0] "" Vector__XXX
 SG_ TAS_current_RR_C : 48|8@1+ (0.01,0) [0|0] "" Vector__XXX
 SG_ TAS_current_RL_R : 40|8@1+ (0.01,0) [0|0] "" Vector__XXX
 SG_ TAS_current_RL_C : 32|8@1+ (0.01,0) [0|0] "" Vector__XXX
 SG_ TAS_current_FR_R : 24|8@1+ (0.01,0) [0|0] "" Vector__XXX
 SG_ TAS_current_FR_C : 16|8@1+ (0.01,0) [0|0] "" Vector__XXX
 SG_ TAS_current_FL_R : 8|8@1+ (0.01,0) [0|0] "" Vector__XXX
 SG_ TAS_current_FL_C : 0|8@1+ (0.01,0) [0|0] "" Vector__XXX

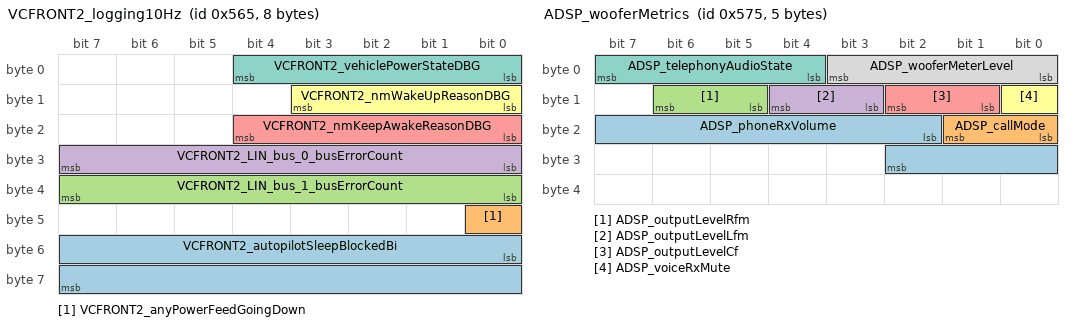
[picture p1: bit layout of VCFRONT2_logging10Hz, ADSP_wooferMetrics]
BO_ 1381 VCFRONT2_logging10Hz: 8 Vector__XXX
 SG_ VCFRONT2_autopilotSleepBlockedBi : 48|16@1+ (1,0) [0|0] "" Vector__XXX
 SG_ VCFRONT2_anyPowerFeedGoingDown : 40|1@1+ (1,0) [0|0] "" Vector__XXX
 SG_ VCFRONT2_LIN_bus_1_busErrorCount : 32|8@1+ (1,0) [0|0] "" Vector__XXX
 SG_ VCFRONT2_LIN_bus_0_busErrorCount : 24|8@1+ (1,0) [0|0] "" Vector__XXX
 SG_ VCFRONT2_nmKeepAwakeReasonDBG : 16|5@1+ (1,0) [0|0] "" Vector__XXX
 SG_ VCFRONT2_nmWakeUpReasonDBG : 8|4@1+ (1,0) [0|0] "" Vector__XXX
 SG_ VCFRONT2_vehiclePowerStateDBG : 0|5@1+ (1,0) [0|0] "" Vector__XXX

BO_ 1383 ADSP_state: 8 Vector__XXX
 SG_ ADSP_microphoneDataState : 60|1@1+ (1,0) [0|0] "" Vector__XXX
 SG_ ADSP_requestFailoverSpeaker : 59|1@1+ (1,0) [0|0] "" Vector__XXX
 SG_ ADSP_a2baLoadShedded : 58|1@1+ (1,0) [0|0] "" Vector__XXX
 SG_ ADSP_eCallSpeakerStatus : 56|2@1+ (1,0) [0|0] "" Vector__XXX
 SG_ ADSP_eCallMicrophoneStatus : 53|2@1+ (1,0) [0|0] "" Vector__XXX
 SG_ ADSP_telephonyTxMute : 52|1@1+ (1,0) [0|0] "" Vector__XXX
 SG_ ADSP_callState : 51|1@1+ (1,0) [0|0] "" Vector__XXX
 SG_ ADSP_allAudioReady : 50|1@1+ (1,0) [0|0] "" Vector__XXX
 SG_ ADSP_eCallState : 49|1@1+ (1,0) [0|0] "" Vector__XXX
 SG_ ADSP_eCallSelfTest : 47|2@1+ (1,0) [0|0] "" Vector__XXX
 SG_ ADSP_eCall_ENS_state : 44|3@1+ (1,0) [0|0] "" Vector__XXX
 SG_ ADSP_spkMuteAll : 43|1@1+ (1,0) [0|0] "" Vector__XXX
 SG_ ADSP_ancMode : 38|5@1+ (1,0) [0|0] "" Vector__XXX
 SG_ ADSP_tunerSelect : 37|1@1+ (1,0) [0|0] "" Vector__XXX
 SG_ ADSP_sourceSelect : 35|2@1+ (1,0) [0|0] "" Vector__XXX
 SG_ ADSP_ancState : 32|3@1+ (1,0) [0|0] "" Vector__XXX
 SG_ ADSP_telephonyRxMute : 31|1@1+ (1,0) [0|0] "" Vector__XXX
 SG_ ADSP_tcuI2SEnabled : 28|1@1+ (1,0) [0|0] "" Vector__XXX
 SG_ ADSP_audioReady : 27|1@1+ (1,0) [0|0] "" Vector__XXX
 SG_ ADSP_baseamp3State : 24|3@1+ (1,0) [0|0] "" Vector__XXX
 SG_ ADSP_baseamp2State : 19|3@1+ (1,0) [0|0] "" Vector__XXX
 SG_ ADSP_baseamp1State : 16|3@1+ (1,0) [0|0] "" Vector__XXX
 SG_ ADSP_baseamp0State : 13|3@1+ (1,0) [0|0] "" Vector__XXX
 SG_ ADSP_a2bbState : 8|5@1+ (1,0) [0|0] "" Vector__XXX
 SG_ ADSP_a2baState : 0|5@1+ (1,0) [0|0] "" Vector__XXX

BO_ 1397 ADSP_wooferMetrics: 5 Vector__XXX
 SG_ ADSP_phoneRxVolume : 18|9@1- (1,0) [0|0] "" Vector__XXX
 SG_ ADSP_callMode : 16|2@1+ (1,0) [0|0] "" Vector__XXX
 SG_ ADSP_outputLevelRfm : 13|2@1+ (1,0) [0|0] "" Vector__XXX
 SG_ ADSP_outputLevelLfm : 11|2@1+ (1,0) [0|0] "" Vector__XXX
 SG_ ADSP_outputLevelCf : 9|2@1+ (1,0) [0|0] "" Vector__XXX
 SG_ ADSP_voiceRxMute : 8|1@1+ (1,0) [0|0] "" Vector__XXX
 SG_ ADSP_telephonyAudioState : 4|4@1+ (1,0) [0|0] "" Vector__XXX
 SG_ ADSP_wooferMeterLevel : 0|4@1+ (10,-100) [0|0] "" Vector__XXX

BO_ 1398 TAS_dampingStates: 8 Vector__XXX
 SG_ TAS_dampingStatesChecksum : 56|8@1+ (1,0) [0|0] "" Vector__XXX
 SG_ TAS_dampingStatesCounter : 52|4@1+ (1,0) [0|0] "" Vector__XXX
 SG_ TAS_anyDamperActive : 51|1@1+ (1,0) [0|0] "" Vector__XXX
 SG_ TAS_sprungMassEstimate : 46|5@1+ (64,1800) [0|0] "" Vector__XXX
 SG_ TAS_FDUTorqueCorruptionScale : 42|4@1+ (0.075,0) [0|0] "" Vector__XXX
 SG_ TAS_stepProtectRR : 40|2@1+ (1,0) [0|0] "" Vector__XXX
 SG_ TAS_stepProtectRL : 38|2@1+ (1,0) [0|0] "" Vector__XXX
 SG_ TAS_stepProtectFR : 36|2@1+ (1,0) [0|0] "" Vector__XXX
 SG_ TAS_stepProtectFL : 34|2@1+ (1,0) [0|0] "" Vector__XXX
 SG_ TAS_holeProtectRR : 32|2@1+ (1,0) [0|0] "" Vector__XXX
 SG_ TAS_holeProtectRL : 30|2@1+ (1,0) [0|0] "" Vector__XXX
 SG_ TAS_holeProtectFR : 28|2@1+ (1,0) [0|0] "" Vector__XXX
 SG_ TAS_holeProtectFL : 26|2@1+ (1,0) [0|0] "" Vector__XXX
 SG_ TAS_speedBumpAxleRear : 23|3@1+ (1,0) [0|0] "" Vector__XXX
 SG_ TAS_speedBumpAxleFront : 20|3@1+ (1,0) [0|0] "" Vector__XXX
 SG_ TAS_frontMetricDrivesFront : 18|2@1+ (1,0) [0|0] "" Vector__XXX
 SG_ TAS_bellyProtect : 16|2@1+ (1,0) [0|0] "" Vector__XXX
 SG_ TAS_roadCondition : 8|8@1+ (0.005,0) [0|0] "" Vector__XXX
 SG_ TAS_frontMetricDrivesRear : 5|2@1+ (1,0) [0|0] "" Vector__XXX
 SG_ TAS_roughnessRaiseReason : 3|2@1+ (1,0) [0|0] "" Vector__XXX
 SG_ TAS_activeTireTune : 2|1@1+ (1,0) [0|0] "" Vector__XXX
 SG_ TAS_continuousControlState : 1|1@1+ (1,0) [0|0] "" Vector__XXX
 SG_ TAS_endstopState : 0|1@1+ (1,0) [0|0] "" Vector__XXX

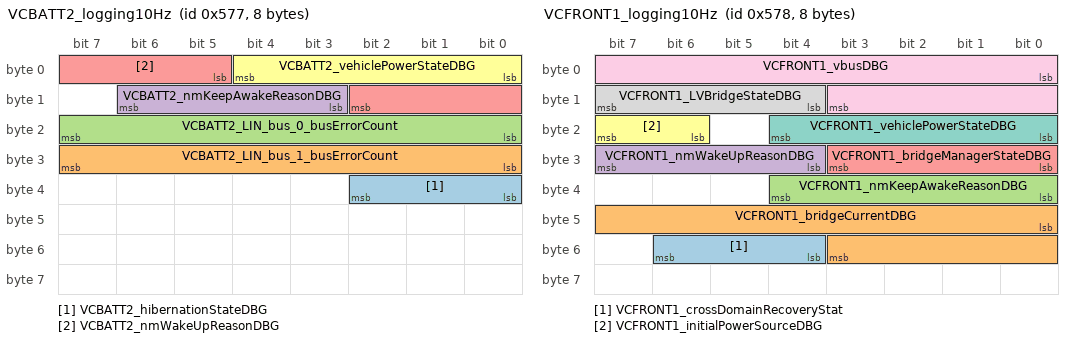
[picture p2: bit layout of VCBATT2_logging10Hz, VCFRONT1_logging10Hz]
BO_ 1399 VCBATT2_logging10Hz: 8 Vector__XXX
 SG_ VCBATT2_hibernationStateDBG : 32|3@1+ (1,0) [0|0] "" Vector__XXX
 SG_ VCBATT2_LIN_bus_1_busErrorCount : 24|8@1+ (1,0) [0|0] "" Vector__XXX
 SG_ VCBATT2_LIN_bus_0_busErrorCount : 16|8@1+ (1,0) [0|0] "" Vector__XXX
 SG_ VCBATT2_nmKeepAwakeReasonDBG : 11|4@1+ (1,0) [0|0] "" Vector__XXX
 SG_ VCBATT2_nmWakeUpReasonDBG : 5|6@1+ (1,0) [0|0] "" Vector__XXX
 SG_ VCBATT2_vehiclePowerStateDBG : 0|5@1+ (1,0) [0|0] "" Vector__XXX

BO_ 1400 VCFRONT1_logging10Hz: 8 Vector__XXX
 SG_ VCFRONT1_crossDomainRecoveryStat : 52|3@1+ (1,0) [0|0] "" Vector__XXX
 SG_ VCFRONT1_bridgeCurrentDBG : 40|12@1- (0.1,0) [0|0] "" Vector__XXX
 SG_ VCFRONT1_nmKeepAwakeReasonDBG : 32|5@1+ (1,0) [0|0] "" Vector__XXX
 SG_ VCFRONT1_nmWakeUpReasonDBG : 28|4@1+ (1,0) [0|0] "" Vector__XXX
 SG_ VCFRONT1_bridgeManagerStateDBG : 24|4@1+ (1,0) [0|0] "" Vector__XXX
 SG_ VCFRONT1_initialPowerSourceDBG : 22|2@1+ (1,0) [0|0] "" Vector__XXX
 SG_ VCFRONT1_vehiclePowerStateDBG : 16|5@1+ (1,0) [0|0] "" Vector__XXX
 SG_ VCFRONT1_LVBridgeStateDBG : 12|4@1+ (1,0) [0|0] "" Vector__XXX
 SG_ VCFRONT1_vbusDBG : 0|12@1+ (0.005443676098,0) [0|0] "" Vector__XXX

BO_ 1405 SDCR_status: 8 Vector__XXX
 SG_ SDCR_ascFeedbackPin : 25|1@1+ (1,0) [0|0] "" Vector__XXX
 SG_ SDCR_diCanMIA : 24|1@1+ (1,0) [0|0] "" Vector__XXX
 SG_ SDCR_diUartMIA : 23|1@1+ (1,0) [0|0] "" Vector__XXX
 SG_ SDCR_currentOffsetAssessed : 22|1@1+ (1,0) [0|0] "" Vector__XXX
 SG_ SDCR_atSpeedFromPhaseV : 21|1@1+ (1,0) [0|0] "" Vector__XXX
 SG_ SDCR_faultCurrentsDetected : 20|1@1+ (1,0) [0|0] "" Vector__XXX
 SG_ SDCR_activeDischargeCtrl : 19|1@1+ (1,0) [0|0] "" Vector__XXX
 SG_ SDCR_vbkupPGoodPin : 18|1@1+ (1,0) [0|0] "" Vector__XXX
 SG_ SDCR_diSafeState : 16|2@1+ (1,0) [0|0] "" Vector__XXX
 SG_ SDCR_diSwitchingPin : 14|1@1+ (1,0) [0|0] "" Vector__XXX
 SG_ SDCR_pmRunningPin : 13|1@1+ (1,0) [0|0] "" Vector__XXX
 SG_ SDCR_diSoptRunning : 12|1@1+ (1,0) [0|0] "" Vector__XXX
 SG_ SDCR_diPstComplete : 11|1@1+ (1,0) [0|0] "" Vector__XXX
 SG_ SDCR_diPstRunning : 10|1@1+ (1,0) [0|0] "" Vector__XXX
 SG_ SDCR_ecuLogState : 8|2@1+ (1,0) [0|0] "" Vector__XXX
 SG_ SDCR_hvfmState : 5|3@1+ (1,0) [0|0] "" Vector__XXX
 SG_ SDCR_pyroState : 3|2@1+ (1,0) [0|0] "" Vector__XXX
 SG_ SDCR_pstState : 0|3@1+ (1,0) [0|0] "" Vector__XXX

BO_ 1425 EPAS3S_alertLog: 8 Vector__XXX
 SG_ EPAS3S_a151_dcsCBootB m151 : 63|1@1+ (1,0) [0|0] "" Vector__XXX
 SG_ EPAS3S_a151_dcsCBootA m151 : 62|1@1+ (1,0) [0|0] "" Vector__XXX
 SG_ EPAS3S_a084_eacCancelCode m84 : 60|4@1+ (1,0) [0|0] "" Vector__XXX
 SG_ EPAS3S_a152_dcsVbusDiagPathErrReg m152 : 57|7@1+ (1,0) [0|0] "" Vector__XXX
 SG_ EPAS3S_a163_powerStatus m163 : 55|1@1+ (1,0) [0|0] "" Vector__XXX
 SG_ EPAS3S_a163_diagStatus m163 : 54|1@1+ (1,0) [0|0] "" Vector__XXX
 SG_ EPAS3S_a150_otherECUAssistStatusFlag m150 : 54|1@1+ (1,0) [0|0] "" Vector__XXX
 SG_ EPAS3S_a161_pcoMaxPhaseACurrent m161 : 52|12@1- (0.1025,0) [0|0] "" Vector__XXX
 SG_ EPAS3S_a151_dcsOffsetB m151 : 52|10@1- (1,0) [0|0] "" Vector__XXX
 SG_ EPAS3S_a137_motorVelocity m137 : 50|10@1- (0.9765625,0) [0|0] "" Vector__XXX
 SG_ EPAS3S_a136_motorVelocity m136 : 50|10@1- (0.9765625,0) [0|0] "" Vector__XXX
 SG_ EPAS3S_a135_motorVelocity m135 : 50|10@1- (0.9765625,0) [0|0] "" Vector__XXX
 SG_ EPAS3S_a134_motorVelocity m134 : 49|10@1- (0.9765625,0) [0|0] "" Vector__XXX
 SG_ EPAS3S_a133_motorVelocity m133 : 49|10@1- (0.9765625,0) [0|0] "" Vector__XXX
 SG_ EPAS3S_a132_motorVelocity m132 : 49|10@1- (0.9765625,0) [0|0] "" Vector__XXX
 SG_ EPAS3S_a084_eacCancelAngle m84 : 48|12@1+ (1,-2048) [0|0] "" Vector__XXX
 SG_ EPAS3S_a152_dcsErrSumReg m152 : 47|10@1+ (1,0) [0|0] "" Vector__XXX
 SG_ EPAS3S_a163_gateDrvrDiag0Reg m163 : 45|9@1+ (1,0) [0|0] "" Vector__XXX
 SG_ EPAS3S_a151_dcsOffsetA m151 : 42|10@1- (1,0) [0|0] "" Vector__XXX
 SG_ EPAS3S_a152_dcsTubErrReg m152 : 41|6@1+ (1,0) [0|0] "" Vector__XXX
 SG_ EPAS3S_a137_iqMeasured m137 : 41|9@1- (0.78125,0) [0|0] "" Vector__XXX
 SG_ EPAS3S_a136_iqMeasured m136 : 41|9@1- (0.78125,0) [0|0] "" Vector__XXX
 SG_ EPAS3S_a135_iqMeasured m135 : 41|9@1- (0.78125,0) [0|0] "" Vector__XXX
 SG_ EPAS3S_a161_pcoMinPhaseACurrent m161 : 40|12@1- (0.1025,0) [0|0] "" Vector__XXX
 SG_ EPAS3S_a134_iqMeasured m134 : 40|9@1- (0.78125,0) [0|0] "" Vector__XXX
 SG_ EPAS3S_a133_iqMeasured m133 : 40|9@1- (0.78125,0) [0|0] "" Vector__XXX
 SG_ EPAS3S_a132_iqMeasured m132 : 40|9@1- (0.78125,0) [0|0] "" Vector__XXX
 SG_ EPAS3S_a150_phaVMainPathCalcDiff m150 : 39|15@1+ (1,0) [0|0] "" Vector__XXX
 SG_ EPAS3S_a163_gateDrvrDiag1Reg m163 : 36|9@1+ (1,0) [0|0] "" Vector__XXX
 SG_ EPAS3S_a084_eacCancelAngleGrad m84 : 36|12@1+ (1,-2048) [0|0] "" Vector__XXX
 SG_ EPAS3S_a160_gateDrvrInitTest m160 : 34|2@1+ (1,0) [0|0] "" Vector__XXX
 SG_ EPAS3S_a137_idMeasured m137 : 33|8@1+ (0.787,0) [0|0] "" Vector__XXX
 SG_ EPAS3S_a136_idMeasured m136 : 33|8@1+ (0.787,0) [0|0] "" Vector__XXX
 SG_ EPAS3S_a135_idMeasured m135 : 33|8@1+ (0.787,0) [0|0] "" Vector__XXX
 SG_ EPAS3S_a164_currentSensorRailed m164 : 32|1@1+ (1,0) [0|0] "" Vector__XXX
 SG_ EPAS3S_a162_vBridgeOpen m162 : 32|16@1+ (0.00537,0) [0|0] "" Vector__XXX
 SG_ EPAS3S_a160_invFetInitTest m160 : 32|2@1+ (1,0) [0|0] "" Vector__XXX
 SG_ EPAS3S_a151_dcsMainChannelB m151 : 32|10@1- (0.41,0) [0|0] "" Vector__XXX
 SG_ EPAS3S_a134_idMeasured m134 : 32|8@1+ (0.787,0) [0|0] "" Vector__XXX
 SG_ EPAS3S_a133_idMeasured m133 : 32|8@1+ (0.787,0) [0|0] "" Vector__XXX
 SG_ EPAS3S_a132_idMeasured m132 : 32|8@1+ (0.787,0) [0|0] "" Vector__XXX
 SG_ EPAS3S_a160_phaDisconnFailShortTest m160 : 30|2@1+ (1,0) [0|0] "" Vector__XXX
 SG_ EPAS3S_a152_dcsMainPathErrReg m152 : 30|11@1+ (1,0) [0|0] "" Vector__XXX
 SG_ EPAS3S_a161_pcoMaxPhaseBCurrent m161 : 28|12@1- (0.1025,0) [0|0] "" Vector__XXX
 SG_ EPAS3S_a160_phaDisconnFailOpenTest m160 : 28|2@1+ (1,0) [0|0] "" Vector__XXX
 SG_ EPAS3S_a163_gateDrvrDiag2Reg m163 : 27|9@1+ (1,0) [0|0] "" Vector__XXX
 SG_ EPAS3S_a160_hsdFetFailShortTest m160 : 26|2@1+ (1,0) [0|0] "" Vector__XXX
 SG_ EPAS3S_a153_dcsOffsetB m153 : 26|10@1- (1,0) [0|0] "" Vector__XXX
 SG_ EPAS3S_a084_eacCancelTtrq m84 : 26|10@1+ (0.05,-25) [0|0] "" Vector__XXX
 SG_ EPAS3S_a160_inverterFetStatus m160 : 24|2@1+ (1,0) [0|0] "" Vector__XXX
 SG_ EPAS3S_a150_phaUMainPathCalcDiff m150 : 24|15@1+ (1,0) [0|0] "" Vector__XXX
 SG_ EPAS3S_a137_iqReference m137 : 24|9@1- (0.78125,0) [0|0] "" Vector__XXX
 SG_ EPAS3S_a136_iqReference m136 : 24|9@1- (0.78125,0) [0|0] "" Vector__XXX
 SG_ EPAS3S_a135_iqReference m135 : 24|9@1- (0.78125,0) [0|0] "" Vector__XXX
 SG_ EPAS3S_a134_motorTorqueInverse m134 : 24|8@1- (0.0787,0) [0|0] "" Vector__XXX
 SG_ EPAS3S_a133_motorTorqueInverse m133 : 24|8@1- (0.0787,0) [0|0] "" Vector__XXX
 SG_ EPAS3S_a132_motorTorqueInverse m132 : 24|8@1- (0.0787,0) [0|0] "" Vector__XXX
 SG_ EPAS3S_a152_dcsModIndex m152 : 23|7@1+ (1,0) [0|0] "" Vector__XXX
 SG_ EPAS3S_a160_phaseDisconnectFetStatus m160 : 22|2@1+ (1,0) [0|0] "" Vector__XXX
 SG_ EPAS3S_a151_dcsMainChannelA m151 : 22|10@1- (0.41,0) [0|0] "" Vector__XXX
 SG_ EPAS3S_a160_highSideDisconnectFetStatus m160 : 20|2@1+ (1,0) [0|0] "" Vector__XXX
 SG_ EPAS3S_a160_gateDriverStatus m160 : 18|2@1+ (1,0) [0|0] "" Vector__XXX
 SG_ EPAS3S_a164_dcsRegister0x19 m164 : 16|16@1+ (1,0) [0|0] "" Vector__XXX
 SG_ EPAS3S_a163_gateDrvrStatusReg m163 : 16|11@1+ (1,0) [0|0] "" Vector__XXX
 SG_ EPAS3S_a162_vBridgeClosed m162 : 16|16@1+ (0.00537,0) [0|0] "" Vector__XXX
 SG_ EPAS3S_a161_pcoMinPhaseBCurrent m161 : 16|12@1- (0.1025,0) [0|0] "" Vector__XXX
 SG_ EPAS3S_a160_currentSensorStatus m160 : 16|2@1+ (1,0) [0|0] "" Vector__XXX
 SG_ EPAS3S_a156_vehicleSpeed m156 : 16|10@1+ (0.5,0) [0|0] "" Vector__XXX
 SG_ EPAS3S_a155_vehicleSpeed m155 : 16|10@1+ (0.5,0) [0|0] "" Vector__XXX
 SG_ EPAS3S_a154_vehicleSpeed m154 : 16|10@1+ (0.5,0) [0|0] "" Vector__XXX
 SG_ EPAS3S_a153_dcsOffsetA m153 : 16|10@1- (1,0) [0|0] "" Vector__XXX
 SG_ EPAS3S_a152_dcsVBridge m152 : 16|6@1+ (0.328,0) [0|0] "" Vector__XXX
 SG_ EPAS3S_a151_dcsVBridge m151 : 16|6@1+ (0.328,0) [0|0] "" Vector__XXX
 SG_ EPAS3S_a150_pcbTemp m150 : 16|8@1- (1,60) [0|0] "" Vector__XXX
 SG_ EPAS3S_a149_pcbTemp m149 : 16|8@1- (1,60) [0|0] "" Vector__XXX
 SG_ EPAS3S_a148_vehicleSpeed m148 : 16|10@1+ (0.5,0) [0|0] "" Vector__XXX
 SG_ EPAS3S_a147_transitionReason m147 : 16|2@1+ (1,0) [0|0] "" Vector__XXX
 SG_ EPAS3S_a137_motorTorqueCommand m137 : 16|8@1- (0.0787,0) [0|0] "" Vector__XXX
 SG_ EPAS3S_a136_motorTorqueCommand m136 : 16|8@1- (0.0787,0) [0|0] "" Vector__XXX
 SG_ EPAS3S_a135_motorTorqueCommand m135 : 16|8@1- (0.0787,0) [0|0] "" Vector__XXX
 SG_ EPAS3S_a134_motorTorqueCommand m134 : 16|8@1- (0.0787,0) [0|0] "" Vector__XXX
 SG_ EPAS3S_a133_motorTorqueCommand m133 : 16|8@1- (0.0787,0) [0|0] "" Vector__XXX
 SG_ EPAS3S_a132_motorTorqueCommand m132 : 16|8@1- (0.0787,0) [0|0] "" Vector__XXX
 SG_ EPAS3S_a084_eacCancelMtrq m84 : 16|10@1+ (0.01,0) [0|0] "" Vector__XXX
 SG_ EPAS3S_alertState : 15|1@1+ (1,0) [0|0] "" Vector__XXX
 SG_ EPAS3S_alertID M : 0|8@1+ (1,0) [0|0] "" Vector__XXX

BO_ 1429 OCS1P_alertLog: 8 Vector__XXX
 SG_ OCS1P_a145_humidity m145 : 56|8@1+ (1,0) [0|0] "" Vector__XXX
 SG_ OCS1P_a000_alertDataW2 m0 : 48|16@1+ (1,0) [0|0] "" Vector__XXX
 SG_ OCS1P_a145_temperature m145 : 48|8@1+ (1,-40) [0|0] "" Vector__XXX
 SG_ OCS1P_a148_filtRBClass m148 : 43|3@1+ (1,0) [0|0] "" Vector__XXX
 SG_ OCS1P_a148_filtCapClass m148 : 40|3@1+ (1,0) [0|0] "" Vector__XXX
 SG_ OCS1P_a151_seatbackSelfMin m151 : 40|16@1+ (0.005,0) [0|0] "" Vector__XXX
 SG_ OCS1P_a154_seatbackSelfMin m154 : 40|16@1+ (0.005,0) [0|0] "" Vector__XXX
 SG_ OCS1P_a148_filtFreqClass m148 : 35|3@1+ (1,0) [0|0] "" Vector__XXX
 SG_ OCS1P_a000_alertDataW1 m0 : 32|16@1+ (1,0) [0|0] "" Vector__XXX
 SG_ OCS1P_a145_seatbackSelfOffset m145 : 32|16@1- (0.0025,0) [0|0] "" Vector__XXX
 SG_ OCS1P_a148_rawRBClass m148 : 32|3@1+ (1,0) [0|0] "" Vector__XXX
 SG_ OCS1P_a150_seatbackSelfBaseline m150 : 32|16@1+ (0.005,0) [0|0] "" Vector__XXX
 SG_ OCS1P_a152_seatbackSelfPreExit m152 : 32|16@1+ (0.005,0) [0|0] "" Vector__XXX
 SG_ OCS1P_a155_seatbackSelfBaseline m155 : 32|16@1+ (0.005,0) [0|0] "" Vector__XXX
 SG_ OCS1P_a148_rawCapClass m148 : 27|3@1+ (1,0) [0|0] "" Vector__XXX
 SG_ OCS1P_a148_rawFreqClass m148 : 24|3@1+ (1,0) [0|0] "" Vector__XXX
 SG_ OCS1P_a151_cushionSelfMin m151 : 24|16@1+ (0.005,0) [0|0] "" Vector__XXX
 SG_ OCS1P_a154_cushionSelfMin m154 : 24|16@1+ (0.005,0) [0|0] "" Vector__XXX
 SG_ OCS1P_a015_NVMMWriteFailed m15 : 21|1@1+ (1,0) [0|0] "" Vector__XXX
 SG_ OCS1P_a148_filtRBVsCap m148 : 21|1@1+ (1,0) [0|0] "" Vector__XXX
 SG_ OCS1P_a015_NVMMMemOverflow m15 : 20|1@1+ (1,0) [0|0] "" Vector__XXX
 SG_ OCS1P_a148_filtRBVsFreq m148 : 20|1@1+ (1,0) [0|0] "" Vector__XXX
 SG_ OCS1P_a015_NVMMRecordUpgraded m15 : 19|1@1+ (1,0) [0|0] "" Vector__XXX
 SG_ OCS1P_a148_filtCapVsFreq m148 : 19|1@1+ (1,0) [0|0] "" Vector__XXX
 SG_ OCS1P_a015_NVMMVersionMismatch m15 : 18|1@1+ (1,0) [0|0] "" Vector__XXX
 SG_ OCS1P_a148_rawRBVsCap m148 : 18|1@1+ (1,0) [0|0] "" Vector__XXX
 SG_ OCS1P_a015_NVMMCRCMismatch m15 : 17|1@1+ (1,0) [0|0] "" Vector__XXX
 SG_ OCS1P_a148_rawRBVsFreq m148 : 17|1@1+ (1,0) [0|0] "" Vector__XXX
 SG_ OCS1P_a000_alertDataW0 m0 : 16|16@1+ (1,0) [0|0] "" Vector__XXX
 SG_ OCS1P_a015_NVMMRecordNotFound m15 : 16|1@1+ (1,0) [0|0] "" Vector__XXX
 SG_ OCS1P_a121_sandwichFreq m121 : 16|32@1+ (1,0) [0|0] "" Vector__XXX
 SG_ OCS1P_a122_sandwichFreq m122 : 16|32@1+ (1,0) [0|0] "" Vector__XXX
 SG_ OCS1P_a123_sandwichFreq m123 : 16|32@1+ (1,0) [0|0] "" Vector__XXX
 SG_ OCS1P_a124_cushionSelfFreq m124 : 16|32@1+ (1,0) [0|0] "" Vector__XXX
 SG_ OCS1P_a125_cushionSelfFreq m125 : 16|32@1+ (1,0) [0|0] "" Vector__XXX
 SG_ OCS1P_a126_cushionSelfFreq m126 : 16|32@1+ (1,0) [0|0] "" Vector__XXX
 SG_ OCS1P_a127_seatbackSelfFreq m127 : 16|32@1+ (1,0) [0|0] "" Vector__XXX
 SG_ OCS1P_a128_seatbackSelfFreq m128 : 16|32@1+ (1,0) [0|0] "" Vector__XXX
 SG_ OCS1P_a129_seatbackSelfFreq m129 : 16|32@1+ (1,0) [0|0] "" Vector__XXX
 SG_ OCS1P_a130_sandwichNoCalib m130 : 16|1@1+ (1,0) [0|0] "" Vector__XXX
 SG_ OCS1P_a131_cushionSelfNoCalib m131 : 16|1@1+ (1,0) [0|0] "" Vector__XXX
 SG_ OCS1P_a132_seatbackSelfNoCalib m132 : 16|1@1+ (1,0) [0|0] "" Vector__XXX
 SG_ OCS1P_a133_sandwichBadCalib m133 : 16|1@1+ (1,0) [0|0] "" Vector__XXX
 SG_ OCS1P_a134_uninitializedCalib m134 : 16|1@1+ (1,0) [0|0] "" Vector__XXX
 SG_ OCS1P_a135_tempNoCalib m135 : 16|1@1+ (1,0) [0|0] "" Vector__XXX
 SG_ OCS1P_a136_cushionSelfDuty m136 : 16|32@1+ (1,0) [0|0] "" Vector__XXX
 SG_ OCS1P_a137_cushionSelfDuty m137 : 16|32@1+ (1,0) [0|0] "" Vector__XXX
 SG_ OCS1P_a138_seatbackSelfDuty m138 : 16|32@1+ (1,0) [0|0] "" Vector__XXX
 SG_ OCS1P_a139_seatbackSelfDuty m139 : 16|32@1+ (1,0) [0|0] "" Vector__XXX
 SG_ OCS1P_a140_tempInvalidCalib m140 : 16|1@1+ (1,0) [0|0] "" Vector__XXX
 SG_ OCS1P_a141_humidityInvalidCalib m141 : 16|1@1+ (1,0) [0|0] "" Vector__XXX
 SG_ OCS1P_a142_tempHumidityInvalid m142 : 16|1@1+ (1,0) [0|0] "" Vector__XXX
 SG_ OCS1P_a143_mismatchPassAirbag m143 : 16|1@1+ (1,0) [0|0] "" Vector__XXX
 SG_ OCS1P_a144_mismatchCarRegion m144 : 16|1@1+ (1,0) [0|0] "" Vector__XXX
 SG_ OCS1P_a145_cushionSelfOffset m145 : 16|16@1- (0.005,0) [0|0] "" Vector__XXX
 SG_ OCS1P_a148_rawCapVsFreq m148 : 16|1@1+ (1,0) [0|0] "" Vector__XXX
 SG_ OCS1P_a150_cushionSelfBaseline m150 : 16|16@1+ (0.005,0) [0|0] "" Vector__XXX
 SG_ OCS1P_a151_reason m151 : 16|3@1+ (1,0) [0|0] "" Vector__XXX
 SG_ OCS1P_a152_cushionSelfPreExit m152 : 16|16@1+ (0.005,0) [0|0] "" Vector__XXX
 SG_ OCS1P_a153_reason m153 : 16|3@1+ (1,0) [0|0] "" Vector__XXX
 SG_ OCS1P_a154_reason m154 : 16|3@1+ (1,0) [0|0] "" Vector__XXX
 SG_ OCS1P_a155_cushionSelfBaseline m155 : 16|16@1+ (0.005,0) [0|0] "" Vector__XXX
 SG_ OCS1P_alertState : 15|1@1+ (1,0) [0|0] "" Vector__XXX
 SG_ OCS1P_alertID M : 0|8@1+ (1,0) [0|0] "" Vector__XXX

BO_ 1442 VCBATT1_logging0point1Hz: 8 Vector__XXX
 SG_ VCBATT1_LVBatteryVoltOffsetAvgDe m2 : 58|6@1+ (0.002,0) [0|0] "" Vector__XXX
 SG_ VCBATT1_autopilot1VoltOffsetAvgD m3 : 58|6@1+ (0.002,0) [0|0] "" Vector__XXX
 SG_ VCBATT1_brakeMotor1VoltOffsetAvg m4 : 58|6@1+ (0.002,0) [0|0] "" Vector__XXX
 SG_ VCBATT1_brakeValve1VoltOffsetAvg m5 : 58|6@1+ (0.002,0) [0|0] "" Vector__XXX
 SG_ VCBATT1_epas1VoltOffsetAvgDeviat m6 : 58|6@1+ (0.002,0) [0|0] "" Vector__XXX
 SG_ VCBATT_highCurrentSilentWakeCoun m0 : 54|10@1+ (1,0) [0|0] "" Vector__XXX
 SG_ VCBATT1_LVBatteryCurrAvgDeviatio m2 : 52|6@1+ (0.05,0) [0|0] "" Vector__XXX
 SG_ VCBATT1_autopilot1CurrAvgDeviati m3 : 52|6@1+ (0.05,0) [0|0] "" Vector__XXX
 SG_ VCBATT1_brakeMotor1CurrAvgDeviat m4 : 52|6@1+ (0.05,0) [0|0] "" Vector__XXX
 SG_ VCBATT1_brakeValve1CurrAvgDeviat m5 : 52|6@1+ (0.05,0) [0|0] "" Vector__XXX
 SG_ VCBATT1_epas1CurrAvgDeviation m6 : 52|6@1+ (0.05,0) [0|0] "" Vector__XXX
 SG_ VCBATT_silentWakeLVBMSCurrent m1 : 50|14@1+ (0.125,-2047.875) [0|0] "" Vector__XXX
 SG_ VCBATT1_LVBatteryResistanceAcc m2 : 47|5@1+ (0.0005,0) [0|0] "" Vector__XXX
 SG_ VCBATT1_autopilot1ResistanceAcc m3 : 47|5@1+ (0.0005,0) [0|0] "" Vector__XXX
 SG_ VCBATT1_brakeMotor1ResistanceAcc m4 : 47|5@1+ (0.0005,0) [0|0] "" Vector__XXX
 SG_ VCBATT1_brakeValve1ResistanceAcc m5 : 47|5@1+ (0.0005,0) [0|0] "" Vector__XXX
 SG_ VCBATT1_epas1ResistanceAcc m6 : 47|5@1+ (0.0005,0) [0|0] "" Vector__XXX
 SG_ VCBATT1_LVBatteryResistanceAccRa m2 : 42|5@1+ (0.0005,0) [0|0] "" Vector__XXX
 SG_ VCBATT1_autopilot1ResistanceAccR m3 : 42|5@1+ (0.0005,0) [0|0] "" Vector__XXX
 SG_ VCBATT1_brakeMotor1Resistan_0000 m4 : 42|5@1+ (0.0005,0) [0|0] "" Vector__XXX
 SG_ VCBATT1_brakeValve1Resistan_0000 m5 : 42|5@1+ (0.0005,0) [0|0] "" Vector__XXX
 SG_ VCBATT1_epas1ResistanceAccRaw m6 : 42|5@1+ (0.0005,0) [0|0] "" Vector__XXX
 SG_ VCBATT1_LVBatteryVoltOffsetValid m2 : 41|1@1+ (1,0) [0|0] "" Vector__XXX
 SG_ VCBATT1_autopilot1VoltOffsetVali m3 : 41|1@1+ (1,0) [0|0] "" Vector__XXX
 SG_ VCBATT1_brakeMotor1VoltOffsetVal m4 : 41|1@1+ (1,0) [0|0] "" Vector__XXX
 SG_ VCBATT1_brakeValve1VoltOffsetVal m5 : 41|1@1+ (1,0) [0|0] "" Vector__XXX
 SG_ VCBATT1_epas1VoltOffsetValid m6 : 41|1@1+ (1,0) [0|0] "" Vector__XXX
 SG_ VCBATT_silentWakeLVBMSHeaterCurr m0 : 40|14@1+ (0.125,-2047.875) [0|0] "" Vector__XXX
 SG_ VCBATT_silentWakeIBSCurrent m1 : 36|14@1+ (0.125,-2047.875) [0|0] "" Vector__XXX
 SG_ VCBATT1_LVBatteryVoltOffsetCal m2 : 32|9@1- (0.004,0) [0|0] "" Vector__XXX
 SG_ VCBATT1_autopilot1VoltOffsetCal m3 : 32|9@1- (0.004,0) [0|0] "" Vector__XXX
 SG_ VCBATT1_brakeMotor1VoltOffsetCal m4 : 32|9@1- (0.004,0) [0|0] "" Vector__XXX
 SG_ VCBATT1_brakeValve1VoltOffsetCal m5 : 32|9@1- (0.004,0) [0|0] "" Vector__XXX
 SG_ VCBATT1_epas1VoltOffsetCal m6 : 32|9@1- (0.004,0) [0|0] "" Vector__XXX
 SG_ VCBATT_sleepDuration m0 : 24|16@1+ (0.25,0) [0|0] "" Vector__XXX
 SG_ VCBATT1_LVBatteryVoltOffsetRaw m2 : 23|9@1- (0.004,0) [0|0] "" Vector__XXX
 SG_ VCBATT1_autopilot1VoltOffsetRaw m3 : 23|9@1- (0.004,0) [0|0] "" Vector__XXX
 SG_ VCBATT1_brakeMotor1VoltOffsetRaw m4 : 23|9@1- (0.004,0) [0|0] "" Vector__XXX
 SG_ VCBATT1_brakeValve1VoltOffsetRaw m5 : 23|9@1- (0.004,0) [0|0] "" Vector__XXX
 SG_ VCBATT1_epas1VoltOffsetRaw m6 : 23|9@1- (0.004,0) [0|0] "" Vector__XXX
 SG_ VCBATT_vehicleSleepCurrent m1 : 22|14@1+ (0.125,-2047.875) [0|0] "" Vector__XXX
 SG_ VCBATT1_LVBatteryResistance m2 : 13|10@1+ (0.0005,0) [0|0] "" Vector__XXX
 SG_ VCBATT1_autopilot1Resistance m3 : 13|10@1+ (0.0005,0) [0|0] "" Vector__XXX
 SG_ VCBATT1_brakeMotor1Resistance m4 : 13|10@1+ (0.0005,0) [0|0] "" Vector__XXX
 SG_ VCBATT1_brakeValve1Resistance m5 : 13|10@1+ (0.0005,0) [0|0] "" Vector__XXX
 SG_ VCBATT1_epas1Resistance m6 : 13|10@1+ (0.0005,0) [0|0] "" Vector__XXX
 SG_ VCBATT_silentWakeCount m0 : 13|10@1+ (1,0) [0|0] "" Vector__XXX
 SG_ VCBATT_batterySleepCurrent m1 : 8|14@1+ (0.125,-2047.875) [0|0] "" Vector__XXX
 SG_ VCBATT1_LVBatteryResistanceRaw m2 : 3|10@1+ (0.0005,0) [0|0] "" Vector__XXX
 SG_ VCBATT1_autopilot1ResistanceRaw m3 : 3|10@1+ (0.0005,0) [0|0] "" Vector__XXX
 SG_ VCBATT1_brakeMotor1ResistanceRaw m4 : 3|10@1+ (0.0005,0) [0|0] "" Vector__XXX
 SG_ VCBATT1_brakeValve1ResistanceRaw m5 : 3|10@1+ (0.0005,0) [0|0] "" Vector__XXX
 SG_ VCBATT1_epas1ResistanceRaw m6 : 3|10@1+ (0.0005,0) [0|0] "" Vector__XXX
 SG_ VCBATT_timeSpentSleeping m0 : 3|10@1+ (1,0) [0|0] "" Vector__XXX
 SG_ VCBATT1_logging0point1HzIndex M : 0|3@1+ (1,0) [0|0] "" Vector__XXX

BO_ 1443 VCFRONT1_logging0point1Hz: 8 Vector__XXX
 SG_ VCFRONT1_autopilot2VoltOffsetAvg m1 : 58|6@1+ (0.002,0) [0|0] "" Vector__XXX
 SG_ VCFRONT1_brakeMotor2VoltOffsetAv m2 : 58|6@1+ (0.002,0) [0|0] "" Vector__XXX
 SG_ VCFRONT1_brakeValve2VoltOffsetAv m3 : 58|6@1+ (0.002,0) [0|0] "" Vector__XXX
 SG_ VCFRONT1_epas2VoltOffsetAvgDevia m4 : 58|6@1+ (0.002,0) [0|0] "" Vector__XXX
 SG_ VCFRONT1_pcsVoltOffsetAvgDeviati m0 : 58|6@1+ (0.002,0) [0|0] "" Vector__XXX
 SG_ VCFRONT1_autopilot2CurrAvgDeviat m1 : 52|6@1+ (0.05,0) [0|0] "" Vector__XXX
 SG_ VCFRONT1_brakeMotor2CurrAvgDevia m2 : 52|6@1+ (0.05,0) [0|0] "" Vector__XXX
 SG_ VCFRONT1_brakeValve2CurrAvgDevia m3 : 52|6@1+ (0.05,0) [0|0] "" Vector__XXX
 SG_ VCFRONT1_epas2CurrAvgDeviation m4 : 52|6@1+ (0.05,0) [0|0] "" Vector__XXX
 SG_ VCFRONT1_pcsCurrAvgDeviation m0 : 52|6@1+ (0.05,0) [0|0] "" Vector__XXX
 SG_ VCFRONT1_autopilot2ResistanceAcc m1 : 47|5@1+ (0.0005,0) [0|0] "" Vector__XXX
 SG_ VCFRONT1_brakeMotor2ResistanceAc m2 : 47|5@1+ (0.0005,0) [0|0] "" Vector__XXX
 SG_ VCFRONT1_brakeValve2ResistanceAc m3 : 47|5@1+ (0.0005,0) [0|0] "" Vector__XXX
 SG_ VCFRONT1_epas2ResistanceAcc m4 : 47|5@1+ (0.0005,0) [0|0] "" Vector__XXX
 SG_ VCFRONT1_pcsResistanceAcc m0 : 47|5@1+ (0.0005,0) [0|0] "" Vector__XXX
 SG_ VCFRONT1_autopilot2Resistan_0000 m1 : 42|5@1+ (0.0005,0) [0|0] "" Vector__XXX
 SG_ VCFRONT1_brakeMotor2Resista_0000 m2 : 42|5@1+ (0.0005,0) [0|0] "" Vector__XXX
 SG_ VCFRONT1_brakeValve2Resista_0000 m3 : 42|5@1+ (0.0005,0) [0|0] "" Vector__XXX
 SG_ VCFRONT1_epas2ResistanceAccRaw m4 : 42|5@1+ (0.0005,0) [0|0] "" Vector__XXX
 SG_ VCFRONT1_pcsResistanceAccRaw m0 : 42|5@1+ (0.0005,0) [0|0] "" Vector__XXX
 SG_ VCFRONT1_autopilot2VoltOffsetVal m1 : 41|1@1+ (1,0) [0|0] "" Vector__XXX
 SG_ VCFRONT1_brakeMotor2VoltOffsetVa m2 : 41|1@1+ (1,0) [0|0] "" Vector__XXX
 SG_ VCFRONT1_brakeValve2VoltOffsetVa m3 : 41|1@1+ (1,0) [0|0] "" Vector__XXX
 SG_ VCFRONT1_epas2VoltOffsetValid m4 : 41|1@1+ (1,0) [0|0] "" Vector__XXX
 SG_ VCFRONT1_pcsVoltOffsetValid m0 : 41|1@1+ (1,0) [0|0] "" Vector__XXX
 SG_ VCFRONT1_autopilot2VoltOffsetCal m1 : 32|9@1- (0.004,0) [0|0] "" Vector__XXX
 SG_ VCFRONT1_brakeMotor2VoltOffsetCa m2 : 32|9@1- (0.004,0) [0|0] "" Vector__XXX
 SG_ VCFRONT1_brakeValve2VoltOffsetCa m3 : 32|9@1- (0.004,0) [0|0] "" Vector__XXX
 SG_ VCFRONT1_epas2VoltOffsetCal m4 : 32|9@1- (0.004,0) [0|0] "" Vector__XXX
 SG_ VCFRONT1_pcsVoltOffsetCal m0 : 32|9@1- (0.004,0) [0|0] "" Vector__XXX
 SG_ VCFRONT1_autopilot2VoltOffsetRaw m1 : 23|9@1- (0.004,0) [0|0] "" Vector__XXX
 SG_ VCFRONT1_brakeMotor2VoltOffsetRa m2 : 23|9@1- (0.004,0) [0|0] "" Vector__XXX
 SG_ VCFRONT1_brakeValve2VoltOffsetRa m3 : 23|9@1- (0.004,0) [0|0] "" Vector__XXX
 SG_ VCFRONT1_epas2VoltOffsetRaw m4 : 23|9@1- (0.004,0) [0|0] "" Vector__XXX
 SG_ VCFRONT1_pcsVoltOffsetRaw m0 : 23|9@1- (0.004,0) [0|0] "" Vector__XXX
 SG_ VCFRONT1_autopilot2Resistance m1 : 13|10@1+ (0.0005,0) [0|0] "" Vector__XXX
 SG_ VCFRONT1_brakeMotor2Resistance m2 : 13|10@1+ (0.0005,0) [0|0] "" Vector__XXX
 SG_ VCFRONT1_brakeValve2Resistance m3 : 13|10@1+ (0.0005,0) [0|0] "" Vector__XXX
 SG_ VCFRONT1_epas2Resistance m4 : 13|10@1+ (0.0005,0) [0|0] "" Vector__XXX
 SG_ VCFRONT1_pcsResistance m0 : 13|10@1+ (0.0005,0) [0|0] "" Vector__XXX
 SG_ VCFRONT1_autopilot2ResistanceRaw m1 : 3|10@1+ (0.0005,0) [0|0] "" Vector__XXX
 SG_ VCFRONT1_brakeMotor2ResistanceRa m2 : 3|10@1+ (0.0005,0) [0|0] "" Vector__XXX
 SG_ VCFRONT1_brakeValve2ResistanceRa m3 : 3|10@1+ (0.0005,0) [0|0] "" Vector__XXX
 SG_ VCFRONT1_epas2ResistanceRaw m4 : 3|10@1+ (0.0005,0) [0|0] "" Vector__XXX
 SG_ VCFRONT1_pcsResistanceRaw m0 : 3|10@1+ (0.0005,0) [0|0] "" Vector__XXX
 SG_ VCFRONT1_logging0point1HzIndex M : 0|3@1+ (1,0) [0|0] "" Vector__XXX

CM_ BO_ 1373 "ESP32-DualCAN Model3_VEH. Seen on this car: 8-byte frames; fit ok (bits covered 96%, mux 51%, ranges 100%).";
VAL_ 1373 VCLEFT_a381_tireFitment 0 "SQUARE" 1 "STAGGERED" 3 "SNA" ;
VAL_ 1373 VCLEFT_a236_lumbarBState 0 "STOPPED" 1 "MOVING_UP" 2 "MOVING_DOWN" 3 "RECALLING" 4 "CALIBRATING" 5 "UNDEFINED" ;
VAL_ 1373 VCLEFT_a237_lumbarBState 0 "STOPPED" 1 "MOVING_UP" 2 "MOVING_DOWN" 3 "RECALLING" 4 "CALIBRATING" 5 "UNDEFINED" ;
VAL_ 1373 VCLEFT_a238_lumbarBState 0 "STOPPED" 1 "MOVING_UP" 2 "MOVING_DOWN" 3 "RECALLING" 4 "CALIBRATING" 5 "UNDEFINED" ;
VAL_ 1373 VCLEFT_a236_lumbarAState 0 "STOPPED" 1 "MOVING_UP" 2 "MOVING_DOWN" 3 "RECALLING" 4 "CALIBRATING" 5 "UNDEFINED" ;
VAL_ 1373 VCLEFT_a237_lumbarAState 0 "STOPPED" 1 "MOVING_UP" 2 "MOVING_DOWN" 3 "RECALLING" 4 "CALIBRATING" 5 "UNDEFINED" ;
VAL_ 1373 VCLEFT_a238_lumbarAState 0 "STOPPED" 1 "MOVING_UP" 2 "MOVING_DOWN" 3 "RECALLING" 4 "CALIBRATING" 5 "UNDEFINED" ;
VAL_ 1373 VCLEFT_a180_latchStatus 0 "SNA" 1 "OPENED" 2 "CLOSED" 3 "CLOSING" 4 "OPENING" 5 "AJAR" 6 "TIMEOUT" 7 "DEFAULT" 8 "FAULT" ;
VAL_ 1373 VCLEFT_a181_latchStatus 0 "SNA" 1 "OPENED" 2 "CLOSED" 3 "CLOSING" 4 "OPENING" 5 "AJAR" 6 "TIMEOUT" 7 "DEFAULT" 8 "FAULT" ;
VAL_ 1373 VCLEFT_a104_BDY_status 0 "DISABLED" 1 "ENABLED" 2 "TEMPORARY_FAILURE" 3 "SNA" ;
VAL_ 1373 VCLEFT_a104_VEH_status 0 "DISABLED" 1 "ENABLED" 2 "TEMPORARY_FAILURE" 3 "SNA" ;
VAL_ 1373 VCLEFT_a117_VEH_status 0 "DISABLED" 1 "ENABLED" 2 "TEMPORARY_FAILURE" 3 "SNA" ;
VAL_ 1373 VCLEFT_a114_CH_status 0 "DISABLED" 1 "ENABLED" 2 "TEMPORARY_FAILURE" 3 "SNA" ;
VAL_ 1373 VCLEFT_a113_VEH_status 0 "DISABLED" 1 "ENABLED" 2 "TEMPORARY_FAILURE" 3 "SNA" ;
VAL_ 1373 VCLEFT_a109_CH_status 0 "DISABLED" 1 "ENABLED" 2 "TEMPORARY_FAILURE" 3 "SNA" ;
VAL_ 1373 VCLEFT_a114_BDY_status 0 "DISABLED" 1 "ENABLED" 2 "TEMPORARY_FAILURE" 3 "SNA" ;
VAL_ 1373 VCLEFT_a116_VEH_status 0 "DISABLED" 1 "ENABLED" 2 "TEMPORARY_FAILURE" 3 "SNA" ;
VAL_ 1373 VCLEFT_a104_PARTY_status 0 "DISABLED" 1 "ENABLED" 2 "TEMPORARY_FAILURE" 3 "SNA" ;
VAL_ 1373 VCLEFT_a104_CH_status 0 "DISABLED" 1 "ENABLED" 2 "TEMPORARY_FAILURE" 3 "SNA" ;
VAL_ 1373 VCLEFT_a374_trailerMode 0 "OFF" 1 "ON" ;
VAL_ 1373 VCLEFT_a111_CH_status 0 "DISABLED" 1 "ENABLED" 2 "TEMPORARY_FAILURE" 3 "SNA" ;
VAL_ 1373 VCLEFT_a120_PT_systemStatus 0 "UNKNOWN" 1 "RELEASED" 2 "PARKED" 3 "DYNAMIC" 4 "PARKING" 5 "RELEASING" 6 "FAULT" 7 "FAULT_SECURE" 8 "MISMATCH" ;
VAL_ 1373 VCLEFT_a525_serviceMode 0 "DISABLED" 1 "ENABLED" ;
VAL_ 1373 VCLEFT_a599_serviceMode 0 "DISABLED" 1 "ENABLED" ;
VAL_ 1373 VCLEFT_a109_BDY_status 0 "DISABLED" 1 "ENABLED" 2 "TEMPORARY_FAILURE" 3 "SNA" ;
VAL_ 1373 VCLEFT_a110_CH_airbagCutoffStatu 0 "RCM_PASSENGER_AIRBAG_ENABLED" 1 "RCM_PASSENGER_AIRBAG_DISABLED" 3 "SNA" ;
VAL_ 1373 VCLEFT_a111_PARTY_status 0 "DISABLED" 1 "ENABLED" 2 "TEMPORARY_FAILURE" 3 "SNA" ;
VAL_ 1373 VCLEFT_a112_CH_status 0 "DISABLED" 1 "ENABLED" 2 "TEMPORARY_FAILURE" 3 "SNA" ;
VAL_ 1373 VCLEFT_a112_PARTY_status 0 "DISABLED" 1 "ENABLED" 2 "TEMPORARY_FAILURE" 3 "SNA" ;
VAL_ 1373 VCLEFT_a118_VEH_systemStatus 0 "UNKNOWN" 1 "RELEASED" 2 "PARKED" 3 "DYNAMIC" 4 "PARKING" 5 "RELEASING" 6 "FAULT" 7 "FAULT_SECURE" 8 "MISMATCH" ;
VAL_ 1373 VCLEFT_a120_PARTY_status 0 "DISABLED" 1 "ENABLED" 2 "TEMPORARY_FAILURE" 3 "SNA" ;
VAL_ 1373 VCLEFT_a107_PT_status 0 "DISABLED" 1 "ENABLED" 2 "TEMPORARY_FAILURE" 3 "SNA" ;
VAL_ 1373 VCLEFT_a086_VEH_systemStatus 0 "UNKNOWN" 1 "RELEASED" 2 "PARKED" 3 "DYNAMIC" 4 "PARKING" 5 "RELEASING" 6 "FAULT" 7 "FAULT_SECURE" 8 "MISMATCH" ;
VAL_ 1373 VCLEFT_a098_PARTY_status 0 "DISABLED" 1 "ENABLED" 2 "TEMPORARY_FAILURE" 3 "SNA" ;
VAL_ 1373 VCLEFT_a108_PARTY_status 0 "DISABLED" 1 "ENABLED" 2 "TEMPORARY_FAILURE" 3 "SNA" ;
VAL_ 1373 VCLEFT_a114_VEH_status 0 "DISABLED" 1 "ENABLED" 2 "TEMPORARY_FAILURE" 3 "SNA" ;
VAL_ 1373 VCLEFT_a545_serviceMode 0 "DISABLED" 1 "ENABLED" ;
VAL_ 1373 VCLEFT_a087_PARTY_status 0 "DISABLED" 1 "ENABLED" 2 "TEMPORARY_FAILURE" 3 "SNA" ;
VAL_ 1373 VCLEFT_a088_PARTY_status 0 "DISABLED" 1 "ENABLED" 2 "TEMPORARY_FAILURE" 3 "SNA" ;
VAL_ 1373 VCLEFT_a089_CH_status 0 "DISABLED" 1 "ENABLED" 2 "TEMPORARY_FAILURE" 3 "SNA" ;
VAL_ 1373 VCLEFT_a089_BDY_status 0 "DISABLED" 1 "ENABLED" 2 "TEMPORARY_FAILURE" 3 "SNA" ;
VAL_ 1373 VCLEFT_a103_PT_status 0 "DISABLED" 1 "ENABLED" 2 "TEMPORARY_FAILURE" 3 "SNA" ;
VAL_ 1373 VCLEFT_a108_VEH_status 0 "DISABLED" 1 "ENABLED" 2 "TEMPORARY_FAILURE" 3 "SNA" ;
VAL_ 1373 VCLEFT_a109_VEH_status 0 "DISABLED" 1 "ENABLED" 2 "TEMPORARY_FAILURE" 3 "SNA" ;
VAL_ 1373 VCLEFT_a087_VEH_status 0 "DISABLED" 1 "ENABLED" 2 "TEMPORARY_FAILURE" 3 "SNA" ;
VAL_ 1373 VCLEFT_a088_VEH_status 0 "DISABLED" 1 "ENABLED" 2 "TEMPORARY_FAILURE" 3 "SNA" ;
VAL_ 1373 VCLEFT_a118_VEH_status 0 "DISABLED" 1 "ENABLED" 2 "TEMPORARY_FAILURE" 3 "SNA" ;
VAL_ 1373 VCLEFT_a120_PARTY_systemStatus 0 "UNKNOWN" 1 "RELEASED" 2 "PARKED" 3 "DYNAMIC" 4 "PARKING" 5 "RELEASING" 6 "FAULT" 7 "FAULT_SECURE" 8 "MISMATCH" ;
VAL_ 1373 VCLEFT_a276_mirrorState 0 "IDLE" 1 "TILT_X" 2 "TILT_Y" 3 "FOLD_UNFOLD" 4 "RECALL" ;
VAL_ 1373 VCLEFT_a086_VEH_status 0 "DISABLED" 1 "ENABLED" 2 "TEMPORARY_FAILURE" 3 "SNA" ;
VAL_ 1373 VCLEFT_a089_VEH_status 0 "DISABLED" 1 "ENABLED" 2 "TEMPORARY_FAILURE" 3 "SNA" ;
VAL_ 1373 VCLEFT_a091_VEH_state 0 "STANDBY" 1 "DRIVE" 2 "SUPPORT" 3 "CHARGE" 4 "FEIM" 5 "CLEAR_FAULT" 6 "FAULT" 7 "WELD" 8 "TEST" 9 "SNA" 10 "DIAG" ;
VAL_ 1373 VCLEFT_a098_VEH_status 0 "DISABLED" 1 "ENABLED" 2 "TEMPORARY_FAILURE" 3 "SNA" ;
VAL_ 1373 VCLEFT_a103_VEH_status 0 "DISABLED" 1 "ENABLED" 2 "TEMPORARY_FAILURE" 3 "SNA" ;
VAL_ 1373 VCLEFT_a107_VEH_status 0 "DISABLED" 1 "ENABLED" 2 "TEMPORARY_FAILURE" 3 "SNA" ;
VAL_ 1373 VCLEFT_a089_PARTY_status 0 "DISABLED" 1 "ENABLED" 2 "TEMPORARY_FAILURE" 3 "SNA" ;
VAL_ 1373 VCLEFT_a090_VEH_state 0 "STANDBY" 1 "DRIVE" 2 "SUPPORT" 3 "CHARGE" 4 "FEIM" 5 "CLEAR_FAULT" 6 "FAULT" 7 "WELD" 8 "TEST" 9 "SNA" 10 "DIAG" ;
VAL_ 1373 VCLEFT_a095_PT_status 0 "DISABLED" 1 "ENABLED" 2 "TEMPORARY_FAILURE" 3 "SNA" ;
VAL_ 1373 VCLEFT_a096_CH_status 0 "DISABLED" 1 "ENABLED" 2 "TEMPORARY_FAILURE" 3 "SNA" ;
VAL_ 1373 VCLEFT_a097_VEH_state 0 "STANDBY" 1 "DRIVE" 2 "SUPPORT" 3 "CHARGE" 4 "FEIM" 5 "CLEAR_FAULT" 6 "FAULT" 7 "WELD" 8 "TEST" 9 "SNA" 10 "DIAG" ;
VAL_ 1373 VCLEFT_a111_VEH_status 0 "DISABLED" 1 "ENABLED" 2 "TEMPORARY_FAILURE" 3 "SNA" ;
VAL_ 1373 VCLEFT_a112_VEH_status 0 "DISABLED" 1 "ENABLED" 2 "TEMPORARY_FAILURE" 3 "SNA" ;
VAL_ 1373 VCLEFT_a120_VEH_systemStatus 0 "UNKNOWN" 1 "RELEASED" 2 "PARKED" 3 "DYNAMIC" 4 "PARKING" 5 "RELEASING" 6 "FAULT" 7 "FAULT_SECURE" 8 "MISMATCH" ;
VAL_ 1373 VCLEFT_a031_uds_bytes_0 0 "0" 1 "1" 2 "2" 3 "3" 4 "4" 5 "5" 6 "6" 7 "7" 8 "8" 9 "9" 10 "10" 11 "11" 12 "12" 13 "13" 14 "14" 15 "15" 16 "16" 17 "17" 18 "18" 19 "19" 20 "20" 21 "21" 22 "22" 23 "23" 24 "24" 25 "25" 26 "26" 27 "27" 28 "28" 29 "29" 30 "30" 31 "31" ;
VAL_ 1373 VCLEFT_a096_VEH_status 0 "DISABLED" 1 "ENABLED" 2 "TEMPORARY_FAILURE" 3 "SNA" ;
VAL_ 1373 VCLEFT_a101_VEH_state 0 "STANDBY" 1 "DRIVE" 2 "SUPPORT" 3 "CHARGE" 4 "FEIM" 5 "CLEAR_FAULT" 6 "FAULT" 7 "WELD" 8 "TEST" 9 "SNA" 10 "DIAG" ;
VAL_ 1373 VCLEFT_a109_PARTY_status 0 "DISABLED" 1 "ENABLED" 2 "TEMPORARY_FAILURE" 3 "SNA" ;
VAL_ 1373 VCLEFT_a114_PARTY_status 0 "DISABLED" 1 "ENABLED" 2 "TEMPORARY_FAILURE" 3 "SNA" ;
VAL_ 1373 VCLEFT_a122_VEH_status 0 "DISABLED" 1 "ENABLED" 2 "TEMPORARY_FAILURE" 3 "SNA" ;
VAL_ 1373 VCLEFT_a185_summonFaultReason 0 "NONE" 1 "DI_MIA" 2 "DAS_MIA" 3 "ESP_MIA" 4 "EPBM_MIA" 5 "DI_FAULT" 6 "DI_APC_FAULT" 7 "DAS_FAULT" 8 "ESP_FAULT" 9 "VEH_CAN_FAULT" 10 "EAC_NOT_ALLOWED" 11 "EPBM_REQUEST" 12 "SPEED" 13 "EXTERNAL" 14 "PARK_MIA" 15 "PM_MIA" 16 "PM_REQUEST" 17 "OOC" 18 "MISMATCH" 19 "EPB_FAULT" 20 "DI_STATE_INVALID" 21 "PASSIVE_REQUEST" 22 "EPBREMOTE_MIA" 23 "REMOTE_SUMMON_FAULTED" 24 "LOCAL_UNIT_FAULTED" 25 "REMOTE_UNIT_FAULTED" 26 "START_IN_UNAVAILABLE" 27 "INVALID_REMOTE_STATE" 28 "REMOTE_DID_NOT_START" ;
VAL_ 1373 VCLEFT_a355_liftgateStoppingCond 0 "NONE" 1 "PINCH" 2 "OBSTACLE_STALL" 3 "LOW_12V" 4 "STATE_TIMEOUT" 5 "VEHICLE_AT_SPEED" 6 "OBSTACLE_CURRENT" 7 "OBSTACLE_TRAJ_POS" 8 "OBSTACLE_TRAJ_VEL" 9 "UNCALIBRATED" 10 "LATCH_FAULT" 11 "COUNT" ;
VAL_ 1373 VCLEFT_a357_liftgateState 0 "INIT" 1 "OFF" 2 "BACKOFF" 3 "OPENING" 4 "CLOSING" 5 "CLOSED" 6 "LATCH_OPENING" 7 "LATCH_CLOSING" 8 "NOT_INSTALLED" 9 "UNKNOWN" 10 "LATCH_EXIT" 11 "END_OF_TRAVEL" 12 "LATCH_ENTRY" ;
VAL_ 1373 VCLEFT_a360_vehicleSpeed 8191 "SNA" ;
VAL_ 1373 VCLEFT_a455_liftgateState 0 "INIT" 1 "OFF" 2 "BACKOFF" 3 "OPENING" 4 "CLOSING" 5 "CLOSED" 6 "LATCH_OPENING" 7 "LATCH_CLOSING" 8 "NOT_INSTALLED" 9 "UNKNOWN" 10 "LATCH_EXIT" 11 "END_OF_TRAVEL" 12 "LATCH_ENTRY" ;
VAL_ 1373 VCLEFT_a525_GTW_twelveVBatteryTy 0 "ATLASBX_B24_FLOODED" 1 "CLARIOS_B24_FLOODED" ;
VAL_ 1373 VCLEFT_a545_GTW_twelveVBatteryTy 0 "ATLASBX_B24_FLOODED" 1 "CLARIOS_B24_FLOODED" ;
VAL_ 1373 VCLEFT_a583_ambientTemp 4294966273 "SNA" ;
VAL_ 1373 VCLEFT_a584_ambientTemp 4294966273 "SNA" ;
VAL_ 1373 VCLEFT_a585_ambientTemp 4294966273 "SNA" ;
VAL_ 1373 VCLEFT_a586_ambientTemp 4294966273 "SNA" ;
VAL_ 1373 VCLEFT_a599_GTW_twelveVBatteryTy 0 "ATLASBX_B24_FLOODED" 1 "CLARIOS_B24_FLOODED" ;
VAL_ 1373 VCLEFT_alertState 0 "CLEARED" 1 "SET" ;
VAL_ 1373 VCLEFT_alertID 0 "ALERT_DO_NOT_USE_ZERO" 1 "a001_DriverDoorOpen" 2 "a002_DoorOpen" 3 "a003_TrunkOpen" 4 "a004_FrunkOpen" 5 "a005_HeadlightsOnDoorOpen" 6 "a006_RemoteServiceAlert" 7 "a007_SoftPackConfigMismatch" 8 "a008_TouchScreenError" 9 "a009_SquashfsError" 10 "a010_MapsMissing" 11 "a011_IncorrectMap" 12 "a012_NotOnPrivateProperty" 13 "a013_TPMSHardWarning" 14 "a014_TPMSSoftWarning" 15 "a015_TPMSOverPressureWarning" 16 "a016_TPMSTemperatureWarning" 17 "a017_TPMSSystemFault" 18 "a018_SlipStartOn" 19 "a019_ParkBrakeFault" 20 "a020_SteeringReduced" 21 "a021_RearSeatbeltUnbuckled" 22 "a022_ApeFusesEtc" 23 "a023_CellInternetCheckFailed" 24 "a024_WifiInternetCheckFailed" 25 "a025_WifiOnlineCheckFailed" 26 "a026_ModemResetLoopDetected" 27 "a027_AutoSteerMIA" 28 "a028_FrontTrunkPopupClosed" 29 "a029_ModemMIA" 30 "a030_ModemVMCrash" 31 "a031_BrakeFluidLow" 32 "a032_CellModemRecoveryResets" 33 "a033_ApTrialExpired" 34 "a034_WakeupProblem" 35 "a035_AudioWatchdogKernelError" 36 "a036_AudioWatchdogHfpError" 37 "a037_AudioWatchdogXrunStormError" 38 "a038_AudioWatchdogA2bI2cLockupError" 39 "a039_AudioA2bNeedRediscovery" 40 "a040_HomelinkTransmit" 41 "a041_AudioDmesgXrun" 42 "a042_AudioDmesgRtThrottling" 43 "a043_InvalidMapDataOverride" 44 "a044_AudioDmesgDspException" 45 "a045_ECallNeedsService" 46 "a046_BackupCameraStreamError" 47 "a047_CellRoamingDisallowed" 48 "a048_AudioPremiumAmpCheckFailed" 49 "a049_BrakeShiftRequired" 50 "a050_BackupCameraIPUTimeout" 51 "a051_BackupCameraFrameTimeout" 52 "a052_KernelPanicReported" 53 "a053_QtCarExitError" 54 "a054_AudioBoostPowerBad" 55 "a055_ManualECallDisabled" 56 "a056_ManualECallButtonDisconnected" 57 "a057_CellAntennaDisconnected" 58 "a058_GPSAntennaDisconnected" 59 "a059_ECallSpeakerDisconnected" 60 "a060_ECallMicDisconnected" 61 "a061_SIMTestFailed" 62 "a062_ENSTestFailed" 63 "a063_CellularTestFailed" 64 "a064_ModemFirmwareTestFailed" 65 "a065_WiFiRecoveryReset" 66 "a066_GpuHangDetected" 67 "a067_WarnOnI915" 68 "a068_VideoUnexpectedExit" 69 "a069_VideoUDPTimeout" 70 "a070_VideoPipelineWarning" 71 "a071_VideoPipelineError" 72 "a072_ECallAnalogMicFailed" 73 "a073_ECallDigitalMicFailed" 74 "a074_EMMCHangDetected" 75 "a075_BackupCameraInitError" 76 "a076_NumFalseManualECalls" 77 "a077_AudioA2bMicChannelSwap" 78 "a078_DashcamUsbDriveUnmountable" 79 "a079_DashcamUsbDriveFull" 80 "a080_DashcamUsbDriveSlow" 81 "a081_CellModemSearchExpired" 82 "a082_NumModemRebootStuckInECall" 83 "a083_ECallProxyWatchdogTriggered" 84 "a084_SerializerError" 85 "a085_DeserializerError" 86 "a086_TouchEnumerationError" 87 "a087_BmpReset" 88 "a088_CellRemovableSimMissing" 89 "a089_RadioSoftResetError" 90 "a090_RadioPingFailError" 91 "a091_VehicleLinkStall" 92 "a092_updateStarted" 93 "a093_updateEnded" 94 "a094_ModemPowerOnFailure" 95 "a095_CidStorageRunningLow" 96 "a096_VideodPipelineIssueDetected" 97 "a097_AudiodRestarted" 98 "a098_DiskCheckFailure" 99 "a099_eMMCStatusError" 100 "a100_eMMCFTLError" 101 "a101_wifiStackProblem" 102 "a102_A2bDiscoveryFailed" 103 "a103_UsbHubNotEnumerating" 104 "a104_DashcamUsbDriveMissing" 105 "a105_firmwareReinstallRequested" 106 "a106_rebootBackstopTriggered" 107 "a107_DashcamUsbDriveTooBigForVfatFsck" 108 "a108_DashcamUsbDriveGettingFull" 109 "a109_DashcamUsbDriveTooSmall" 110 "a110_DashcamUsbDriveCorrupt" 111 "a111_DashcamUsbDriveWrongPort" 112 "a112_badUSBDevice" 113 "a113_DashcamHasOnboardSentryClips" ;
CM_ BO_ 1377 "ESP32-DualCAN Model3_VEH. Not seen on this car in the logs.";
CM_ BO_ 1378 "ESP32-DualCAN Model3_VEH. Not seen on this car in the logs.";
VAL_ 1378 VCBATT1_vehiclePowerStateDBG 0 "INIT" 1 "LOW_POWER_AWAKE" 2 "CONDITIONING" 3 "ACCESSORY" 4 "ACCESSORY_PLUS" 5 "DRIVE" 6 "OTA" 7 "WAIT_FOR_HIGH_POWER" 8 "TURN_ON_LV" 9 "SYSTEM_CHECKS" 10 "LV_ON" 11 "JUMP_START" 12 "LV_SHUTDOWN" 13 "GO_QUIET" 14 "SLEEP_SHUTDOWN" 15 "LOW_POWER_STANDBY" 16 "RESET" ;
CM_ BO_ 1379 "ESP32-DualCAN Model3_VEH. Not seen on this car in the logs.";
VAL_ 1379 TAS_current_RR_R 31 "SNA" ;
VAL_ 1379 TAS_current_RR_C 31 "SNA" ;
VAL_ 1379 TAS_current_RL_R 31 "SNA" ;
VAL_ 1379 TAS_current_RL_C 31 "SNA" ;
VAL_ 1379 TAS_current_FR_R 31 "SNA" ;
VAL_ 1379 TAS_current_FR_C 31 "SNA" ;
VAL_ 1379 TAS_current_FL_R 31 "SNA" ;
VAL_ 1379 TAS_current_FL_C 31 "SNA" ;
CM_ BO_ 1381 "ESP32-DualCAN Model3_VEH. Not seen on this car in the logs.";
VAL_ 1381 VCFRONT2_vehiclePowerStateDBG 0 "INIT" 1 "LOW_POWER_AWAKE" 2 "CONDITIONING" 3 "ACCESSORY" 4 "ACCESSORY_PLUS" 5 "DRIVE" 6 "OTA" 7 "WAIT_FOR_HIGH_POWER" 8 "TURN_ON_LV" 9 "SYSTEM_CHECKS" 10 "LV_ON" 11 "JUMP_START" 12 "LV_SHUTDOWN" 13 "GO_QUIET" 14 "SLEEP_SHUTDOWN" 15 "LOW_POWER_STANDBY" 16 "RESET" ;
CM_ BO_ 1383 "ESP32-DualCAN Model3_CH. Seen on this car: 8-byte frames; fit good (bits covered 87%, mux 100%, ranges 100%).";
VAL_ 1383 ADSP_eCallSpeakerStatus 0 "NOT_RUN_YET" 1 "PASSED" 2 "FAILED_DISCONNECT" 3 "FAILED_DIAG" ;
VAL_ 1383 ADSP_eCallMicrophoneStatus 0 "NOT_RUN_YET" 1 "PASSED" 2 "FAILED" ;
VAL_ 1383 ADSP_eCallState 0 "INACTIVE" 1 "ACTIVE" ;
VAL_ 1383 ADSP_eCallSelfTest 0 "NOT_RUN_YET" 1 "PASSED" 2 "FAILED" ;
VAL_ 1383 ADSP_eCall_ENS_state 0 "UNKOWN" 1 "SIGNAL_ERROR" 2 "SOURCE_MISSING" 3 "SOURCE_ERROR" 4 "EMERGENCY" 5 "NORMAL" ;
VAL_ 1383 ADSP_ancMode 0 "OFF" 1 "FRONT" 2 "REAR" 3 "ALL" 4 "CALIBRATING_00" 5 "DISABLED_REASON_A2BA" 6 "DISABLED_REASON_A2BB" 7 "DISABLED_REASON_CLOSURE_OPEN" 8 "DISABLED_REASON_HVAC" 9 "DISABLED_REASON_SEAT_MOVING" 10 "DISABLED_REASON_REAR_OCCUPANT" 11 "DISABLED_REASON_WINDOW_OPEN" 12 "CALIBRATING_20" 13 "CALIBRATING_40" 14 "CALIBRATING_60" 15 "CALIBRATING_80" 16 "UNKNOWN" ;
VAL_ 1383 ADSP_tunerSelect 0 "FM" 1 "XM" ;
VAL_ 1383 ADSP_sourceSelect 0 "MEDIA" 1 "A2DP" 2 "TUNER" 3 "SINE" 4 "PINK" ;
VAL_ 1383 ADSP_ancState 0 "INIT" 1 "DSP_OFF" 2 "DSP_ON" 3 "ENABLED" ;
VAL_ 1383 ADSP_baseamp2State 0 "INIT" 1 "CONFIGURED" 2 "ENABLED" 3 "HALT" 4 "TURN_OFF" 5 "OFF" 6 "DIAG" ;
VAL_ 1383 ADSP_baseamp1State 0 "INIT" 1 "CONFIGURED" 2 "ENABLED" 3 "HALT" 4 "TURN_OFF" 5 "OFF" 6 "DIAG" ;
VAL_ 1383 ADSP_baseamp0State 0 "INIT" 1 "CONFIGURED" 2 "ENABLED" 3 "HALT" 4 "TURN_OFF" 5 "OFF" 6 "DIAG" ;
VAL_ 1383 ADSP_a2bbState 0 "INIT" 1 "DOWN" 2 "RESTART" 3 "DISCOVER" 4 "DISCOVER_WAIT" 5 "IDLE" 6 "DIAG" 7 "DISCOVER_RETRY" 8 "GOING_DOWN" ;
VAL_ 1383 ADSP_a2baState 0 "INIT" 1 "DOWN" 2 "RESTART" 3 "DISCOVER" 4 "DISCOVER_WAIT" 5 "IDLE" 6 "DIAG" 7 "DISCOVER_RETRY" 8 "GOING_DOWN" ;
CM_ BO_ 1397 "ESP32-DualCAN Model3_CH. Seen on this car: 5-byte frames; fit ok (bits covered 75%, mux 100%, ranges 100%).";
CM_ BO_ 1398 "ESP32-DualCAN Model3_VEH. Not seen on this car in the logs.";
VAL_ 1398 TAS_FDUTorqueCorruptionScale 15 "SNA" ;
VAL_ 1398 TAS_stepProtectRR 0 "DISABLED" 1 "STANDBY" 2 "ARMED" 3 "ACTIVE" ;
VAL_ 1398 TAS_stepProtectRL 0 "DISABLED" 1 "STANDBY" 2 "ARMED" 3 "ACTIVE" ;
VAL_ 1398 TAS_stepProtectFR 0 "DISABLED" 1 "STANDBY" 2 "ARMED" 3 "ACTIVE" ;
VAL_ 1398 TAS_stepProtectFL 0 "DISABLED" 1 "STANDBY" 2 "ARMED" 3 "ACTIVE" ;
VAL_ 1398 TAS_holeProtectRR 0 "DISABLED" 1 "STANDBY" 2 "ARMED" 3 "ACTIVE" ;
VAL_ 1398 TAS_holeProtectRL 0 "DISABLED" 1 "STANDBY" 2 "ARMED" 3 "ACTIVE" ;
VAL_ 1398 TAS_holeProtectFR 0 "DISABLED" 1 "STANDBY" 2 "ARMED" 3 "ACTIVE" ;
VAL_ 1398 TAS_holeProtectFL 0 "DISABLED" 1 "STANDBY" 2 "ARMED" 3 "ACTIVE" ;
VAL_ 1398 TAS_speedBumpAxleRear 0 "DISABLED" 1 "STANDBY" 2 "ARMED" 3 "ACTIVE" ;
VAL_ 1398 TAS_speedBumpAxleFront 0 "DISABLED" 1 "STANDBY" 2 "ARMED" 3 "ACTIVE" ;
VAL_ 1398 TAS_roadCondition 255 "SNA" ;
VAL_ 1398 TAS_continuousControlState 0 "STANDBY" 1 "ACTIVE" ;
VAL_ 1398 TAS_endstopState 0 "STANDBY" 1 "ACTIVE" ;
CM_ BO_ 1399 "ESP32-DualCAN Model3_VEH. Not seen on this car in the logs.";
VAL_ 1399 VCBATT2_vehiclePowerStateDBG 0 "INIT" 1 "LOW_POWER_AWAKE" 2 "CONDITIONING" 3 "ACCESSORY" 4 "ACCESSORY_PLUS" 5 "DRIVE" 6 "OTA" 7 "WAIT_FOR_HIGH_POWER" 8 "TURN_ON_LV" 9 "SYSTEM_CHECKS" 10 "LV_ON" 11 "JUMP_START" 12 "LV_SHUTDOWN" 13 "GO_QUIET" 14 "SLEEP_SHUTDOWN" 15 "LOW_POWER_STANDBY" 16 "RESET" ;
CM_ BO_ 1400 "ESP32-DualCAN Model3_VEH. Not seen on this car in the logs.";
VAL_ 1400 VCFRONT1_vehiclePowerStateDBG 0 "INIT" 1 "LOW_POWER_AWAKE" 2 "CONDITIONING" 3 "ACCESSORY" 4 "ACCESSORY_PLUS" 5 "DRIVE" 6 "OTA" 7 "WAIT_FOR_HIGH_POWER" 8 "TURN_ON_LV" 9 "SYSTEM_CHECKS" 10 "LV_ON" 11 "JUMP_START" 12 "LV_SHUTDOWN" 13 "GO_QUIET" 14 "SLEEP_SHUTDOWN" 15 "LOW_POWER_STANDBY" 16 "RESET" ;
CM_ BO_ 1405 "ESP32-DualCAN Model3_VEH. Not seen on this car in the logs.";
CM_ BO_ 1425 "ESP32-DualCAN Model3_CH. Not seen on this car in the logs.";
VAL_ 1425 EPAS3S_a156_vehicleSpeed 8191 "SNA" ;
VAL_ 1425 EPAS3S_a155_vehicleSpeed 8191 "SNA" ;
VAL_ 1425 EPAS3S_a154_vehicleSpeed 8191 "SNA" ;
VAL_ 1425 EPAS3S_a148_vehicleSpeed 8191 "SNA" ;
VAL_ 1425 EPAS3S_alertState 0 "CLEARED" 1 "SET" ;
VAL_ 1425 EPAS3S_alertID 0 "ALERT_DO_NOT_USE_ZERO" 1 "a001_DriverDoorOpen" 2 "a002_DoorOpen" 3 "a003_TrunkOpen" 4 "a004_FrunkOpen" 5 "a005_HeadlightsOnDoorOpen" 6 "a006_RemoteServiceAlert" 7 "a007_SoftPackConfigMismatch" 8 "a008_TouchScreenError" 9 "a009_SquashfsError" 10 "a010_MapsMissing" 11 "a011_IncorrectMap" 12 "a012_NotOnPrivateProperty" 13 "a013_TPMSHardWarning" 14 "a014_TPMSSoftWarning" 15 "a015_TPMSOverPressureWarning" 16 "a016_TPMSTemperatureWarning" 17 "a017_TPMSSystemFault" 18 "a018_SlipStartOn" 19 "a019_ParkBrakeFault" 20 "a020_SteeringReduced" 21 "a021_RearSeatbeltUnbuckled" 22 "a022_ApeFusesEtc" 23 "a023_CellInternetCheckFailed" 24 "a024_WifiInternetCheckFailed" 25 "a025_WifiOnlineCheckFailed" 26 "a026_ModemResetLoopDetected" 27 "a027_AutoSteerMIA" 28 "a028_FrontTrunkPopupClosed" 29 "a029_ModemMIA" 30 "a030_ModemVMCrash" 31 "a031_BrakeFluidLow" 32 "a032_CellModemRecoveryResets" 33 "a033_ApTrialExpired" 34 "a034_WakeupProblem" 35 "a035_AudioWatchdogKernelError" 36 "a036_AudioWatchdogHfpError" 37 "a037_AudioWatchdogXrunStormError" 38 "a038_AudioWatchdogA2bI2cLockupError" 39 "a039_AudioA2bNeedRediscovery" 40 "a040_HomelinkTransmit" 41 "a041_AudioDmesgXrun" 42 "a042_AudioDmesgRtThrottling" 43 "a043_InvalidMapDataOverride" 44 "a044_AudioDmesgDspException" 45 "a045_ECallNeedsService" 46 "a046_BackupCameraStreamError" 47 "a047_CellRoamingDisallowed" 48 "a048_AudioPremiumAmpCheckFailed" 49 "a049_BrakeShiftRequired" 50 "a050_BackupCameraIPUTimeout" 51 "a051_BackupCameraFrameTimeout" 52 "a052_KernelPanicReported" 53 "a053_QtCarExitError" 54 "a054_AudioBoostPowerBad" 55 "a055_ManualECallDisabled" 56 "a056_ManualECallButtonDisconnected" 57 "a057_CellAntennaDisconnected" 58 "a058_GPSAntennaDisconnected" 59 "a059_ECallSpeakerDisconnected" 60 "a060_ECallMicDisconnected" 61 "a061_SIMTestFailed" 62 "a062_ENSTestFailed" 63 "a063_CellularTestFailed" 64 "a064_ModemFirmwareTestFailed" 65 "a065_WiFiRecoveryReset" 66 "a066_GpuHangDetected" 67 "a067_WarnOnI915" 68 "a068_VideoUnexpectedExit" 69 "a069_VideoUDPTimeout" 70 "a070_VideoPipelineWarning" 71 "a071_VideoPipelineError" 72 "a072_ECallAnalogMicFailed" 73 "a073_ECallDigitalMicFailed" 74 "a074_EMMCHangDetected" 75 "a075_BackupCameraInitError" 76 "a076_NumFalseManualECalls" 77 "a077_AudioA2bMicChannelSwap" 78 "a078_DashcamUsbDriveUnmountable" 79 "a079_DashcamUsbDriveFull" 80 "a080_DashcamUsbDriveSlow" 81 "a081_CellModemSearchExpired" 82 "a082_NumModemRebootStuckInECall" 83 "a083_ECallProxyWatchdogTriggered" 84 "a084_SerializerError" 85 "a085_DeserializerError" 86 "a086_TouchEnumerationError" 87 "a087_BmpReset" 88 "a088_CellRemovableSimMissing" 89 "a089_RadioSoftResetError" 90 "a090_RadioPingFailError" 91 "a091_VehicleLinkStall" 92 "a092_updateStarted" 93 "a093_updateEnded" 94 "a094_ModemPowerOnFailure" 95 "a095_CidStorageRunningLow" 96 "a096_VideodPipelineIssueDetected" 97 "a097_AudiodRestarted" 98 "a098_DiskCheckFailure" 99 "a099_eMMCStatusError" 100 "a100_eMMCFTLError" 101 "a101_wifiStackProblem" 102 "a102_A2bDiscoveryFailed" 103 "a103_UsbHubNotEnumerating" 104 "a104_DashcamUsbDriveMissing" 105 "a105_firmwareReinstallRequested" 106 "a106_rebootBackstopTriggered" 107 "a107_DashcamUsbDriveTooBigForVfatFsck" 108 "a108_DashcamUsbDriveGettingFull" 109 "a109_DashcamUsbDriveTooSmall" 110 "a110_DashcamUsbDriveCorrupt" 111 "a111_DashcamUsbDriveWrongPort" 112 "a112_badUSBDevice" 113 "a113_DashcamHasOnboardSentryClips" ;
CM_ BO_ 1429 "ESP32-DualCAN Model3_CH. Seen on this car: 8-byte frames; fit good (bits covered 100%, mux 100%, ranges 100%).";
VAL_ 1429 OCS1P_alertState 0 "CLEARED" 1 "SET" ;
VAL_ 1429 OCS1P_alertID 0 "ALERT_DO_NOT_USE_ZERO" 1 "a001_DriverDoorOpen" 2 "a002_DoorOpen" 3 "a003_TrunkOpen" 4 "a004_FrunkOpen" 5 "a005_HeadlightsOnDoorOpen" 6 "a006_RemoteServiceAlert" 7 "a007_SoftPackConfigMismatch" 8 "a008_TouchScreenError" 9 "a009_SquashfsError" 10 "a010_MapsMissing" 11 "a011_IncorrectMap" 12 "a012_NotOnPrivateProperty" 13 "a013_TPMSHardWarning" 14 "a014_TPMSSoftWarning" 15 "a015_TPMSOverPressureWarning" 16 "a016_TPMSTemperatureWarning" 17 "a017_TPMSSystemFault" 18 "a018_SlipStartOn" 19 "a019_ParkBrakeFault" 20 "a020_SteeringReduced" 21 "a021_RearSeatbeltUnbuckled" 22 "a022_ApeFusesEtc" 23 "a023_CellInternetCheckFailed" 24 "a024_WifiInternetCheckFailed" 25 "a025_WifiOnlineCheckFailed" 26 "a026_ModemResetLoopDetected" 27 "a027_AutoSteerMIA" 28 "a028_FrontTrunkPopupClosed" 29 "a029_ModemMIA" 30 "a030_ModemVMCrash" 31 "a031_BrakeFluidLow" 32 "a032_CellModemRecoveryResets" 33 "a033_ApTrialExpired" 34 "a034_WakeupProblem" 35 "a035_AudioWatchdogKernelError" 36 "a036_AudioWatchdogHfpError" 37 "a037_AudioWatchdogXrunStormError" 38 "a038_AudioWatchdogA2bI2cLockupError" 39 "a039_AudioA2bNeedRediscovery" 40 "a040_HomelinkTransmit" 41 "a041_AudioDmesgXrun" 42 "a042_AudioDmesgRtThrottling" 43 "a043_InvalidMapDataOverride" 44 "a044_AudioDmesgDspException" 45 "a045_ECallNeedsService" 46 "a046_BackupCameraStreamError" 47 "a047_CellRoamingDisallowed" 48 "a048_AudioPremiumAmpCheckFailed" 49 "a049_BrakeShiftRequired" 50 "a050_BackupCameraIPUTimeout" 51 "a051_BackupCameraFrameTimeout" 52 "a052_KernelPanicReported" 53 "a053_QtCarExitError" 54 "a054_AudioBoostPowerBad" 55 "a055_ManualECallDisabled" 56 "a056_ManualECallButtonDisconnected" 57 "a057_CellAntennaDisconnected" 58 "a058_GPSAntennaDisconnected" 59 "a059_ECallSpeakerDisconnected" 60 "a060_ECallMicDisconnected" 61 "a061_SIMTestFailed" 62 "a062_ENSTestFailed" 63 "a063_CellularTestFailed" 64 "a064_ModemFirmwareTestFailed" 65 "a065_WiFiRecoveryReset" 66 "a066_GpuHangDetected" 67 "a067_WarnOnI915" 68 "a068_VideoUnexpectedExit" 69 "a069_VideoUDPTimeout" 70 "a070_VideoPipelineWarning" 71 "a071_VideoPipelineError" 72 "a072_ECallAnalogMicFailed" 73 "a073_ECallDigitalMicFailed" 74 "a074_EMMCHangDetected" 75 "a075_BackupCameraInitError" 76 "a076_NumFalseManualECalls" 77 "a077_AudioA2bMicChannelSwap" 78 "a078_DashcamUsbDriveUnmountable" 79 "a079_DashcamUsbDriveFull" 80 "a080_DashcamUsbDriveSlow" 81 "a081_CellModemSearchExpired" 82 "a082_NumModemRebootStuckInECall" 83 "a083_ECallProxyWatchdogTriggered" 84 "a084_SerializerError" 85 "a085_DeserializerError" 86 "a086_TouchEnumerationError" 87 "a087_BmpReset" 88 "a088_CellRemovableSimMissing" 89 "a089_RadioSoftResetError" 90 "a090_RadioPingFailError" 91 "a091_VehicleLinkStall" 92 "a092_updateStarted" 93 "a093_updateEnded" 94 "a094_ModemPowerOnFailure" 95 "a095_CidStorageRunningLow" 96 "a096_VideodPipelineIssueDetected" 97 "a097_AudiodRestarted" 98 "a098_DiskCheckFailure" 99 "a099_eMMCStatusError" 100 "a100_eMMCFTLError" 101 "a101_wifiStackProblem" 102 "a102_A2bDiscoveryFailed" 103 "a103_UsbHubNotEnumerating" 104 "a104_DashcamUsbDriveMissing" 105 "a105_firmwareReinstallRequested" 106 "a106_rebootBackstopTriggered" 107 "a107_DashcamUsbDriveTooBigForVfatFsck" 108 "a108_DashcamUsbDriveGettingFull" 109 "a109_DashcamUsbDriveTooSmall" 110 "a110_DashcamUsbDriveCorrupt" 111 "a111_DashcamUsbDriveWrongPort" 112 "a112_badUSBDevice" 113 "a113_DashcamHasOnboardSentryClips" ;
CM_ BO_ 1442 "ESP32-DualCAN Model3_VEH. Not seen on this car in the logs.";
VAL_ 1442 VCBATT_silentWakeIBSCurrent 4095 "SNA" ;
CM_ BO_ 1443 "ESP32-DualCAN Model3_VEH. Not seen on this car in the logs.";
